VERSION ""

NS_ :

BS_:

BU_: TCM_Diesel ECM_Diesel BECMB_EPM TCM ECM Generic_BCM GWM _delete APIM BCM DCDC_VQM PAM TSTR PCM

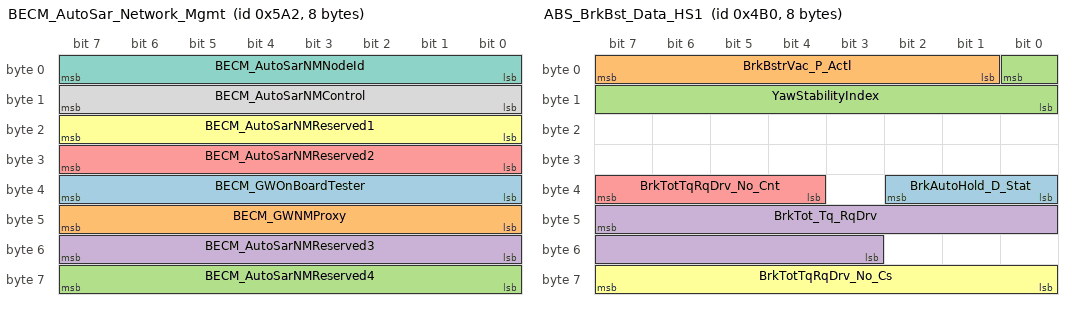
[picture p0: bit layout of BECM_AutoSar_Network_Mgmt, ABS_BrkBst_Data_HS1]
BO_ 1442 BECM_AutoSar_Network_Mgmt: 8 Generic_BCM
 SG_ BECM_GWOnBoardTester : 39|8@0+ (1,0) [0|255] "unitless"  GWM
 SG_ BECM_GWNMProxy : 47|8@0+ (1,0) [0|255] "unitless"  GWM
 SG_ BECM_AutoSarNMReserved4 : 63|8@0+ (1,0) [0|255] "unitless"  GWM
 SG_ BECM_AutoSarNMReserved3 : 55|8@0+ (1,0) [0|255] "unitless"  GWM
 SG_ BECM_AutoSarNMReserved2 : 31|8@0+ (1,0) [0|255] "unitless"  GWM
 SG_ BECM_AutoSarNMReserved1 : 23|8@0+ (1,0) [0|255] "unitless"  GWM
 SG_ BECM_AutoSarNMNodeId : 7|8@0+ (1,0) [0|255] "unitless"  GWM
 SG_ BECM_AutoSarNMControl : 15|8@0+ (1,0) [0|255] "unitless"  GWM

BO_ 1200 ABS_BrkBst_Data_HS1: 8 GWM
 SG_ BrkAutoHold_D_Stat : 34|3@0+ (1,0) [0|7] "SED"  ECM,PCM,ECM_Diesel
 SG_ BrkBstrVac_P_Actl : 7|7@0+ (8,0) [0|1008] "Millibar"  ECM_Diesel,ECM,PCM
 SG_ YawStabilityIndex : 0|9@0+ (1,-256) [-256|255] "%" Vector__XXX
 SG_ BrkTot_Tq_RqDrv : 47|13@0+ (4,0) [0|32760] "Nm"  ECM_Diesel,ECM,PCM
 SG_ BrkTotTqRqDrv_No_Cnt : 39|4@0+ (1,0) [0|15] "unitless"  ECM_Diesel,ECM,PCM
 SG_ BrkTotTqRqDrv_No_Cs : 63|8@0+ (1,0) [0|255] "unitless"  ECM_Diesel,ECM,PCM

BO_ 2015 TesterFunctionalReq_H1: 8 TSTR
 SG_ TesterFunctionalReq : 7|64@0+ (1,0) [0|1.84467E+019] ""  TCM_Diesel,APIM,ECM_Diesel,BECMB_EPM,TCM,ECM,DCDC_VQM,PAM,GWM,PCM,BCM

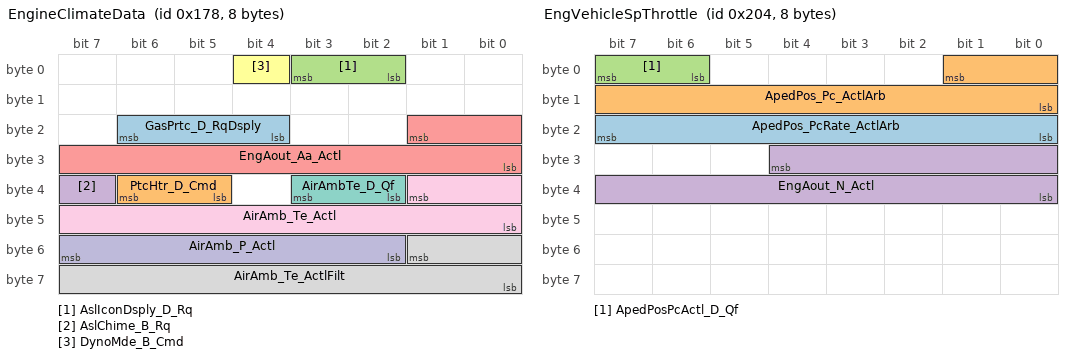
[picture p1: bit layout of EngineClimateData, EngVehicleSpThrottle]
BO_ 376 EngineClimateData: 8 PCM
 SG_ GasPrtc_D_RqDsply : 22|3@0+ (1,0) [0|7] "SED"  GWM
 SG_ PtcHtr_D_Cmd : 38|2@0+ (1,0) [0|3] "SED"  GWM
 SG_ AslIconDsply_D_Rq : 3|2@0+ (1,0) [0|3] "SED"  GWM
 SG_ AslChime_B_Rq : 39|1@0+ (1,0) [0|1] "SED"  GWM
 SG_ EngAout_Aa_Actl : 17|10@0+ (0.05,-25.6) [-25.6|25.55] "rpm/ms"  GWM
 SG_ DynoMde_B_Cmd : 4|1@0+ (1,0) [0|1] "SED"  GWM
 SG_ AirAmbTe_D_Qf : 35|2@0+ (1,0) [0|3] "SED"  GWM,PAM,BCM
 SG_ AirAmb_Te_ActlFilt : 49|10@0+ (0.25,-128) [-128|127.75] "deg C"  PAM,BCM,GWM
 SG_ AirAmb_Te_Actl : 33|10@0+ (0.25,-128) [-128|127.75] "degC"  PAM,GWM,BCM
 SG_ AirAmb_P_Actl : 55|6@0+ (10,500) [500|1110] "mbar"  TCM_Diesel,TCM,GWM,BCM

BO_ 516 EngVehicleSpThrottle: 8 PCM
 SG_ ApedPos_PcRate_ActlArb : 23|8@0+ (0.04,-5) [-5|5.12] "%/ms"  TCM_Diesel,TCM,GWM
 SG_ ApedPos_Pc_ActlArb : 1|10@0+ (0.1,0) [0|102.3] "%"  TCM_Diesel,TCM,BCM,GWM
 SG_ ApedPosPcActl_D_Qf : 7|2@0+ (1,0) [0|3] "SED"  TCM_Diesel,TCM,GWM
 SG_ EngAout_N_Actl : 28|13@0+ (2,0) [0|16382] "rpm"  TCM_Diesel,TCM,BCM,GWM

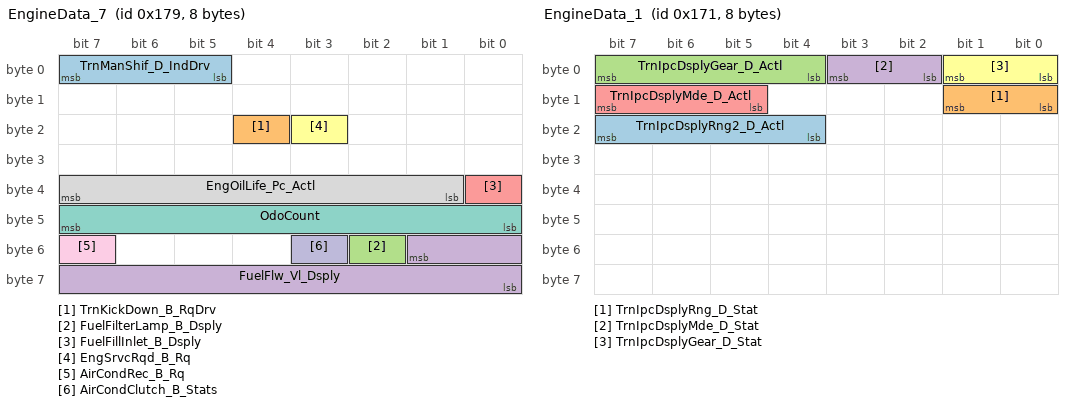
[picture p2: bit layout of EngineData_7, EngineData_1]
BO_ 377 EngineData_7: 8 PCM
 SG_ TrnManShif_D_IndDrv : 7|3@0+ (1,0) [0|7] "Unitless"  GWM
 SG_ TrnKickDown_B_RqDrv : 20|1@0+ (1,0) [0|1] "SED"  GWM
 SG_ FuelFilterLamp_B_Dsply : 50|1@0+ (1,0) [0|1] "SED"  GWM
 SG_ FuelFlw_Vl_Dsply : 49|10@0+ (25,0) [0|25575] "Micro_Liter"  GWM
 SG_ FuelFillInlet_B_Dsply : 32|1@0+ (1,0) [0|1] "SED"  GWM
 SG_ EngSrvcRqd_B_Rq : 19|1@0+ (1,0) [0|1] "SED"  GWM
 SG_ OdoCount : 47|8@0+ (0.2,0) [0|50.8] "Meters"  GWM
 SG_ EngOilLife_Pc_Actl : 39|7@0+ (1,0) [0|100] "Percent"  GWM
 SG_ AirCondRec_B_Rq : 55|1@0+ (1,0) [0|1] "SED"  GWM
 SG_ AirCondClutch_B_Stats : 51|1@0+ (1,0) [0|1] "SED"  GWM

BO_ 369 EngineData_1: 8 PCM
 SG_ TrnIpcDsplyRng2_D_Actl : 23|4@0+ (1,0) [0|15] "SED"  GWM
 SG_ TrnIpcDsplyRng_D_Stat : 9|2@0+ (1,0) [0|3] "SED"  GWM
 SG_ TrnIpcDsplyGear_D_Actl : 7|4@0+ (1,0) [0|15] "SED"  GWM
 SG_ TrnIpcDsplyMde_D_Stat : 3|2@0+ (1,0) [0|3] "SED"  GWM
 SG_ TrnIpcDsplyMde_D_Actl : 15|3@0+ (1,0) [0|7] "SED"  GWM
 SG_ TrnIpcDsplyGear_D_Stat : 1|2@0+ (1,0) [0|3] "SED"  GWM

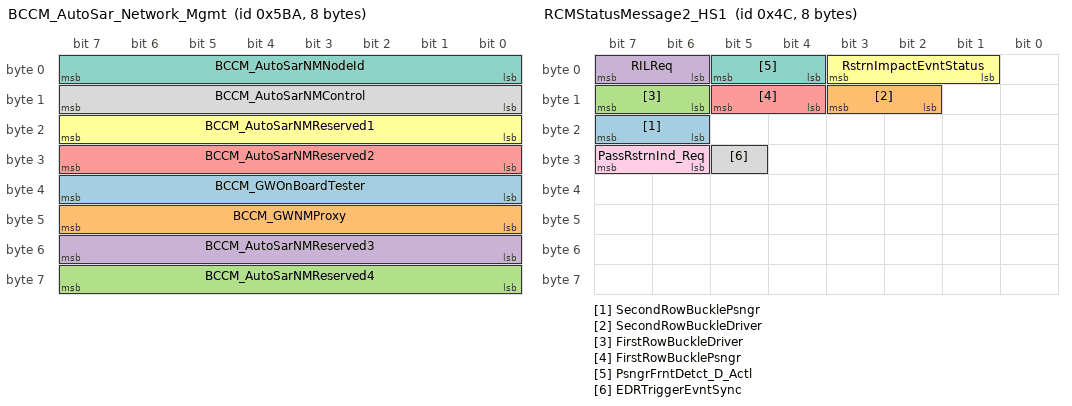
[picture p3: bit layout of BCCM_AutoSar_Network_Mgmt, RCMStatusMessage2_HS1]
BO_ 1466 BCCM_AutoSar_Network_Mgmt: 8 Generic_BCM
 SG_ BCCM_GWOnBoardTester : 39|8@0+ (1,0) [0|255] "unitless" Vector__XXX
 SG_ BCCM_GWNMProxy : 47|8@0+ (1,0) [0|255] "unitless" Vector__XXX
 SG_ BCCM_AutoSarNMReserved4 : 63|8@0+ (1,0) [0|255] "unitless" Vector__XXX
 SG_ BCCM_AutoSarNMReserved3 : 55|8@0+ (1,0) [0|255] "unitless" Vector__XXX
 SG_ BCCM_AutoSarNMReserved2 : 31|8@0+ (1,0) [0|255] "unitless" Vector__XXX
 SG_ BCCM_AutoSarNMReserved1 : 23|8@0+ (1,0) [0|255] "unitless" Vector__XXX
 SG_ BCCM_AutoSarNMNodeId : 7|8@0+ (1,0) [0|255] "unitless" Vector__XXX
 SG_ BCCM_AutoSarNMControl : 15|8@0+ (1,0) [0|255] "unitless" Vector__XXX

BO_ 76 RCMStatusMessage2_HS1: 8 GWM
 SG_ SecondRowBucklePsngr : 23|2@0+ (1,0) [0|3] "SED" Vector__XXX
 SG_ SecondRowBuckleDriver : 11|2@0+ (1,0) [0|3] "SED" Vector__XXX
 SG_ FirstRowBuckleDriver : 15|2@0+ (1,0) [0|3] "SED"  ECM_Diesel,ECM,BCM,PCM
 SG_ RILReq : 7|2@0+ (1,0) [0|3] "SED" Vector__XXX
 SG_ FirstRowBucklePsngr : 13|2@0+ (1,0) [0|3] "SED" Vector__XXX
 SG_ RstrnImpactEvntStatus : 3|3@0+ (1,0) [0|7] "SED"  ECM_Diesel,ECM,BCM,PCM
 SG_ PsngrFrntDetct_D_Actl : 5|2@0+ (1,0) [0|3] "SED" Vector__XXX
 SG_ EDRTriggerEvntSync : 29|1@0+ (1,0) [0|1] "SED" Vector__XXX
 SG_ PassRstrnInd_Req : 31|2@0+ (1,0) [0|3] "SED" Vector__XXX

BO_ 2008 TesterPhysicalResAPIM: 8 APIM
 SG_ TesterPhysicalResAPIM : 7|64@0+ (1,0) [0|1.84467E+019] "unitless"  TSTR

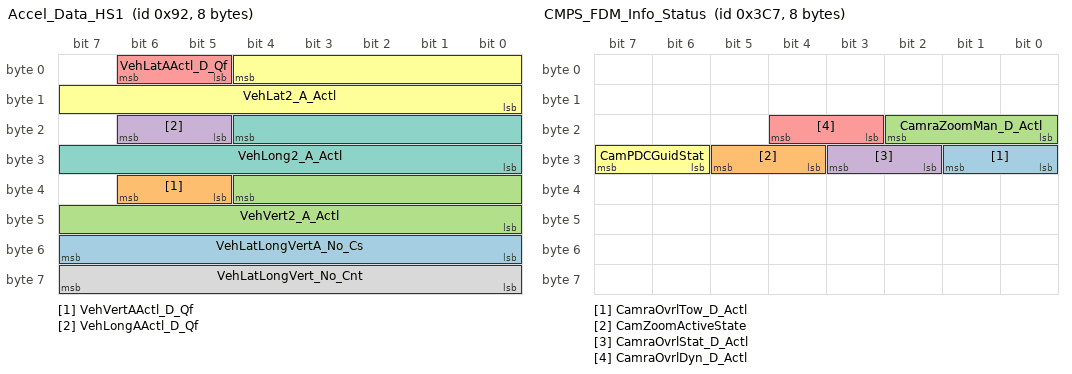
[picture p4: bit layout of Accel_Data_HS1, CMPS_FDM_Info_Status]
BO_ 146 Accel_Data_HS1: 8 GWM
 SG_ VehLatLongVertA_No_Cs : 55|8@0+ (1,0) [0|255] "Unitless" Vector__XXX
 SG_ VehVertAActl_D_Qf : 38|2@0+ (1,0) [0|3] "SED" Vector__XXX
 SG_ VehVert2_A_Actl : 36|13@0+ (0.01,-40) [-40|41.89] "m/s^2" Vector__XXX
 SG_ VehLongAActl_D_Qf : 22|2@0+ (1,0) [0|3] "SED"  ECM_Diesel,PAM
 SG_ VehLatAActl_D_Qf : 6|2@0+ (1,0) [0|3] "SED"  ECM_Diesel
 SG_ VehLat2_A_Actl : 4|13@0+ (0.01,-40) [-40|41.89] "m/s^2"  ECM_Diesel
 SG_ VehLong2_A_Actl : 20|13@0+ (0.01,-40) [-40|41.89] "m/s^2"  ECM_Diesel,PAM
 SG_ VehLatLongVert_No_Cnt : 63|8@0+ (1,0) [0|255] "Unitless" Vector__XXX

BO_ 1870 TesterPhysicalResDCDC: 8 DCDC_VQM
 SG_ TesterPhysicalResDCDC : 7|64@0+ (1,0) [0|1.84467E+019] "unitless"  TSTR

BO_ 1862 TesterPhysicalReqDCDC: 8 TSTR
 SG_ TesterPhysicalReqDCDC : 7|64@0+ (1,0) [0|1.84467E+019] "unitless"  DCDC_VQM

BO_ 1697 PCM_Rapid_Data_Response_2: 8 PCM
 SG_ UUDTPCMResponse2 : 7|64@0+ (1,0) [0|1.844674407371E+019] "unitless"  TSTR

BO_ 1696 PCM_Rapid_Data_Response_1: 8 PCM
 SG_ UUDTPCMResponse1 : 7|64@0+ (1,0) [0|1.844674407371E+019] "unitless"  TSTR

BO_ 967 CMPS_FDM_Info_Status: 8 BCM
 SG_ CamraOvrlTow_D_Actl : 25|2@0+ (1,0) [0|3] "SED"  GWM
 SG_ CamZoomActiveState : 29|2@0+ (1,0) [0|3] "SED"  GWM
 SG_ CamraZoomMan_D_Actl : 18|3@0+ (1,0) [0|7] "SED"  GWM
 SG_ CamraOvrlStat_D_Actl : 27|2@0+ (1,0) [0|3] "SED"  GWM
 SG_ CamraOvrlDyn_D_Actl : 20|2@0+ (1,0) [0|3] "SED"  GWM
 SG_ CamPDCGuidStat : 31|2@0+ (1,0) [0|3] "SED"  GWM

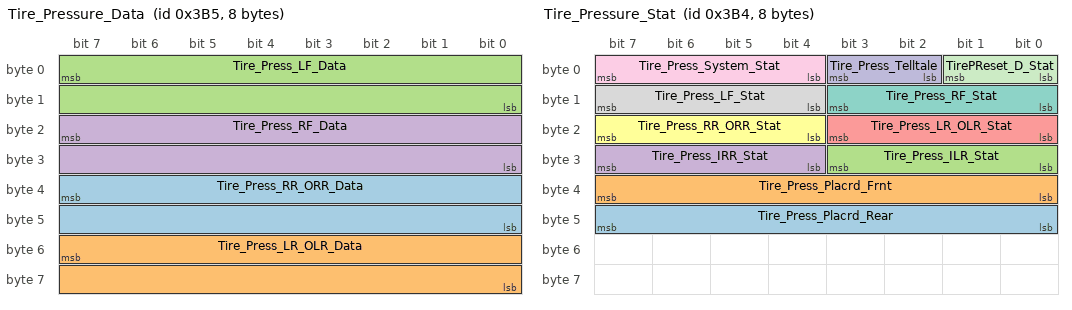
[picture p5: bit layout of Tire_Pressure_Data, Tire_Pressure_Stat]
BO_ 949 Tire_Pressure_Data: 8 BCM
 SG_ Tire_Press_RR_ORR_Data : 39|16@0+ (1,0) [0|65533] "kilopascal"  GWM
 SG_ Tire_Press_LR_OLR_Data : 55|16@0+ (1,0) [0|65533] "kilopascal"  GWM
 SG_ Tire_Press_LF_Data : 7|16@0+ (1,0) [0|65533] "kilopascal"  GWM
 SG_ Tire_Press_RF_Data : 23|16@0+ (1,0) [0|65533] "kilopascal"  GWM

BO_ 948 Tire_Pressure_Stat: 8 BCM
 SG_ Tire_Press_Placrd_Rear : 47|8@0+ (1,0) [0|255] "Unitless"  GWM
 SG_ Tire_Press_Placrd_Frnt : 39|8@0+ (1,0) [0|255] "Unitless"  GWM
 SG_ Tire_Press_ILR_Stat : 27|4@0+ (1,0) [0|15] "SED"  GWM
 SG_ Tire_Press_IRR_Stat : 31|4@0+ (1,0) [0|15] "SED"  GWM
 SG_ Tire_Press_LR_OLR_Stat : 19|4@0+ (1,0) [0|15] "SED"  GWM
 SG_ Tire_Press_RR_ORR_Stat : 23|4@0+ (1,0) [0|15] "SED"  GWM
 SG_ Tire_Press_RF_Stat : 11|4@0+ (1,0) [0|15] "SED"  GWM
 SG_ Tire_Press_LF_Stat : 15|4@0+ (1,0) [0|15] "SED"  GWM
 SG_ Tire_Press_System_Stat : 7|4@0+ (1,0) [0|15] "SED"  GWM
 SG_ Tire_Press_Telltale : 3|2@0+ (1,0) [0|3] "SED"  GWM
 SG_ TirePReset_D_Stat : 1|2@0+ (1,0) [0|3] "Discrete"  GWM

BO_ 1077 Cluster_Info4_HS1: 8 GWM
 SG_ PtDrvMde_D_Rq_UB : 57|1@0+ (1,0) [0|1] "SED" Vector__XXX
 SG_ PtDrvMde_D_Rq : 61|4@0+ (1,0) [0|15] "SED"  ECM,ECM_Diesel
 SG_ TrlrBrkActCnnct_B_Actl_UB : 62|1@0+ (1,0) [0|1] "SED"  ECM,PCM
 SG_ TrlrBrkActCnnct_B_Actl : 63|1@0+ (1,0) [0|1] "SED"  ECM,PCM
 SG_ PrkLckCtlEnbl_D_RqIpc_UB : 48|1@0+ (1,0) [0|1] "SED"  BCM
 SG_ PrkLckCtlEnbl_D_RqIpc : 50|2@0+ (1,0) [0|3] "SED"  BCM
 SG_ AutoRgen_D_Rq_UB : 51|1@0+ (1,0) [0|1] "SED" Vector__XXX
 SG_ AutoRgen_D_Rq : 41|2@0+ (1,0) [0|3] "SED"  ECM_Diesel
 SG_ FuelLvl_Pc_Dsply_UB : 45|1@0+ (1,0) [0|1] "SED" Vector__XXX
 SG_ StopStrtDrvMde_D_RqMnu_UB : 26|1@0+ (1,0) [0|1] "SED" Vector__XXX
 SG_ StopStrtDrvMde_D_RqMnu : 47|2@0+ (1,0) [0|3] "SED"  ECM_Diesel,ECM,PCM
 SG_ PtWakeupActv1_B_Rq : 44|1@0+ (1,0) [0|1] "SED"  BCM
 SG_ PtWakeupActv1_B_Rq_UB : 43|1@0+ (1,0) [0|1] "SED"  BCM
 SG_ PrkAidRear_D_RqDrv : 29|2@0+ (1,0) [0|3] "SED"  PAM
 SG_ PrkAidFront_D_RqDrv : 21|2@0+ (1,0) [0|3] "SED"  PAM
 SG_ PrkAidRear_D_RqDrv_UB : 27|1@0+ (1,0) [0|1] "SED"  PAM
 SG_ PrkAidFront_D_RqDrv_UB : 19|1@0+ (1,0) [0|1] "SED"  PAM
 SG_ Multimedia_System_UB : 30|1@0+ (1,0) [0|1] "SED"  BCM
 SG_ Multimedia_System : 31|1@0+ (1,0) [0|1] "SED"  BCM
 SG_ Remote_Start_Req_UB : 23|1@0+ (1,0) [0|1] "SED"  BCM
 SG_ Remote_Start_Req : 9|2@0+ (1,0) [0|3] "SED"  BCM
 SG_ TurnLampTrlrRr_B_Stat_UB : 16|1@0+ (1,0) [0|1] "SED"  BCM
 SG_ DistanceBarSetting_UB : 12|1@0+ (1,0) [0|1] "SED"  BCM
 SG_ CamraZoomMan_D_Rq_UB : 14|1@0+ (1,0) [0|1] "SED"  BCM
 SG_ CamraOvrlStat_D_Rq_UB : 2|1@0+ (1,0) [0|1] "SED"  BCM
 SG_ CamraOvrlDyn_D_Rq_UB : 4|1@0+ (1,0) [0|1] "SED"  BCM
 SG_ CamAutoTowbarZoom_UB : 6|1@0+ (1,0) [0|1] "SED"  BCM
 SG_ DistanceBarSetting : 13|1@0+ (1,0) [0|1] "SED"  BCM
 SG_ CamraZoomMan_D_Rq : 1|3@0+ (1,0) [0|7] "SED"  BCM
 SG_ CamraOvrlStat_D_Rq : 3|1@0+ (1,0) [0|1] "SED"  BCM
 SG_ CamraOvrlDyn_D_Rq : 5|1@0+ (1,0) [0|1] "SED"  BCM
 SG_ CamAutoTowbarZoom : 7|1@0+ (1,0) [0|1] "SED"  BCM
 SG_ CcdMsgTxt_D_RqDsply : 55|4@0+ (1,0) [0|15] "SED" Vector__XXX
 SG_ PwLftgtIntSw_B_Stat_UB : 10|1@0+ (1,0) [0|1] "SED"  BCM
 SG_ PwLftgtIntSw_B_Stat : 11|1@0+ (1,0) [0|1] "SED"  BCM
 SG_ TurnLampTrlrRl_B_Stat_UB : 18|1@0+ (1,0) [0|1] "SED"  BCM
 SG_ TurnLampTrlrRr_B_Stat : 17|1@0+ (1,0) [0|1] "SED"  BCM
 SG_ TurnLampTrlrRl_B_Stat : 22|1@0+ (1,0) [0|1] "SED"  BCM
 SG_ FuelLvl_Pc_Dsply : 25|10@0+ (0.108696,-5.217408) [-5.217408|105.9786] "Percent"  ECM_Diesel

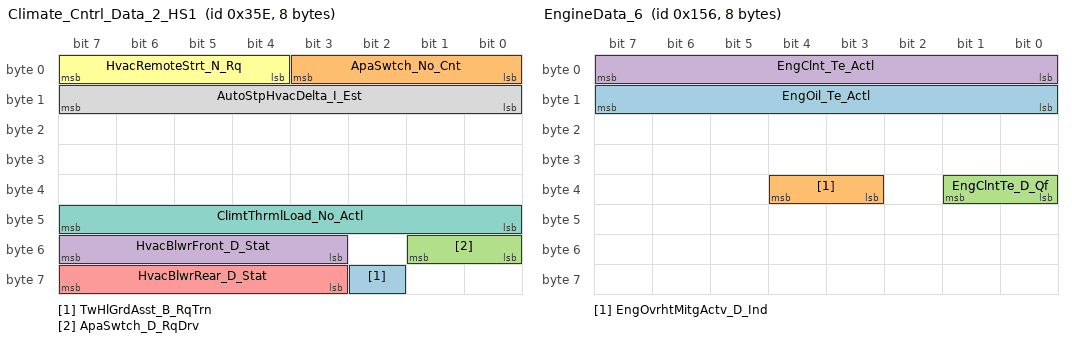
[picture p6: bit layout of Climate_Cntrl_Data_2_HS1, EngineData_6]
BO_ 862 Climate_Cntrl_Data_2_HS1: 8 GWM
 SG_ TwHlGrdAsst_B_RqTrn : 58|1@0+ (1,0) [0|1] "SED" Vector__XXX
 SG_ ApaSwtch_No_Cnt : 3|4@0+ (1,0) [0|15] "Unitless"  PAM
 SG_ ApaSwtch_D_RqDrv : 49|2@0+ (1,0) [0|3] "SED"  PAM
 SG_ HvacBlwrFront_D_Stat : 55|5@0+ (1,0) [0|31] "SED"  ECM_Diesel,PCM,BCM
 SG_ HvacBlwrRear_D_Stat : 63|5@0+ (1,0) [0|31] "SED"  ECM_Diesel,PCM,BCM
 SG_ HvacRemoteStrt_N_Rq : 7|4@0+ (100,450) [450|1950] "RPM"  ECM_Diesel,ECM,PCM
 SG_ ClimtThrmlLoad_No_Actl : 47|8@0+ (1,0) [0|254] "unitless"  ECM_Diesel
 SG_ AutoStpHvacDelta_I_Est : 15|8@0+ (1,-192) [-192|62] "ampere"  BCM

BO_ 342 EngineData_6: 8 PCM
 SG_ EngOil_Te_Actl : 15|8@0+ (1,-60) [-60|193] "degC"  GWM
 SG_ EngOvrhtMitgActv_D_Ind : 36|2@0+ (1,0) [0|3] "SED"  GWM
 SG_ EngClntTe_D_Qf : 33|2@0+ (1,0) [0|3] "SED"  TCM_Diesel,TCM,GWM,BCM
 SG_ EngClnt_Te_Actl : 7|8@0+ (1,-60) [-60|195] "degC"  TCM_Diesel,TCM,GWM,BCM

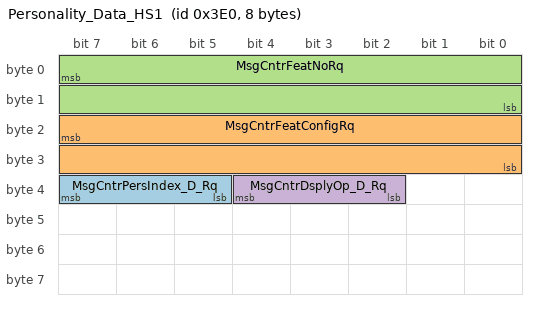
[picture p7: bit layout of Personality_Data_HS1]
BO_ 992 Personality_Data_HS1: 8 GWM
 SG_ MsgCntrPersIndex_D_Rq : 39|3@0+ (1,0) [0|7] "SED"  BCM
 SG_ MsgCntrFeatConfigRq : 23|16@0+ (1,0) [0|65535] "Undefined"  BCM
 SG_ MsgCntrFeatNoRq : 7|16@0+ (1,0) [0|65535] "Number"  BCM
 SG_ MsgCntrDsplyOp_D_Rq : 36|3@0+ (1,0) [0|7] "SED"  BCM

BO_TX_BU_ 376 : ECM_Diesel,ECM,PCM;
BO_TX_BU_ 516 : ECM_Diesel,ECM,PCM;
BO_TX_BU_ 377 : ECM_Diesel,ECM,PCM;
BO_TX_BU_ 369 : TCM_Diesel,TCM,PCM;
BO_TX_BU_ 1697 : ECM_Diesel,ECM,PCM;
BO_TX_BU_ 1696 : ECM_Diesel,ECM,PCM;
BO_TX_BU_ 342 : ECM_Diesel,ECM,PCM;
CM_ SG_ 1442 BECM_GWOnBoardTester "Signal not transmitted on gas, diesel and HEV.  Only supported on PHEV.";
CM_ SG_ 1442 BECM_GWNMProxy "Signal not transmitted on gas, diesel and HEV.  Only supported on PHEV.";
CM_ SG_ 1442 BECM_AutoSarNMReserved4 "Signal not transmitted on gas, diesel and HEV.  Only supported on PHEV.";
CM_ SG_ 1442 BECM_AutoSarNMReserved3 "Signal not transmitted on gas, diesel and HEV.  Only supported on PHEV.";
CM_ SG_ 1442 BECM_AutoSarNMReserved2 "Signal not transmitted on gas, diesel and HEV.  Only supported on PHEV.";
CM_ SG_ 1442 BECM_AutoSarNMReserved1 "Signal not transmitted on gas, diesel and HEV.  Only supported on PHEV.";
CM_ SG_ 1442 BECM_AutoSarNMNodeId "Signal not transmitted on gas, diesel and HEV.  Only supported on PHEV.";
CM_ SG_ 1442 BECM_AutoSarNMControl "Signal not transmitted on gas, diesel and HEV.  Only supported on PHEV.";
CM_ BO_ 2015 "OBDII Request ($7DF) messages are for FNOS 1.0.1 only.
Diagnostic Functional Addressing ($7DF) and Dual Rate Periodic messages are for FNOS I3 only.";
CM_ SG_ 376 GasPrtc_D_RqDsply "ECM_Gas Tx Only, PCM and ECM_Diesel do not support";
CM_ SG_ 376 PtcHtr_D_Cmd "ECM_D Tx on P552";
CM_ SG_ 376 AslIconDsply_D_Rq "Signal not transmitted by gas variants
";
CM_ SG_ 376 AslChime_B_Rq "Signal not transmitted by gas variants";
CM_ SG_ 376 EngAout_Aa_Actl "Signal not transmitted on HEV variants.";
CM_ SG_ 516 ApedPos_Pc_ActlArb "ABSGenSigTimeoutTime=1000";
CM_ SG_ 377 TrnManShif_D_IndDrv "ECM_D Tx only on P552";
CM_ SG_ 377 TrnKickDown_B_RqDrv "ECM_D Tx only on P552
";
CM_ SG_ 377 FuelFilterLamp_B_Dsply "ECM_D Tx only on P552";
CM_ SG_ 377 FuelFlw_Vl_Dsply "Signal not transmitted on diesel variants.";
CM_ SG_ 377 FuelFillInlet_B_Dsply "Signal not transmitted on diesel variants.";
CM_ SG_ 377 OdoCount "Signal not transmitted on diesel variants.";
CM_ SG_ 377 EngOilLife_Pc_Actl "Signal not transmitted on diesel variants.";
CM_ SG_ 377 AirCondRec_B_Rq "Signal not transmitted on diesel variants.";
CM_ SG_ 377 AirCondClutch_B_Stats "Signal not transmitted on diesel variants.";
CM_ SG_ 1466 BCCM_GWOnBoardTester "Signal not transmitted on gas, diesel and HEV.  Only supported on PHEV.";
CM_ SG_ 1466 BCCM_GWNMProxy "Signal not transmitted on gas, diesel and HEV.  Only supported on PHEV.";
CM_ SG_ 1466 BCCM_AutoSarNMReserved4 "Signal not transmitted on gas, diesel and HEV.  Only supported on PHEV.";
CM_ SG_ 1466 BCCM_AutoSarNMReserved3 "Signal not transmitted on gas, diesel and HEV.  Only supported on PHEV.";
CM_ SG_ 1466 BCCM_AutoSarNMReserved2 "Signal not transmitted on gas, diesel and HEV.  Only supported on PHEV.";
CM_ SG_ 1466 BCCM_AutoSarNMReserved1 "Signal not transmitted on gas, diesel and HEV.  Only supported on PHEV.";
CM_ SG_ 1466 BCCM_AutoSarNMNodeId "Signal not transmitted on gas, diesel and HEV.  Only supported on PHEV.";
CM_ SG_ 1466 BCCM_AutoSarNMControl "Signal not transmitted on gas, diesel and HEV.  Only supported on PHEV.";
CM_ BO_ 967 "2008' programs, Tx by IC;  updated on 5/6/05";
CM_ BO_ 949 "For 2010MY and beyond, use for SCT (non-CGEA) and CGEA modules";
CM_ BO_ 948 "$3B4 used by CGEA SPDJB";
CM_ SG_ 342 EngOil_Te_Actl "Tx by ECM_G and ECM_D only";
CM_ SG_ 342 EngOvrhtMitgActv_D_Ind "Signal not transmitted on diesel.";
BA_DEF_ SG_  "U_V408_MY18_Gas_Rx" ENUM  "No","Yes";
BA_DEF_ SG_  "U_V408_MY18_Diesel_Rx" ENUM  "No","Yes";
BA_DEF_ SG_  "U_CD4_MY18_Gas_Tx" ENUM  "No","Yes";
BA_DEF_ SG_  "U_S550_MY18_Gas_Tx" ENUM  "No","Yes";
BA_DEF_ SG_  "U_V408_MY18_Gas_Tx" ENUM  "No","Yes";
BA_DEF_ SG_  "U_V408_MY18_Diesel_Tx" ENUM  "No","Yes";
BA_DEF_ SG_  "U_P552_MY18_5_Diesel_Tx" ENUM  "No","Yes";
BA_DEF_ SG_  "U_U55x_MY18_Gas_Rx" ENUM  "No","Yes";
BA_DEF_ SG_  "U_U55x_MY18_Gas_Tx" ENUM  "No","Yes";
BA_DEF_ BO_  "FrameGatewayNetwork" STRING ;
BA_DEF_ SG_  "U_C489_MY17_Gas_Rx" ENUM  "No","Yes";
BA_DEF_ SG_  "U_CD43_MY17_Gas_Rx" ENUM  "No","Yes";
BA_DEF_ SG_  "U_P552_MY17_Gas_Rx" ENUM  "No","Yes";
BA_DEF_ SG_  "U_B515_MCA_MY17_Diesel_Rx" ENUM  "No","Yes";
BA_DEF_ SG_  "U_B515_MCA_MY17_Gas_Rx" ENUM  "No","Yes";
BA_DEF_ SG_  "U_C489_MY17_Gas_Tx" ENUM  "No","Yes";
BA_DEF_ SG_  "U_CD43_MY17_Gas_Tx" ENUM  "No","Yes";
BA_DEF_ SG_  "U_B515_MCA_MY17_Diesel_Tx" ENUM  "No","Yes";
BA_DEF_ SG_  "U_B515_MCA_MY17_Gas_Tx" ENUM  "No","Yes";
BA_DEF_ SG_  "U_CD4_MY17_Diesel_Rx" ENUM  "No","Yes";
BA_DEF_ SG_  "U_CD4_MY17_Gas_Rx" ENUM  "No","Yes";
BA_DEF_ SG_  "U_CD4_MY17_Hev_Rx" ENUM  "No","Yes";
BA_DEF_ SG_  "U_CD4_MY17_Phev_Rx" ENUM  "No","Yes";
BA_DEF_ SG_  "U_CD42_MY16_Diesel_Rx" ENUM  "No","Yes";
BA_DEF_ SG_  "U_CD42_MY16_Gas_Rx" ENUM  "No","Yes";
BA_DEF_ SG_  "U_CD4_MY17_Gas_Tx" ENUM  "No","Yes";
BA_DEF_ SG_  "U_CD4_MY17_Hev_Tx" ENUM  "No","Yes";
BA_DEF_ SG_  "U_CD4_MY17_Phev_Tx" ENUM  "No","Yes";
BA_DEF_ SG_  "U_CD42_MY16_Diesel_Tx" ENUM  "No","Yes";
BA_DEF_ SG_  "U_CD42_MY16_Gas_Tx" ENUM  "No","Yes";
BA_DEF_ SG_  "U_CD42_MY15_Diesel_Rx" ENUM  "No","Yes";
BA_DEF_ SG_  "U_CD42_MY15_Gas_Rx" ENUM  "No","Yes";
BA_DEF_ SG_  "U_U502_MY16_Gas_Rx" ENUM  "No","Yes";
BA_DEF_ SG_  "U_P558_MY17_Gas_Rx" ENUM  "No","Yes";
BA_DEF_ SG_  "U_P558_MY17_Diesel_Rx" ENUM  "No","Yes";
BA_DEF_ SG_  "U_V36X_MY16_5_Diesel_Rx" ENUM  "No","Yes";
BA_DEF_ SG_  "U_CD42_MY15_Diesel_Tx" ENUM  "No","Yes";
BA_DEF_ SG_  "U_CD42_MY15_Gas_Tx" ENUM  "No","Yes";
BA_DEF_ SG_  "U_P558_MY17_Gas_Tx" ENUM  "No","Yes";
BA_DEF_ SG_  "U_P558_MY17_Diesel_Tx" ENUM  "No","Yes";
BA_DEF_ SG_  "U_V36X_MY16_5_Diesel_Tx" ENUM  "No","Yes";
BA_DEF_ SG_  "GenSigTimeoutTime_TCM" INT 0 100000;
BA_DEF_ SG_  "Gateway_ID" INT 0 0;
BA_DEF_ BO_  "FrameGatewayMS1" HEX 0 1407;
BA_DEF_ BO_  "FrameGatewayHS3" HEX 0 1407;
BA_DEF_ BO_  "FrameGatewayHS2" HEX 0 1407;
BA_DEF_ BO_  "NetworkInitialization" ENUM  "No","Yes";
BA_DEF_ BO_  "FrameGatewayId" HEX 0 1407;
BA_DEF_ BO_  "GenMsgStartDelayTime" INT 0 10000;
BA_DEF_ BO_  "GenMsgDelayTime" INT 0 1000;
BA_DEF_ BO_  "GenMsgCycleTime" INT 0 100000;
BA_DEF_ BO_  "GenMsgSendType" ENUM  "FixedPeriodic","Event","EnabledPeriodic","NotUsed","NotUsed","EventPeriodic","NotUsed","NotUsed","NoMsgSendType";
BA_DEF_ SG_  "U_CD4_MY14_Phev_Tx" ENUM  "No","Yes";
BA_DEF_ SG_  "U_CD4_MY14_Hev_Tx" ENUM  "No","Yes";
BA_DEF_ SG_  "U_CD4_MY14_Gas_Tx" ENUM  "No","Yes";
BA_DEF_ SG_  "U_CD4_MY14_Diesel_Tx" ENUM  "No","Yes";
BA_DEF_ SG_  "U_CD43_MY16_Gas_Tx" ENUM  "No","Yes";
BA_DEF_ SG_  "U_UP375_MY15_Diesel_Tx" ENUM  "No","Yes";
BA_DEF_ SG_  "U_UP375_MY15_Gas_Tx" ENUM  "No","Yes";
BA_DEF_ SG_  "U_U502_MY15_Gas_Tx" ENUM  "No","Yes";
BA_DEF_ SG_  "U_C489_MY14_Gas_Tx" ENUM  "No","Yes";
BA_DEF_ SG_  "U_S550_MY15_Gas_Tx" ENUM  "No","Yes";
BA_DEF_ SG_  "U_P552_MY15_Gas_Tx" ENUM  "No","Yes";
BA_DEF_ SG_  "U_CD42_MY14_Gas_Tx" ENUM  "No","Yes";
BA_DEF_ SG_  "U_CD42_MY14_Diesel_Tx" ENUM  "No","Yes";
BA_DEF_ SG_  "U_CD4_MY13_Phev_Tx" ENUM  "No","Yes";
BA_DEF_ SG_  "U_CD4_MY13_Hev_Tx" ENUM  "No","Yes";
BA_DEF_ SG_  "U_CD4_MY13_Gas_Tx" ENUM  "No","Yes";
BA_DEF_ SG_  "U_CD4_MY13_Diesel_Tx" ENUM  "No","Yes";
BA_DEF_ SG_  "U_CD4_MY14_Phev_Rx" ENUM  "No","Yes";
BA_DEF_ SG_  "U_CD4_MY14_Hev_Rx" ENUM  "No","Yes";
BA_DEF_ SG_  "U_CD4_MY14_Gas_Rx" ENUM  "No","Yes";
BA_DEF_ SG_  "U_CD4_MY14_Diesel_Rx" ENUM  "No","Yes";
BA_DEF_ SG_  "U_CD43_MY16_Gas_Rx" ENUM  "No","Yes";
BA_DEF_ SG_  "U_UP375_MY15_Diesel_Rx" ENUM  "No","Yes";
BA_DEF_ SG_  "U_UP375_MY15_Gas_Rx" ENUM  "No","Yes";
BA_DEF_ SG_  "U_B479_MY15_Gas_Rx" ENUM  "No","Yes";
BA_DEF_ SG_  "U_U502_MY15_Gas_Rx" ENUM  "No","Yes";
BA_DEF_ SG_  "U_C489_MY14_Gas_Rx" ENUM  "No","Yes";
BA_DEF_ SG_  "U_S550_MY15_Gas_Rx" ENUM  "No","Yes";
BA_DEF_ SG_  "U_P552_MY15_Gas_Rx" ENUM  "No","Yes";
BA_DEF_ SG_  "U_CD42_MY14_Gas_Rx" ENUM  "No","Yes";
BA_DEF_ SG_  "U_CD42_MY14_Diesel_Rx" ENUM  "No","Yes";
BA_DEF_ SG_  "U_CD4_MY13_Phev_Rx" ENUM  "No","Yes";
BA_DEF_ SG_  "U_CD4_MY13_Hev_Rx" ENUM  "No","Yes";
BA_DEF_ SG_  "U_CD4_MY13_Gas_Rx" ENUM  "No","Yes";
BA_DEF_ SG_  "U_CD4_MY13_Diesel_Rx" ENUM  "No","Yes";
BA_DEF_ SG_  "ContentDependant" ENUM  "No","Yes";
BA_DEF_ SG_  "GenSigStartValue" INT 0 1000000000;
BA_DEF_ SG_  "CrossOver_LIN" ENUM  "No","Yes";
BA_DEF_ SG_  "CrossOver_InfoCAN" ENUM  "No","Yes";
BA_DEF_ SG_  "WakeupSignal" ENUM  "No","Yes";
BA_DEF_ SG_  "GenSigSendType" ENUM  "Cyclic","OnWrite","vector_leerstring","OnChange","vector_leerstring","IfActive","vector_leerstring","NoSigSendType";
BA_DEF_ BO_  "TpApplType" STRING ;
BA_DEF_ BO_  "DiagState" ENUM  "No","Yes";
BA_DEF_ BO_  "DiagRequest" ENUM  "No","Yes";
BA_DEF_ BO_  "DiagResponse" ENUM  "No","Yes";
BA_DEF_ BO_  "GenMsgILSupport" ENUM  "No","Yes";
BA_DEF_DEF_  "U_V408_MY18_Gas_Rx" "No";
BA_DEF_DEF_  "U_V408_MY18_Diesel_Rx" "No";
BA_DEF_DEF_  "U_CD4_MY18_Gas_Tx" "No";
BA_DEF_DEF_  "U_S550_MY18_Gas_Tx" "No";
BA_DEF_DEF_  "U_V408_MY18_Gas_Tx" "No";
BA_DEF_DEF_  "U_V408_MY18_Diesel_Tx" "No";
BA_DEF_DEF_  "U_P552_MY18_5_Diesel_Tx" "No";
BA_DEF_DEF_  "U_U55x_MY18_Gas_Rx" "No";
BA_DEF_DEF_  "U_U55x_MY18_Gas_Tx" "No";
BA_DEF_DEF_  "FrameGatewayNetwork" "NONE";
BA_DEF_DEF_  "U_C489_MY17_Gas_Rx" "No";
BA_DEF_DEF_  "U_CD43_MY17_Gas_Rx" "No";
BA_DEF_DEF_  "U_P552_MY17_Gas_Rx" "No";
BA_DEF_DEF_  "U_B515_MCA_MY17_Diesel_Rx" "No";
BA_DEF_DEF_  "U_B515_MCA_MY17_Gas_Rx" "No";
BA_DEF_DEF_  "U_C489_MY17_Gas_Tx" "No";
BA_DEF_DEF_  "U_CD43_MY17_Gas_Tx" "No";
BA_DEF_DEF_  "U_B515_MCA_MY17_Diesel_Tx" "No";
BA_DEF_DEF_  "U_B515_MCA_MY17_Gas_Tx" "No";
BA_DEF_DEF_  "U_CD4_MY17_Diesel_Rx" "No";
BA_DEF_DEF_  "U_CD4_MY17_Gas_Rx" "No";
BA_DEF_DEF_  "U_CD4_MY17_Hev_Rx" "No";
BA_DEF_DEF_  "U_CD4_MY17_Phev_Rx" "No";
BA_DEF_DEF_  "U_CD42_MY16_Diesel_Rx" "No";
BA_DEF_DEF_  "U_CD42_MY16_Gas_Rx" "No";
BA_DEF_DEF_  "U_CD4_MY17_Gas_Tx" "No";
BA_DEF_DEF_  "U_CD4_MY17_Hev_Tx" "No";
BA_DEF_DEF_  "U_CD4_MY17_Phev_Tx" "No";
BA_DEF_DEF_  "U_CD42_MY16_Diesel_Tx" "No";
BA_DEF_DEF_  "U_CD42_MY16_Gas_Tx" "No";
BA_DEF_DEF_  "U_CD42_MY15_Diesel_Rx" "No";
BA_DEF_DEF_  "U_CD42_MY15_Gas_Rx" "No";
BA_DEF_DEF_  "U_U502_MY16_Gas_Rx" "No";
BA_DEF_DEF_  "U_P558_MY17_Gas_Rx" "No";
BA_DEF_DEF_  "U_P558_MY17_Diesel_Rx" "No";
BA_DEF_DEF_  "U_V36X_MY16_5_Diesel_Rx" "No";
BA_DEF_DEF_  "U_CD42_MY15_Diesel_Tx" "No";
BA_DEF_DEF_  "U_CD42_MY15_Gas_Tx" "No";
BA_DEF_DEF_  "U_P558_MY17_Gas_Tx" "No";
BA_DEF_DEF_  "U_P558_MY17_Diesel_Tx" "No";
BA_DEF_DEF_  "U_V36X_MY16_5_Diesel_Tx" "No";
BA_DEF_DEF_  "GenSigTimeoutTime_TCM" 5000;
BA_DEF_DEF_  "Gateway_ID" 0;
BA_DEF_DEF_  "FrameGatewayMS1" 0;
BA_DEF_DEF_  "FrameGatewayHS3" 0;
BA_DEF_DEF_  "FrameGatewayHS2" 0;
BA_DEF_DEF_  "NetworkInitialization" "No";
BA_DEF_DEF_  "FrameGatewayId" 0;
BA_DEF_DEF_  "GenMsgStartDelayTime" 0;
BA_DEF_DEF_  "GenMsgDelayTime" 20;
BA_DEF_DEF_  "GenMsgCycleTime" 0;
BA_DEF_DEF_  "GenMsgSendType" "NoMsgSendType";
BA_DEF_DEF_  "U_CD4_MY14_Phev_Tx" "No";
BA_DEF_DEF_  "U_CD4_MY14_Hev_Tx" "No";
BA_DEF_DEF_  "U_CD4_MY14_Gas_Tx" "No";
BA_DEF_DEF_  "U_CD4_MY14_Diesel_Tx" "No";
BA_DEF_DEF_  "U_CD43_MY16_Gas_Tx" "No";
BA_DEF_DEF_  "U_UP375_MY15_Diesel_Tx" "No";
BA_DEF_DEF_  "U_UP375_MY15_Gas_Tx" "No";
BA_DEF_DEF_  "U_U502_MY15_Gas_Tx" "No";
BA_DEF_DEF_  "U_C489_MY14_Gas_Tx" "No";
BA_DEF_DEF_  "U_S550_MY15_Gas_Tx" "No";
BA_DEF_DEF_  "U_P552_MY15_Gas_Tx" "No";
BA_DEF_DEF_  "U_CD42_MY14_Gas_Tx" "No";
BA_DEF_DEF_  "U_CD42_MY14_Diesel_Tx" "No";
BA_DEF_DEF_  "U_CD4_MY13_Phev_Tx" "No";
BA_DEF_DEF_  "U_CD4_MY13_Hev_Tx" "No";
BA_DEF_DEF_  "U_CD4_MY13_Gas_Tx" "No";
BA_DEF_DEF_  "U_CD4_MY13_Diesel_Tx" "No";
BA_DEF_DEF_  "U_CD4_MY14_Phev_Rx" "No";
BA_DEF_DEF_  "U_CD4_MY14_Hev_Rx" "No";
BA_DEF_DEF_  "U_CD4_MY14_Gas_Rx" "No";
BA_DEF_DEF_  "U_CD4_MY14_Diesel_Rx" "No";
BA_DEF_DEF_  "U_CD43_MY16_Gas_Rx" "No";
BA_DEF_DEF_  "U_UP375_MY15_Diesel_Rx" "No";
BA_DEF_DEF_  "U_UP375_MY15_Gas_Rx" "No";
BA_DEF_DEF_  "U_B479_MY15_Gas_Rx" "No";
BA_DEF_DEF_  "U_U502_MY15_Gas_Rx" "No";
BA_DEF_DEF_  "U_C489_MY14_Gas_Rx" "No";
BA_DEF_DEF_  "U_S550_MY15_Gas_Rx" "No";
BA_DEF_DEF_  "U_P552_MY15_Gas_Rx" "No";
BA_DEF_DEF_  "U_CD42_MY14_Gas_Rx" "No";
BA_DEF_DEF_  "U_CD42_MY14_Diesel_Rx" "No";
BA_DEF_DEF_  "U_CD4_MY13_Phev_Rx" "No";
BA_DEF_DEF_  "U_CD4_MY13_Hev_Rx" "No";
BA_DEF_DEF_  "U_CD4_MY13_Gas_Rx" "No";
BA_DEF_DEF_  "U_CD4_MY13_Diesel_Rx" "No";
BA_DEF_DEF_  "ContentDependant" "No";
BA_DEF_DEF_  "GenSigStartValue" 0;
BA_DEF_DEF_  "CrossOver_LIN" "No";
BA_DEF_DEF_  "CrossOver_InfoCAN" "No";
BA_DEF_DEF_  "WakeupSignal" "No";
BA_DEF_DEF_  "GenSigSendType" "NoSigSendType";
BA_DEF_DEF_  "TpApplType" "";
BA_DEF_DEF_  "DiagState" "No";
BA_DEF_DEF_  "DiagRequest" "No";
BA_DEF_DEF_  "DiagResponse" "No";
BA_DEF_DEF_  "GenMsgILSupport" "Yes";
BA_ "GenMsgSendType" BO_ 1442 0;
BA_ "GenMsgCycleTime" BO_ 1442 1000;
BA_ "NetworkInitialization" BO_ 1200 1;
BA_ "FrameGatewayNetwork" BO_ 1200 "HS2_CAN";
BA_ "GenMsgDelayTime" BO_ 1200 10;
BA_ "FrameGatewayId" BO_ 1200 1200;
BA_ "FrameGatewayHS2" BO_ 1200 1200;
BA_ "GenMsgILSupport" BO_ 2015 0;
BA_ "DiagState" BO_ 2015 1;
BA_ "GenMsgSendType" BO_ 2015 1;
BA_ "GenMsgDelayTime" BO_ 2015 0;
BA_ "GenMsgSendType" BO_ 376 0;
BA_ "GenMsgCycleTime" BO_ 376 100;
BA_ "NetworkInitialization" BO_ 376 1;
BA_ "GenMsgSendType" BO_ 516 0;
BA_ "GenMsgCycleTime" BO_ 516 10;
BA_ "GenMsgDelayTime" BO_ 516 0;
BA_ "GenMsgSendType" BO_ 377 0;
BA_ "GenMsgCycleTime" BO_ 377 100;
BA_ "NetworkInitialization" BO_ 377 1;
BA_ "GenMsgSendType" BO_ 369 0;
BA_ "GenMsgCycleTime" BO_ 369 30;
BA_ "GenMsgDelayTime" BO_ 369 10;
BA_ "NetworkInitialization" BO_ 369 1;
BA_ "GenMsgSendType" BO_ 1466 0;
BA_ "GenMsgCycleTime" BO_ 1466 1000;
BA_ "FrameGatewayNetwork" BO_ 76 "HS2_CAN";
BA_ "GenMsgDelayTime" BO_ 76 10;
BA_ "FrameGatewayId" BO_ 76 76;
BA_ "FrameGatewayHS2" BO_ 76 76;
BA_ "GenMsgILSupport" BO_ 2008 0;
BA_ "DiagResponse" BO_ 2008 1;
BA_ "GenMsgSendType" BO_ 2008 1;
BA_ "GenMsgDelayTime" BO_ 2008 0;
BA_ "GenMsgSendType" BO_ 146 1;
BA_ "GenMsgDelayTime" BO_ 146 100;
BA_ "GenMsgILSupport" BO_ 1870 0;
BA_ "DiagResponse" BO_ 1870 1;
BA_ "GenMsgSendType" BO_ 1870 1;
BA_ "GenMsgDelayTime" BO_ 1870 0;
BA_ "GenMsgILSupport" BO_ 1862 0;
BA_ "DiagRequest" BO_ 1862 1;
BA_ "GenMsgSendType" BO_ 1862 1;
BA_ "GenMsgDelayTime" BO_ 1862 0;
BA_ "GenMsgILSupport" BO_ 1697 0;
BA_ "TpApplType" BO_ 1697 "DiagUUDTResponse";
BA_ "GenMsgSendType" BO_ 1697 1;
BA_ "GenMsgILSupport" BO_ 1696 0;
BA_ "TpApplType" BO_ 1696 "DiagUUDTResponse";
BA_ "GenMsgSendType" BO_ 1696 1;
BA_ "GenMsgSendType" BO_ 967 5;
BA_ "GenMsgCycleTime" BO_ 967 1000;
BA_ "GenMsgStartDelayTime" BO_ 967 80;
BA_ "GenMsgSendType" BO_ 949 0;
BA_ "GenMsgCycleTime" BO_ 949 500;
BA_ "GenMsgStartDelayTime" BO_ 949 60;
BA_ "GenMsgSendType" BO_ 948 5;
BA_ "GenMsgCycleTime" BO_ 948 1000;
BA_ "GenMsgStartDelayTime" BO_ 948 50;
BA_ "NetworkInitialization" BO_ 1077 1;
BA_ "GenMsgSendType" BO_ 1077 5;
BA_ "GenMsgCycleTime" BO_ 1077 100;
BA_ "GenMsgStartDelayTime" BO_ 1077 100;
BA_ "FrameGatewayNetwork" BO_ 862 "MS1_CAN";
BA_ "FrameGatewayId" BO_ 862 862;
BA_ "FrameGatewayMS1" BO_ 862 862;
BA_ "GenMsgSendType" BO_ 342 0;
BA_ "GenMsgCycleTime" BO_ 342 100;
BA_ "NetworkInitialization" BO_ 342 1;
BA_ "FrameGatewayNetwork" BO_ 992 "HS3_CAN";
BA_ "FrameGatewayId" BO_ 992 992;
BA_ "FrameGatewayHS3" BO_ 992 992;
BA_ "U_CD42_MY15_Diesel_Rx" SG_ 1442 BECM_GWOnBoardTester 1;
BA_ "U_CD42_MY15_Gas_Rx" SG_ 1442 BECM_GWOnBoardTester 1;
BA_ "U_U502_MY16_Gas_Rx" SG_ 1442 BECM_GWOnBoardTester 1;
BA_ "U_CD4_MY17_Diesel_Rx" SG_ 1442 BECM_GWOnBoardTester 1;
BA_ "U_CD4_MY17_Gas_Rx" SG_ 1442 BECM_GWOnBoardTester 1;
BA_ "U_CD4_MY17_Hev_Rx" SG_ 1442 BECM_GWOnBoardTester 1;
BA_ "U_CD4_MY17_Phev_Rx" SG_ 1442 BECM_GWOnBoardTester 1;
BA_ "U_V36X_MY16_5_Diesel_Rx" SG_ 1442 BECM_GWOnBoardTester 1;
BA_ "U_C489_MY17_Gas_Rx" SG_ 1442 BECM_GWOnBoardTester 1;
BA_ "U_CD42_MY16_Diesel_Rx" SG_ 1442 BECM_GWOnBoardTester 1;
BA_ "U_CD42_MY16_Gas_Rx" SG_ 1442 BECM_GWOnBoardTester 1;
BA_ "U_CD43_MY17_Gas_Rx" SG_ 1442 BECM_GWOnBoardTester 1;
BA_ "U_P552_MY17_Gas_Rx" SG_ 1442 BECM_GWOnBoardTester 1;
BA_ "U_B515_MCA_MY17_Diesel_Rx" SG_ 1442 BECM_GWOnBoardTester 1;
BA_ "U_B515_MCA_MY17_Gas_Rx" SG_ 1442 BECM_GWOnBoardTester 1;
BA_ "U_U55x_MY18_Gas_Rx" SG_ 1442 BECM_GWOnBoardTester 1;
BA_ "U_CD4_MY13_Phev_Tx" SG_ 1442 BECM_GWOnBoardTester 1;
BA_ "U_CD4_MY14_Phev_Tx" SG_ 1442 BECM_GWOnBoardTester 1;
BA_ "U_CD4_MY17_Phev_Tx" SG_ 1442 BECM_GWOnBoardTester 1;
BA_ "GenSigStartValue" SG_ 1442 BECM_GWOnBoardTester 255;
BA_ "ContentDependant" SG_ 1442 BECM_GWOnBoardTester 1;
BA_ "U_CD4_MY13_Diesel_Rx" SG_ 1442 BECM_GWOnBoardTester 1;
BA_ "U_CD4_MY13_Gas_Rx" SG_ 1442 BECM_GWOnBoardTester 1;
BA_ "U_CD4_MY13_Hev_Rx" SG_ 1442 BECM_GWOnBoardTester 1;
BA_ "U_CD4_MY13_Phev_Rx" SG_ 1442 BECM_GWOnBoardTester 1;
BA_ "U_CD42_MY14_Diesel_Rx" SG_ 1442 BECM_GWOnBoardTester 1;
BA_ "U_CD42_MY14_Gas_Rx" SG_ 1442 BECM_GWOnBoardTester 1;
BA_ "U_P552_MY15_Gas_Rx" SG_ 1442 BECM_GWOnBoardTester 1;
BA_ "U_S550_MY15_Gas_Rx" SG_ 1442 BECM_GWOnBoardTester 1;
BA_ "U_C489_MY14_Gas_Rx" SG_ 1442 BECM_GWOnBoardTester 1;
BA_ "U_U502_MY15_Gas_Rx" SG_ 1442 BECM_GWOnBoardTester 1;
BA_ "U_UP375_MY15_Gas_Rx" SG_ 1442 BECM_GWOnBoardTester 1;
BA_ "U_UP375_MY15_Diesel_Rx" SG_ 1442 BECM_GWOnBoardTester 1;
BA_ "U_CD43_MY16_Gas_Rx" SG_ 1442 BECM_GWOnBoardTester 1;
BA_ "U_CD4_MY14_Diesel_Rx" SG_ 1442 BECM_GWOnBoardTester 1;
BA_ "U_CD4_MY14_Gas_Rx" SG_ 1442 BECM_GWOnBoardTester 1;
BA_ "U_CD4_MY14_Hev_Rx" SG_ 1442 BECM_GWOnBoardTester 1;
BA_ "U_CD4_MY14_Phev_Rx" SG_ 1442 BECM_GWOnBoardTester 1;
BA_ "U_CD42_MY15_Diesel_Rx" SG_ 1442 BECM_GWNMProxy 1;
BA_ "U_CD42_MY15_Gas_Rx" SG_ 1442 BECM_GWNMProxy 1;
BA_ "U_U502_MY16_Gas_Rx" SG_ 1442 BECM_GWNMProxy 1;
BA_ "U_CD4_MY17_Diesel_Rx" SG_ 1442 BECM_GWNMProxy 1;
BA_ "U_CD4_MY17_Gas_Rx" SG_ 1442 BECM_GWNMProxy 1;
BA_ "U_CD4_MY17_Hev_Rx" SG_ 1442 BECM_GWNMProxy 1;
BA_ "U_CD4_MY17_Phev_Rx" SG_ 1442 BECM_GWNMProxy 1;
BA_ "U_V36X_MY16_5_Diesel_Rx" SG_ 1442 BECM_GWNMProxy 1;
BA_ "U_C489_MY17_Gas_Rx" SG_ 1442 BECM_GWNMProxy 1;
BA_ "U_CD42_MY16_Diesel_Rx" SG_ 1442 BECM_GWNMProxy 1;
BA_ "U_CD42_MY16_Gas_Rx" SG_ 1442 BECM_GWNMProxy 1;
BA_ "U_CD43_MY17_Gas_Rx" SG_ 1442 BECM_GWNMProxy 1;
BA_ "U_P552_MY17_Gas_Rx" SG_ 1442 BECM_GWNMProxy 1;
BA_ "U_B515_MCA_MY17_Diesel_Rx" SG_ 1442 BECM_GWNMProxy 1;
BA_ "U_B515_MCA_MY17_Gas_Rx" SG_ 1442 BECM_GWNMProxy 1;
BA_ "U_U55x_MY18_Gas_Rx" SG_ 1442 BECM_GWNMProxy 1;
BA_ "U_CD4_MY13_Phev_Tx" SG_ 1442 BECM_GWNMProxy 1;
BA_ "U_CD4_MY14_Phev_Tx" SG_ 1442 BECM_GWNMProxy 1;
BA_ "U_CD4_MY17_Phev_Tx" SG_ 1442 BECM_GWNMProxy 1;
BA_ "GenSigStartValue" SG_ 1442 BECM_GWNMProxy 255;
BA_ "ContentDependant" SG_ 1442 BECM_GWNMProxy 1;
BA_ "U_CD4_MY13_Diesel_Rx" SG_ 1442 BECM_GWNMProxy 1;
BA_ "U_CD4_MY13_Gas_Rx" SG_ 1442 BECM_GWNMProxy 1;
BA_ "U_CD4_MY13_Hev_Rx" SG_ 1442 BECM_GWNMProxy 1;
BA_ "U_CD4_MY13_Phev_Rx" SG_ 1442 BECM_GWNMProxy 1;
BA_ "U_CD42_MY14_Diesel_Rx" SG_ 1442 BECM_GWNMProxy 1;
BA_ "U_CD42_MY14_Gas_Rx" SG_ 1442 BECM_GWNMProxy 1;
BA_ "U_P552_MY15_Gas_Rx" SG_ 1442 BECM_GWNMProxy 1;
BA_ "U_S550_MY15_Gas_Rx" SG_ 1442 BECM_GWNMProxy 1;
BA_ "U_C489_MY14_Gas_Rx" SG_ 1442 BECM_GWNMProxy 1;
BA_ "U_U502_MY15_Gas_Rx" SG_ 1442 BECM_GWNMProxy 1;
BA_ "U_UP375_MY15_Gas_Rx" SG_ 1442 BECM_GWNMProxy 1;
BA_ "U_UP375_MY15_Diesel_Rx" SG_ 1442 BECM_GWNMProxy 1;
BA_ "U_CD43_MY16_Gas_Rx" SG_ 1442 BECM_GWNMProxy 1;
BA_ "U_CD4_MY14_Diesel_Rx" SG_ 1442 BECM_GWNMProxy 1;
BA_ "U_CD4_MY14_Gas_Rx" SG_ 1442 BECM_GWNMProxy 1;
BA_ "U_CD4_MY14_Hev_Rx" SG_ 1442 BECM_GWNMProxy 1;
BA_ "U_CD4_MY14_Phev_Rx" SG_ 1442 BECM_GWNMProxy 1;
BA_ "U_CD42_MY15_Diesel_Rx" SG_ 1442 BECM_AutoSarNMReserved4 1;
BA_ "U_CD42_MY15_Gas_Rx" SG_ 1442 BECM_AutoSarNMReserved4 1;
BA_ "U_U502_MY16_Gas_Rx" SG_ 1442 BECM_AutoSarNMReserved4 1;
BA_ "U_CD4_MY17_Diesel_Rx" SG_ 1442 BECM_AutoSarNMReserved4 1;
BA_ "U_CD4_MY17_Gas_Rx" SG_ 1442 BECM_AutoSarNMReserved4 1;
BA_ "U_CD4_MY17_Hev_Rx" SG_ 1442 BECM_AutoSarNMReserved4 1;
BA_ "U_CD4_MY17_Phev_Rx" SG_ 1442 BECM_AutoSarNMReserved4 1;
BA_ "U_V36X_MY16_5_Diesel_Rx" SG_ 1442 BECM_AutoSarNMReserved4 1;
BA_ "U_C489_MY17_Gas_Rx" SG_ 1442 BECM_AutoSarNMReserved4 1;
BA_ "U_CD42_MY16_Diesel_Rx" SG_ 1442 BECM_AutoSarNMReserved4 1;
BA_ "U_CD42_MY16_Gas_Rx" SG_ 1442 BECM_AutoSarNMReserved4 1;
BA_ "U_CD43_MY17_Gas_Rx" SG_ 1442 BECM_AutoSarNMReserved4 1;
BA_ "U_P552_MY17_Gas_Rx" SG_ 1442 BECM_AutoSarNMReserved4 1;
BA_ "U_B515_MCA_MY17_Diesel_Rx" SG_ 1442 BECM_AutoSarNMReserved4 1;
BA_ "U_B515_MCA_MY17_Gas_Rx" SG_ 1442 BECM_AutoSarNMReserved4 1;
BA_ "U_U55x_MY18_Gas_Rx" SG_ 1442 BECM_AutoSarNMReserved4 1;
BA_ "U_CD4_MY13_Phev_Tx" SG_ 1442 BECM_AutoSarNMReserved4 1;
BA_ "U_CD4_MY14_Phev_Tx" SG_ 1442 BECM_AutoSarNMReserved4 1;
BA_ "U_CD4_MY17_Phev_Tx" SG_ 1442 BECM_AutoSarNMReserved4 1;
BA_ "GenSigStartValue" SG_ 1442 BECM_AutoSarNMReserved4 255;
BA_ "ContentDependant" SG_ 1442 BECM_AutoSarNMReserved4 1;
BA_ "U_CD4_MY13_Diesel_Rx" SG_ 1442 BECM_AutoSarNMReserved4 1;
BA_ "U_CD4_MY13_Gas_Rx" SG_ 1442 BECM_AutoSarNMReserved4 1;
BA_ "U_CD4_MY13_Hev_Rx" SG_ 1442 BECM_AutoSarNMReserved4 1;
BA_ "U_CD4_MY13_Phev_Rx" SG_ 1442 BECM_AutoSarNMReserved4 1;
BA_ "U_CD42_MY14_Diesel_Rx" SG_ 1442 BECM_AutoSarNMReserved4 1;
BA_ "U_CD42_MY14_Gas_Rx" SG_ 1442 BECM_AutoSarNMReserved4 1;
BA_ "U_P552_MY15_Gas_Rx" SG_ 1442 BECM_AutoSarNMReserved4 1;
BA_ "U_S550_MY15_Gas_Rx" SG_ 1442 BECM_AutoSarNMReserved4 1;
BA_ "U_C489_MY14_Gas_Rx" SG_ 1442 BECM_AutoSarNMReserved4 1;
BA_ "U_U502_MY15_Gas_Rx" SG_ 1442 BECM_AutoSarNMReserved4 1;
BA_ "U_UP375_MY15_Gas_Rx" SG_ 1442 BECM_AutoSarNMReserved4 1;
BA_ "U_UP375_MY15_Diesel_Rx" SG_ 1442 BECM_AutoSarNMReserved4 1;
BA_ "U_CD43_MY16_Gas_Rx" SG_ 1442 BECM_AutoSarNMReserved4 1;
BA_ "U_CD4_MY14_Diesel_Rx" SG_ 1442 BECM_AutoSarNMReserved4 1;
BA_ "U_CD4_MY14_Gas_Rx" SG_ 1442 BECM_AutoSarNMReserved4 1;
BA_ "U_CD4_MY14_Hev_Rx" SG_ 1442 BECM_AutoSarNMReserved4 1;
BA_ "U_CD4_MY14_Phev_Rx" SG_ 1442 BECM_AutoSarNMReserved4 1;
BA_ "U_CD42_MY15_Diesel_Rx" SG_ 1442 BECM_AutoSarNMReserved3 1;
BA_ "U_CD42_MY15_Gas_Rx" SG_ 1442 BECM_AutoSarNMReserved3 1;
BA_ "U_U502_MY16_Gas_Rx" SG_ 1442 BECM_AutoSarNMReserved3 1;
BA_ "U_CD4_MY17_Diesel_Rx" SG_ 1442 BECM_AutoSarNMReserved3 1;
BA_ "U_CD4_MY17_Gas_Rx" SG_ 1442 BECM_AutoSarNMReserved3 1;
BA_ "U_CD4_MY17_Hev_Rx" SG_ 1442 BECM_AutoSarNMReserved3 1;
BA_ "U_CD4_MY17_Phev_Rx" SG_ 1442 BECM_AutoSarNMReserved3 1;
BA_ "U_V36X_MY16_5_Diesel_Rx" SG_ 1442 BECM_AutoSarNMReserved3 1;
BA_ "U_C489_MY17_Gas_Rx" SG_ 1442 BECM_AutoSarNMReserved3 1;
BA_ "U_CD42_MY16_Diesel_Rx" SG_ 1442 BECM_AutoSarNMReserved3 1;
BA_ "U_CD42_MY16_Gas_Rx" SG_ 1442 BECM_AutoSarNMReserved3 1;
BA_ "U_CD43_MY17_Gas_Rx" SG_ 1442 BECM_AutoSarNMReserved3 1;
BA_ "U_P552_MY17_Gas_Rx" SG_ 1442 BECM_AutoSarNMReserved3 1;
BA_ "U_B515_MCA_MY17_Diesel_Rx" SG_ 1442 BECM_AutoSarNMReserved3 1;
BA_ "U_B515_MCA_MY17_Gas_Rx" SG_ 1442 BECM_AutoSarNMReserved3 1;
BA_ "U_U55x_MY18_Gas_Rx" SG_ 1442 BECM_AutoSarNMReserved3 1;
BA_ "U_CD4_MY13_Phev_Tx" SG_ 1442 BECM_AutoSarNMReserved3 1;
BA_ "U_CD4_MY14_Phev_Tx" SG_ 1442 BECM_AutoSarNMReserved3 1;
BA_ "U_CD4_MY17_Phev_Tx" SG_ 1442 BECM_AutoSarNMReserved3 1;
BA_ "GenSigStartValue" SG_ 1442 BECM_AutoSarNMReserved3 255;
BA_ "ContentDependant" SG_ 1442 BECM_AutoSarNMReserved3 1;
BA_ "U_CD4_MY13_Diesel_Rx" SG_ 1442 BECM_AutoSarNMReserved3 1;
BA_ "U_CD4_MY13_Gas_Rx" SG_ 1442 BECM_AutoSarNMReserved3 1;
BA_ "U_CD4_MY13_Hev_Rx" SG_ 1442 BECM_AutoSarNMReserved3 1;
BA_ "U_CD4_MY13_Phev_Rx" SG_ 1442 BECM_AutoSarNMReserved3 1;
BA_ "U_CD42_MY14_Diesel_Rx" SG_ 1442 BECM_AutoSarNMReserved3 1;
BA_ "U_CD42_MY14_Gas_Rx" SG_ 1442 BECM_AutoSarNMReserved3 1;
BA_ "U_P552_MY15_Gas_Rx" SG_ 1442 BECM_AutoSarNMReserved3 1;
BA_ "U_S550_MY15_Gas_Rx" SG_ 1442 BECM_AutoSarNMReserved3 1;
BA_ "U_C489_MY14_Gas_Rx" SG_ 1442 BECM_AutoSarNMReserved3 1;
BA_ "U_U502_MY15_Gas_Rx" SG_ 1442 BECM_AutoSarNMReserved3 1;
BA_ "U_UP375_MY15_Gas_Rx" SG_ 1442 BECM_AutoSarNMReserved3 1;
BA_ "U_UP375_MY15_Diesel_Rx" SG_ 1442 BECM_AutoSarNMReserved3 1;
BA_ "U_CD43_MY16_Gas_Rx" SG_ 1442 BECM_AutoSarNMReserved3 1;
BA_ "U_CD4_MY14_Diesel_Rx" SG_ 1442 BECM_AutoSarNMReserved3 1;
BA_ "U_CD4_MY14_Gas_Rx" SG_ 1442 BECM_AutoSarNMReserved3 1;
BA_ "U_CD4_MY14_Hev_Rx" SG_ 1442 BECM_AutoSarNMReserved3 1;
BA_ "U_CD4_MY14_Phev_Rx" SG_ 1442 BECM_AutoSarNMReserved3 1;
BA_ "U_CD42_MY15_Diesel_Rx" SG_ 1442 BECM_AutoSarNMReserved2 1;
BA_ "U_CD42_MY15_Gas_Rx" SG_ 1442 BECM_AutoSarNMReserved2 1;
BA_ "U_U502_MY16_Gas_Rx" SG_ 1442 BECM_AutoSarNMReserved2 1;
BA_ "U_CD4_MY17_Diesel_Rx" SG_ 1442 BECM_AutoSarNMReserved2 1;
BA_ "U_CD4_MY17_Gas_Rx" SG_ 1442 BECM_AutoSarNMReserved2 1;
BA_ "U_CD4_MY17_Hev_Rx" SG_ 1442 BECM_AutoSarNMReserved2 1;
BA_ "U_CD4_MY17_Phev_Rx" SG_ 1442 BECM_AutoSarNMReserved2 1;
BA_ "U_V36X_MY16_5_Diesel_Rx" SG_ 1442 BECM_AutoSarNMReserved2 1;
BA_ "U_C489_MY17_Gas_Rx" SG_ 1442 BECM_AutoSarNMReserved2 1;
BA_ "U_CD42_MY16_Diesel_Rx" SG_ 1442 BECM_AutoSarNMReserved2 1;
BA_ "U_CD42_MY16_Gas_Rx" SG_ 1442 BECM_AutoSarNMReserved2 1;
BA_ "U_CD43_MY17_Gas_Rx" SG_ 1442 BECM_AutoSarNMReserved2 1;
BA_ "U_P552_MY17_Gas_Rx" SG_ 1442 BECM_AutoSarNMReserved2 1;
BA_ "U_B515_MCA_MY17_Diesel_Rx" SG_ 1442 BECM_AutoSarNMReserved2 1;
BA_ "U_B515_MCA_MY17_Gas_Rx" SG_ 1442 BECM_AutoSarNMReserved2 1;
BA_ "U_U55x_MY18_Gas_Rx" SG_ 1442 BECM_AutoSarNMReserved2 1;
BA_ "U_CD4_MY13_Phev_Tx" SG_ 1442 BECM_AutoSarNMReserved2 1;
BA_ "U_CD4_MY14_Phev_Tx" SG_ 1442 BECM_AutoSarNMReserved2 1;
BA_ "U_CD4_MY17_Phev_Tx" SG_ 1442 BECM_AutoSarNMReserved2 1;
BA_ "GenSigStartValue" SG_ 1442 BECM_AutoSarNMReserved2 255;
BA_ "ContentDependant" SG_ 1442 BECM_AutoSarNMReserved2 1;
BA_ "U_CD4_MY13_Diesel_Rx" SG_ 1442 BECM_AutoSarNMReserved2 1;
BA_ "U_CD4_MY13_Gas_Rx" SG_ 1442 BECM_AutoSarNMReserved2 1;
BA_ "U_CD4_MY13_Hev_Rx" SG_ 1442 BECM_AutoSarNMReserved2 1;
BA_ "U_CD4_MY13_Phev_Rx" SG_ 1442 BECM_AutoSarNMReserved2 1;
BA_ "U_CD42_MY14_Diesel_Rx" SG_ 1442 BECM_AutoSarNMReserved2 1;
BA_ "U_CD42_MY14_Gas_Rx" SG_ 1442 BECM_AutoSarNMReserved2 1;
BA_ "U_P552_MY15_Gas_Rx" SG_ 1442 BECM_AutoSarNMReserved2 1;
BA_ "U_S550_MY15_Gas_Rx" SG_ 1442 BECM_AutoSarNMReserved2 1;
BA_ "U_C489_MY14_Gas_Rx" SG_ 1442 BECM_AutoSarNMReserved2 1;
BA_ "U_U502_MY15_Gas_Rx" SG_ 1442 BECM_AutoSarNMReserved2 1;
BA_ "U_UP375_MY15_Gas_Rx" SG_ 1442 BECM_AutoSarNMReserved2 1;
BA_ "U_UP375_MY15_Diesel_Rx" SG_ 1442 BECM_AutoSarNMReserved2 1;
BA_ "U_CD43_MY16_Gas_Rx" SG_ 1442 BECM_AutoSarNMReserved2 1;
BA_ "U_CD4_MY14_Diesel_Rx" SG_ 1442 BECM_AutoSarNMReserved2 1;
BA_ "U_CD4_MY14_Gas_Rx" SG_ 1442 BECM_AutoSarNMReserved2 1;
BA_ "U_CD4_MY14_Hev_Rx" SG_ 1442 BECM_AutoSarNMReserved2 1;
BA_ "U_CD4_MY14_Phev_Rx" SG_ 1442 BECM_AutoSarNMReserved2 1;
BA_ "U_CD42_MY15_Diesel_Rx" SG_ 1442 BECM_AutoSarNMReserved1 1;
BA_ "U_CD42_MY15_Gas_Rx" SG_ 1442 BECM_AutoSarNMReserved1 1;
BA_ "U_U502_MY16_Gas_Rx" SG_ 1442 BECM_AutoSarNMReserved1 1;
BA_ "U_CD4_MY17_Diesel_Rx" SG_ 1442 BECM_AutoSarNMReserved1 1;
BA_ "U_CD4_MY17_Gas_Rx" SG_ 1442 BECM_AutoSarNMReserved1 1;
BA_ "U_CD4_MY17_Hev_Rx" SG_ 1442 BECM_AutoSarNMReserved1 1;
BA_ "U_CD4_MY17_Phev_Rx" SG_ 1442 BECM_AutoSarNMReserved1 1;
BA_ "U_V36X_MY16_5_Diesel_Rx" SG_ 1442 BECM_AutoSarNMReserved1 1;
BA_ "U_C489_MY17_Gas_Rx" SG_ 1442 BECM_AutoSarNMReserved1 1;
BA_ "U_CD42_MY16_Diesel_Rx" SG_ 1442 BECM_AutoSarNMReserved1 1;
BA_ "U_CD42_MY16_Gas_Rx" SG_ 1442 BECM_AutoSarNMReserved1 1;
BA_ "U_CD43_MY17_Gas_Rx" SG_ 1442 BECM_AutoSarNMReserved1 1;
BA_ "U_P552_MY17_Gas_Rx" SG_ 1442 BECM_AutoSarNMReserved1 1;
BA_ "U_B515_MCA_MY17_Diesel_Rx" SG_ 1442 BECM_AutoSarNMReserved1 1;
BA_ "U_B515_MCA_MY17_Gas_Rx" SG_ 1442 BECM_AutoSarNMReserved1 1;
BA_ "U_U55x_MY18_Gas_Rx" SG_ 1442 BECM_AutoSarNMReserved1 1;
BA_ "U_CD4_MY13_Phev_Tx" SG_ 1442 BECM_AutoSarNMReserved1 1;
BA_ "U_CD4_MY14_Phev_Tx" SG_ 1442 BECM_AutoSarNMReserved1 1;
BA_ "U_CD4_MY17_Phev_Tx" SG_ 1442 BECM_AutoSarNMReserved1 1;
BA_ "GenSigStartValue" SG_ 1442 BECM_AutoSarNMReserved1 255;
BA_ "ContentDependant" SG_ 1442 BECM_AutoSarNMReserved1 1;
BA_ "U_CD4_MY13_Diesel_Rx" SG_ 1442 BECM_AutoSarNMReserved1 1;
BA_ "U_CD4_MY13_Gas_Rx" SG_ 1442 BECM_AutoSarNMReserved1 1;
BA_ "U_CD4_MY13_Hev_Rx" SG_ 1442 BECM_AutoSarNMReserved1 1;
BA_ "U_CD4_MY13_Phev_Rx" SG_ 1442 BECM_AutoSarNMReserved1 1;
BA_ "U_CD42_MY14_Diesel_Rx" SG_ 1442 BECM_AutoSarNMReserved1 1;
BA_ "U_CD42_MY14_Gas_Rx" SG_ 1442 BECM_AutoSarNMReserved1 1;
BA_ "U_P552_MY15_Gas_Rx" SG_ 1442 BECM_AutoSarNMReserved1 1;
BA_ "U_S550_MY15_Gas_Rx" SG_ 1442 BECM_AutoSarNMReserved1 1;
BA_ "U_C489_MY14_Gas_Rx" SG_ 1442 BECM_AutoSarNMReserved1 1;
BA_ "U_U502_MY15_Gas_Rx" SG_ 1442 BECM_AutoSarNMReserved1 1;
BA_ "U_UP375_MY15_Gas_Rx" SG_ 1442 BECM_AutoSarNMReserved1 1;
BA_ "U_UP375_MY15_Diesel_Rx" SG_ 1442 BECM_AutoSarNMReserved1 1;
BA_ "U_CD43_MY16_Gas_Rx" SG_ 1442 BECM_AutoSarNMReserved1 1;
BA_ "U_CD4_MY14_Diesel_Rx" SG_ 1442 BECM_AutoSarNMReserved1 1;
BA_ "U_CD4_MY14_Gas_Rx" SG_ 1442 BECM_AutoSarNMReserved1 1;
BA_ "U_CD4_MY14_Hev_Rx" SG_ 1442 BECM_AutoSarNMReserved1 1;
BA_ "U_CD4_MY14_Phev_Rx" SG_ 1442 BECM_AutoSarNMReserved1 1;
BA_ "GenSigStartValue" SG_ 1442 BECM_AutoSarNMNodeId 162;
BA_ "U_CD42_MY15_Diesel_Rx" SG_ 1442 BECM_AutoSarNMNodeId 1;
BA_ "U_CD42_MY15_Gas_Rx" SG_ 1442 BECM_AutoSarNMNodeId 1;
BA_ "U_U502_MY16_Gas_Rx" SG_ 1442 BECM_AutoSarNMNodeId 1;
BA_ "U_CD4_MY17_Diesel_Rx" SG_ 1442 BECM_AutoSarNMNodeId 1;
BA_ "U_CD4_MY17_Gas_Rx" SG_ 1442 BECM_AutoSarNMNodeId 1;
BA_ "U_CD4_MY17_Hev_Rx" SG_ 1442 BECM_AutoSarNMNodeId 1;
BA_ "U_CD4_MY17_Phev_Rx" SG_ 1442 BECM_AutoSarNMNodeId 1;
BA_ "U_V36X_MY16_5_Diesel_Rx" SG_ 1442 BECM_AutoSarNMNodeId 1;
BA_ "U_C489_MY17_Gas_Rx" SG_ 1442 BECM_AutoSarNMNodeId 1;
BA_ "U_CD42_MY16_Diesel_Rx" SG_ 1442 BECM_AutoSarNMNodeId 1;
BA_ "U_CD42_MY16_Gas_Rx" SG_ 1442 BECM_AutoSarNMNodeId 1;
BA_ "U_CD43_MY17_Gas_Rx" SG_ 1442 BECM_AutoSarNMNodeId 1;
BA_ "U_P552_MY17_Gas_Rx" SG_ 1442 BECM_AutoSarNMNodeId 1;
BA_ "U_B515_MCA_MY17_Diesel_Rx" SG_ 1442 BECM_AutoSarNMNodeId 1;
BA_ "U_B515_MCA_MY17_Gas_Rx" SG_ 1442 BECM_AutoSarNMNodeId 1;
BA_ "U_U55x_MY18_Gas_Rx" SG_ 1442 BECM_AutoSarNMNodeId 1;
BA_ "U_CD4_MY13_Phev_Tx" SG_ 1442 BECM_AutoSarNMNodeId 1;
BA_ "U_CD4_MY14_Phev_Tx" SG_ 1442 BECM_AutoSarNMNodeId 1;
BA_ "U_CD4_MY17_Phev_Tx" SG_ 1442 BECM_AutoSarNMNodeId 1;
BA_ "ContentDependant" SG_ 1442 BECM_AutoSarNMNodeId 1;
BA_ "U_CD4_MY13_Diesel_Rx" SG_ 1442 BECM_AutoSarNMNodeId 1;
BA_ "U_CD4_MY13_Gas_Rx" SG_ 1442 BECM_AutoSarNMNodeId 1;
BA_ "U_CD4_MY13_Hev_Rx" SG_ 1442 BECM_AutoSarNMNodeId 1;
BA_ "U_CD4_MY13_Phev_Rx" SG_ 1442 BECM_AutoSarNMNodeId 1;
BA_ "U_CD42_MY14_Diesel_Rx" SG_ 1442 BECM_AutoSarNMNodeId 1;
BA_ "U_CD42_MY14_Gas_Rx" SG_ 1442 BECM_AutoSarNMNodeId 1;
BA_ "U_P552_MY15_Gas_Rx" SG_ 1442 BECM_AutoSarNMNodeId 1;
BA_ "U_S550_MY15_Gas_Rx" SG_ 1442 BECM_AutoSarNMNodeId 1;
BA_ "U_C489_MY14_Gas_Rx" SG_ 1442 BECM_AutoSarNMNodeId 1;
BA_ "U_U502_MY15_Gas_Rx" SG_ 1442 BECM_AutoSarNMNodeId 1;
BA_ "U_UP375_MY15_Gas_Rx" SG_ 1442 BECM_AutoSarNMNodeId 1;
BA_ "U_UP375_MY15_Diesel_Rx" SG_ 1442 BECM_AutoSarNMNodeId 1;
BA_ "U_CD43_MY16_Gas_Rx" SG_ 1442 BECM_AutoSarNMNodeId 1;
BA_ "U_CD4_MY14_Diesel_Rx" SG_ 1442 BECM_AutoSarNMNodeId 1;
BA_ "U_CD4_MY14_Gas_Rx" SG_ 1442 BECM_AutoSarNMNodeId 1;
BA_ "U_CD4_MY14_Hev_Rx" SG_ 1442 BECM_AutoSarNMNodeId 1;
BA_ "U_CD4_MY14_Phev_Rx" SG_ 1442 BECM_AutoSarNMNodeId 1;
BA_ "U_CD42_MY15_Diesel_Rx" SG_ 1442 BECM_AutoSarNMControl 1;
BA_ "U_CD42_MY15_Gas_Rx" SG_ 1442 BECM_AutoSarNMControl 1;
BA_ "U_U502_MY16_Gas_Rx" SG_ 1442 BECM_AutoSarNMControl 1;
BA_ "U_CD4_MY17_Diesel_Rx" SG_ 1442 BECM_AutoSarNMControl 1;
BA_ "U_CD4_MY17_Gas_Rx" SG_ 1442 BECM_AutoSarNMControl 1;
BA_ "U_CD4_MY17_Hev_Rx" SG_ 1442 BECM_AutoSarNMControl 1;
BA_ "U_CD4_MY17_Phev_Rx" SG_ 1442 BECM_AutoSarNMControl 1;
BA_ "U_V36X_MY16_5_Diesel_Rx" SG_ 1442 BECM_AutoSarNMControl 1;
BA_ "U_C489_MY17_Gas_Rx" SG_ 1442 BECM_AutoSarNMControl 1;
BA_ "U_CD42_MY16_Diesel_Rx" SG_ 1442 BECM_AutoSarNMControl 1;
BA_ "U_CD42_MY16_Gas_Rx" SG_ 1442 BECM_AutoSarNMControl 1;
BA_ "U_CD43_MY17_Gas_Rx" SG_ 1442 BECM_AutoSarNMControl 1;
BA_ "U_P552_MY17_Gas_Rx" SG_ 1442 BECM_AutoSarNMControl 1;
BA_ "U_B515_MCA_MY17_Diesel_Rx" SG_ 1442 BECM_AutoSarNMControl 1;
BA_ "U_B515_MCA_MY17_Gas_Rx" SG_ 1442 BECM_AutoSarNMControl 1;
BA_ "U_U55x_MY18_Gas_Rx" SG_ 1442 BECM_AutoSarNMControl 1;
BA_ "U_CD4_MY13_Phev_Tx" SG_ 1442 BECM_AutoSarNMControl 1;
BA_ "U_CD4_MY14_Phev_Tx" SG_ 1442 BECM_AutoSarNMControl 1;
BA_ "U_CD4_MY17_Phev_Tx" SG_ 1442 BECM_AutoSarNMControl 1;
BA_ "ContentDependant" SG_ 1442 BECM_AutoSarNMControl 1;
BA_ "U_CD4_MY13_Diesel_Rx" SG_ 1442 BECM_AutoSarNMControl 1;
BA_ "U_CD4_MY13_Gas_Rx" SG_ 1442 BECM_AutoSarNMControl 1;
BA_ "U_CD4_MY13_Hev_Rx" SG_ 1442 BECM_AutoSarNMControl 1;
BA_ "U_CD4_MY13_Phev_Rx" SG_ 1442 BECM_AutoSarNMControl 1;
BA_ "U_CD42_MY14_Diesel_Rx" SG_ 1442 BECM_AutoSarNMControl 1;
BA_ "U_CD42_MY14_Gas_Rx" SG_ 1442 BECM_AutoSarNMControl 1;
BA_ "U_P552_MY15_Gas_Rx" SG_ 1442 BECM_AutoSarNMControl 1;
BA_ "U_S550_MY15_Gas_Rx" SG_ 1442 BECM_AutoSarNMControl 1;
BA_ "U_C489_MY14_Gas_Rx" SG_ 1442 BECM_AutoSarNMControl 1;
BA_ "U_U502_MY15_Gas_Rx" SG_ 1442 BECM_AutoSarNMControl 1;
BA_ "U_UP375_MY15_Gas_Rx" SG_ 1442 BECM_AutoSarNMControl 1;
BA_ "U_UP375_MY15_Diesel_Rx" SG_ 1442 BECM_AutoSarNMControl 1;
BA_ "U_CD43_MY16_Gas_Rx" SG_ 1442 BECM_AutoSarNMControl 1;
BA_ "U_CD4_MY14_Diesel_Rx" SG_ 1442 BECM_AutoSarNMControl 1;
BA_ "U_CD4_MY14_Gas_Rx" SG_ 1442 BECM_AutoSarNMControl 1;
BA_ "U_CD4_MY14_Hev_Rx" SG_ 1442 BECM_AutoSarNMControl 1;
BA_ "U_CD4_MY14_Phev_Rx" SG_ 1442 BECM_AutoSarNMControl 1;
BA_ "U_CD43_MY16_Gas_Rx" SG_ 1200 BrkAutoHold_D_Stat 1;
BA_ "U_CD4_MY17_Gas_Rx" SG_ 1200 BrkAutoHold_D_Stat 1;
BA_ "U_CD4_MY17_Hev_Rx" SG_ 1200 BrkAutoHold_D_Stat 1;
BA_ "U_CD4_MY17_Phev_Rx" SG_ 1200 BrkAutoHold_D_Stat 1;
BA_ "U_C489_MY17_Gas_Rx" SG_ 1200 BrkAutoHold_D_Stat 1;
BA_ "U_CD42_MY16_Gas_Rx" SG_ 1200 BrkAutoHold_D_Stat 1;
BA_ "U_CD43_MY17_Gas_Rx" SG_ 1200 BrkAutoHold_D_Stat 1;
BA_ "U_B515_MCA_MY17_Gas_Rx" SG_ 1200 BrkAutoHold_D_Stat 1;
BA_ "U_U55x_MY18_Gas_Rx" SG_ 1200 BrkAutoHold_D_Stat 1;
BA_ "U_V408_MY18_Gas_Rx" SG_ 1200 BrkAutoHold_D_Stat 1;
BA_ "U_V408_MY18_Diesel_Rx" SG_ 1200 BrkAutoHold_D_Stat 1;
BA_ "GenSigStartValue" SG_ 1200 BrkBstrVac_P_Actl 127;
BA_ "U_P552_MY15_Gas_Rx" SG_ 1200 BrkBstrVac_P_Actl 1;
BA_ "U_S550_MY15_Gas_Rx" SG_ 1200 BrkBstrVac_P_Actl 1;
BA_ "U_CD43_MY16_Gas_Rx" SG_ 1200 BrkBstrVac_P_Actl 1;
BA_ "GenSigStartValue" SG_ 1200 YawStabilityIndex 256;
BA_ "U_CD4_MY13_Gas_Rx" SG_ 1200 BrkTot_Tq_RqDrv 1;
BA_ "U_CD42_MY14_Gas_Rx" SG_ 1200 BrkTot_Tq_RqDrv 1;
BA_ "U_P552_MY15_Gas_Rx" SG_ 1200 BrkTot_Tq_RqDrv 1;
BA_ "U_U502_MY15_Gas_Rx" SG_ 1200 BrkTot_Tq_RqDrv 1;
BA_ "U_CD43_MY16_Gas_Rx" SG_ 1200 BrkTot_Tq_RqDrv 1;
BA_ "U_CD4_MY14_Gas_Rx" SG_ 1200 BrkTot_Tq_RqDrv 1;
BA_ "U_CD4_MY13_Gas_Rx" SG_ 1200 BrkTotTqRqDrv_No_Cnt 1;
BA_ "U_CD42_MY14_Gas_Rx" SG_ 1200 BrkTotTqRqDrv_No_Cnt 1;
BA_ "U_P552_MY15_Gas_Rx" SG_ 1200 BrkTotTqRqDrv_No_Cnt 1;
BA_ "U_U502_MY15_Gas_Rx" SG_ 1200 BrkTotTqRqDrv_No_Cnt 1;
BA_ "U_CD43_MY16_Gas_Rx" SG_ 1200 BrkTotTqRqDrv_No_Cnt 1;
BA_ "U_CD4_MY14_Gas_Rx" SG_ 1200 BrkTotTqRqDrv_No_Cnt 1;
BA_ "U_CD4_MY13_Gas_Rx" SG_ 1200 BrkTotTqRqDrv_No_Cs 1;
BA_ "U_CD42_MY14_Gas_Rx" SG_ 1200 BrkTotTqRqDrv_No_Cs 1;
BA_ "U_P552_MY15_Gas_Rx" SG_ 1200 BrkTotTqRqDrv_No_Cs 1;
BA_ "U_U502_MY15_Gas_Rx" SG_ 1200 BrkTotTqRqDrv_No_Cs 1;
BA_ "U_CD43_MY16_Gas_Rx" SG_ 1200 BrkTotTqRqDrv_No_Cs 1;
BA_ "U_CD4_MY14_Gas_Rx" SG_ 1200 BrkTotTqRqDrv_No_Cs 1;
BA_ "U_U502_MY16_Gas_Rx" SG_ 2015 TesterFunctionalReq 1;
BA_ "U_CD4_MY17_Diesel_Rx" SG_ 2015 TesterFunctionalReq 1;
BA_ "U_CD4_MY17_Gas_Rx" SG_ 2015 TesterFunctionalReq 1;
BA_ "U_CD4_MY17_Hev_Rx" SG_ 2015 TesterFunctionalReq 1;
BA_ "U_CD4_MY17_Phev_Rx" SG_ 2015 TesterFunctionalReq 1;
BA_ "U_P558_MY17_Gas_Rx" SG_ 2015 TesterFunctionalReq 1;
BA_ "U_P558_MY17_Diesel_Rx" SG_ 2015 TesterFunctionalReq 1;
BA_ "U_V36X_MY16_5_Diesel_Rx" SG_ 2015 TesterFunctionalReq 1;
BA_ "U_C489_MY17_Gas_Rx" SG_ 2015 TesterFunctionalReq 1;
BA_ "U_CD42_MY16_Diesel_Rx" SG_ 2015 TesterFunctionalReq 1;
BA_ "U_CD42_MY16_Gas_Rx" SG_ 2015 TesterFunctionalReq 1;
BA_ "U_CD43_MY17_Gas_Rx" SG_ 2015 TesterFunctionalReq 1;
BA_ "U_P552_MY17_Gas_Rx" SG_ 2015 TesterFunctionalReq 1;
BA_ "U_B515_MCA_MY17_Diesel_Rx" SG_ 2015 TesterFunctionalReq 1;
BA_ "U_B515_MCA_MY17_Gas_Rx" SG_ 2015 TesterFunctionalReq 1;
BA_ "U_U55x_MY18_Gas_Rx" SG_ 2015 TesterFunctionalReq 1;
BA_ "U_CD42_MY15_Diesel_Tx" SG_ 2015 TesterFunctionalReq 1;
BA_ "U_CD42_MY15_Gas_Tx" SG_ 2015 TesterFunctionalReq 1;
BA_ "CrossOver_InfoCAN" SG_ 2015 TesterFunctionalReq 1;
BA_ "GenSigSendType" SG_ 2015 TesterFunctionalReq 3;
BA_ "U_CD4_MY13_Phev_Rx" SG_ 2015 TesterFunctionalReq 1;
BA_ "U_CD42_MY14_Diesel_Rx" SG_ 2015 TesterFunctionalReq 1;
BA_ "U_CD42_MY14_Gas_Rx" SG_ 2015 TesterFunctionalReq 1;
BA_ "U_S550_MY15_Gas_Rx" SG_ 2015 TesterFunctionalReq 1;
BA_ "U_U502_MY15_Gas_Rx" SG_ 2015 TesterFunctionalReq 1;
BA_ "U_UP375_MY15_Gas_Rx" SG_ 2015 TesterFunctionalReq 1;
BA_ "U_UP375_MY15_Diesel_Rx" SG_ 2015 TesterFunctionalReq 1;
BA_ "U_CD43_MY16_Gas_Rx" SG_ 2015 TesterFunctionalReq 1;
BA_ "U_CD4_MY14_Diesel_Rx" SG_ 2015 TesterFunctionalReq 1;
BA_ "U_CD4_MY14_Gas_Rx" SG_ 2015 TesterFunctionalReq 1;
BA_ "U_CD4_MY14_Hev_Rx" SG_ 2015 TesterFunctionalReq 1;
BA_ "U_CD4_MY14_Phev_Rx" SG_ 2015 TesterFunctionalReq 1;
BA_ "U_CD4_MY13_Diesel_Tx" SG_ 2015 TesterFunctionalReq 1;
BA_ "U_CD4_MY13_Gas_Tx" SG_ 2015 TesterFunctionalReq 1;
BA_ "U_CD4_MY13_Hev_Tx" SG_ 2015 TesterFunctionalReq 1;
BA_ "U_CD4_MY13_Phev_Tx" SG_ 2015 TesterFunctionalReq 1;
BA_ "U_CD42_MY14_Diesel_Tx" SG_ 2015 TesterFunctionalReq 1;
BA_ "U_CD42_MY14_Gas_Tx" SG_ 2015 TesterFunctionalReq 1;
BA_ "U_P552_MY15_Gas_Tx" SG_ 2015 TesterFunctionalReq 1;
BA_ "U_S550_MY15_Gas_Tx" SG_ 2015 TesterFunctionalReq 1;
BA_ "U_C489_MY14_Gas_Tx" SG_ 2015 TesterFunctionalReq 1;
BA_ "ContentDependant" SG_ 376 GasPrtc_D_RqDsply 1;
BA_ "U_C489_MY17_Gas_Tx" SG_ 376 GasPrtc_D_RqDsply 1;
BA_ "U_CD43_MY17_Gas_Tx" SG_ 376 GasPrtc_D_RqDsply 1;
BA_ "U_U55x_MY18_Gas_Tx" SG_ 376 GasPrtc_D_RqDsply 1;
BA_ "U_S550_MY18_Gas_Tx" SG_ 376 GasPrtc_D_RqDsply 1;
BA_ "U_V408_MY18_Gas_Tx" SG_ 376 GasPrtc_D_RqDsply 1;
BA_ "ContentDependant" SG_ 376 PtcHtr_D_Cmd 1;
BA_ "U_CD42_MY16_Diesel_Tx" SG_ 376 PtcHtr_D_Cmd 1;
BA_ "U_V36X_MY16_5_Diesel_Tx" SG_ 376 PtcHtr_D_Cmd 1;
BA_ "U_P558_MY17_Diesel_Tx" SG_ 376 PtcHtr_D_Cmd 1;
BA_ "U_CD4_MY17_Phev_Tx" SG_ 376 PtcHtr_D_Cmd 1;
BA_ "U_CD4_MY14_Phev_Tx" SG_ 376 PtcHtr_D_Cmd 1;
BA_ "U_UP375_MY15_Diesel_Tx" SG_ 376 PtcHtr_D_Cmd 1;
BA_ "U_CD4_MY13_Phev_Tx" SG_ 376 PtcHtr_D_Cmd 1;
BA_ "U_CD4_MY17_Phev_Rx" SG_ 376 PtcHtr_D_Cmd 1;
BA_ "U_CD4_MY14_Phev_Rx" SG_ 376 PtcHtr_D_Cmd 1;
BA_ "U_CD4_MY13_Phev_Rx" SG_ 376 PtcHtr_D_Cmd 1;
BA_ "ContentDependant" SG_ 376 AslIconDsply_D_Rq 1;
BA_ "U_B515_MCA_MY17_Gas_Tx" SG_ 376 AslIconDsply_D_Rq 1;
BA_ "U_B515_MCA_MY17_Diesel_Tx" SG_ 376 AslIconDsply_D_Rq 1;
BA_ "U_CD43_MY17_Gas_Tx" SG_ 376 AslIconDsply_D_Rq 1;
BA_ "U_CD42_MY16_Diesel_Tx" SG_ 376 AslIconDsply_D_Rq 1;
BA_ "U_V36X_MY16_5_Diesel_Tx" SG_ 376 AslIconDsply_D_Rq 1;
BA_ "U_P558_MY17_Diesel_Tx" SG_ 376 AslIconDsply_D_Rq 1;
BA_ "U_CD4_MY17_Phev_Tx" SG_ 376 AslIconDsply_D_Rq 1;
BA_ "U_CD4_MY17_Hev_Tx" SG_ 376 AslIconDsply_D_Rq 1;
BA_ "U_CD4_MY17_Gas_Tx" SG_ 376 AslIconDsply_D_Rq 1;
BA_ "U_CD4_MY14_Phev_Tx" SG_ 376 AslIconDsply_D_Rq 1;
BA_ "U_CD4_MY14_Hev_Tx" SG_ 376 AslIconDsply_D_Rq 1;
BA_ "U_CD4_MY14_Gas_Tx" SG_ 376 AslIconDsply_D_Rq 1;
BA_ "U_CD43_MY16_Gas_Tx" SG_ 376 AslIconDsply_D_Rq 1;
BA_ "U_UP375_MY15_Diesel_Tx" SG_ 376 AslIconDsply_D_Rq 1;
BA_ "U_UP375_MY15_Gas_Tx" SG_ 376 AslIconDsply_D_Rq 1;
BA_ "U_CD4_MY13_Phev_Tx" SG_ 376 AslIconDsply_D_Rq 1;
BA_ "U_CD4_MY13_Hev_Tx" SG_ 376 AslIconDsply_D_Rq 1;
BA_ "ContentDependant" SG_ 376 AslChime_B_Rq 1;
BA_ "U_B515_MCA_MY17_Gas_Tx" SG_ 376 AslChime_B_Rq 1;
BA_ "U_B515_MCA_MY17_Diesel_Tx" SG_ 376 AslChime_B_Rq 1;
BA_ "U_CD43_MY17_Gas_Tx" SG_ 376 AslChime_B_Rq 1;
BA_ "U_CD42_MY16_Diesel_Tx" SG_ 376 AslChime_B_Rq 1;
BA_ "U_V36X_MY16_5_Diesel_Tx" SG_ 376 AslChime_B_Rq 1;
BA_ "U_P558_MY17_Diesel_Tx" SG_ 376 AslChime_B_Rq 1;
BA_ "U_CD4_MY17_Phev_Tx" SG_ 376 AslChime_B_Rq 1;
BA_ "U_CD4_MY17_Hev_Tx" SG_ 376 AslChime_B_Rq 1;
BA_ "U_CD4_MY17_Gas_Tx" SG_ 376 AslChime_B_Rq 1;
BA_ "U_CD4_MY14_Phev_Tx" SG_ 376 AslChime_B_Rq 1;
BA_ "U_CD4_MY14_Hev_Tx" SG_ 376 AslChime_B_Rq 1;
BA_ "U_CD4_MY14_Gas_Tx" SG_ 376 AslChime_B_Rq 1;
BA_ "U_CD43_MY16_Gas_Tx" SG_ 376 AslChime_B_Rq 1;
BA_ "U_UP375_MY15_Diesel_Tx" SG_ 376 AslChime_B_Rq 1;
BA_ "U_UP375_MY15_Gas_Tx" SG_ 376 AslChime_B_Rq 1;
BA_ "U_CD4_MY13_Phev_Tx" SG_ 376 AslChime_B_Rq 1;
BA_ "U_CD4_MY13_Hev_Tx" SG_ 376 AslChime_B_Rq 1;
BA_ "CrossOver_InfoCAN" SG_ 376 EngAout_Aa_Actl 1;
BA_ "ContentDependant" SG_ 376 EngAout_Aa_Actl 1;
BA_ "U_CD4_MY13_Gas_Tx" SG_ 376 EngAout_Aa_Actl 1;
BA_ "U_CD42_MY14_Gas_Tx" SG_ 376 EngAout_Aa_Actl 1;
BA_ "U_P552_MY15_Gas_Tx" SG_ 376 EngAout_Aa_Actl 1;
BA_ "U_S550_MY15_Gas_Tx" SG_ 376 EngAout_Aa_Actl 1;
BA_ "U_C489_MY14_Gas_Tx" SG_ 376 EngAout_Aa_Actl 1;
BA_ "U_U502_MY15_Gas_Tx" SG_ 376 EngAout_Aa_Actl 1;
BA_ "U_UP375_MY15_Gas_Tx" SG_ 376 EngAout_Aa_Actl 1;
BA_ "U_CD43_MY16_Gas_Tx" SG_ 376 EngAout_Aa_Actl 1;
BA_ "U_CD4_MY14_Gas_Tx" SG_ 376 EngAout_Aa_Actl 1;
BA_ "U_CD4_MY13_Gas_Tx" SG_ 376 DynoMde_B_Cmd 1;
BA_ "U_CD42_MY14_Gas_Tx" SG_ 376 DynoMde_B_Cmd 1;
BA_ "U_P552_MY15_Gas_Tx" SG_ 376 DynoMde_B_Cmd 1;
BA_ "U_S550_MY15_Gas_Tx" SG_ 376 DynoMde_B_Cmd 1;
BA_ "U_C489_MY14_Gas_Tx" SG_ 376 DynoMde_B_Cmd 1;
BA_ "U_U502_MY15_Gas_Tx" SG_ 376 DynoMde_B_Cmd 1;
BA_ "U_UP375_MY15_Gas_Tx" SG_ 376 DynoMde_B_Cmd 1;
BA_ "U_CD43_MY16_Gas_Tx" SG_ 376 DynoMde_B_Cmd 1;
BA_ "U_CD4_MY14_Gas_Tx" SG_ 376 DynoMde_B_Cmd 1;
BA_ "CrossOver_InfoCAN" SG_ 376 AirAmbTe_D_Qf 1;
BA_ "U_CD4_MY13_Diesel_Rx" SG_ 376 AirAmbTe_D_Qf 1;
BA_ "U_CD4_MY13_Gas_Rx" SG_ 376 AirAmbTe_D_Qf 1;
BA_ "U_CD4_MY13_Hev_Rx" SG_ 376 AirAmbTe_D_Qf 1;
BA_ "U_CD4_MY13_Phev_Rx" SG_ 376 AirAmbTe_D_Qf 1;
BA_ "U_CD42_MY14_Diesel_Rx" SG_ 376 AirAmbTe_D_Qf 1;
BA_ "U_CD42_MY14_Gas_Rx" SG_ 376 AirAmbTe_D_Qf 1;
BA_ "U_P552_MY15_Gas_Rx" SG_ 376 AirAmbTe_D_Qf 1;
BA_ "U_S550_MY15_Gas_Rx" SG_ 376 AirAmbTe_D_Qf 1;
BA_ "U_C489_MY14_Gas_Rx" SG_ 376 AirAmbTe_D_Qf 1;
BA_ "U_U502_MY15_Gas_Rx" SG_ 376 AirAmbTe_D_Qf 1;
BA_ "U_UP375_MY15_Gas_Rx" SG_ 376 AirAmbTe_D_Qf 1;
BA_ "U_UP375_MY15_Diesel_Rx" SG_ 376 AirAmbTe_D_Qf 1;
BA_ "U_CD43_MY16_Gas_Rx" SG_ 376 AirAmbTe_D_Qf 1;
BA_ "U_CD4_MY14_Diesel_Rx" SG_ 376 AirAmbTe_D_Qf 1;
BA_ "U_CD4_MY14_Gas_Rx" SG_ 376 AirAmbTe_D_Qf 1;
BA_ "U_CD4_MY14_Hev_Rx" SG_ 376 AirAmbTe_D_Qf 1;
BA_ "U_CD4_MY14_Phev_Rx" SG_ 376 AirAmbTe_D_Qf 1;
BA_ "U_CD4_MY13_Gas_Tx" SG_ 376 AirAmbTe_D_Qf 1;
BA_ "U_CD42_MY14_Gas_Tx" SG_ 376 AirAmbTe_D_Qf 1;
BA_ "U_P552_MY15_Gas_Tx" SG_ 376 AirAmbTe_D_Qf 1;
BA_ "U_S550_MY15_Gas_Tx" SG_ 376 AirAmbTe_D_Qf 1;
BA_ "U_C489_MY14_Gas_Tx" SG_ 376 AirAmbTe_D_Qf 1;
BA_ "U_U502_MY15_Gas_Tx" SG_ 376 AirAmbTe_D_Qf 1;
BA_ "U_UP375_MY15_Gas_Tx" SG_ 376 AirAmbTe_D_Qf 1;
BA_ "U_CD43_MY16_Gas_Tx" SG_ 376 AirAmbTe_D_Qf 1;
BA_ "U_CD4_MY14_Gas_Tx" SG_ 376 AirAmbTe_D_Qf 1;
BA_ "CrossOver_InfoCAN" SG_ 376 AirAmb_Te_ActlFilt 1;
BA_ "GenSigStartValue" SG_ 376 AirAmb_Te_ActlFilt 512;
BA_ "U_CD4_MY13_Diesel_Rx" SG_ 376 AirAmb_Te_ActlFilt 1;
BA_ "U_CD4_MY13_Gas_Rx" SG_ 376 AirAmb_Te_ActlFilt 1;
BA_ "U_CD4_MY13_Hev_Rx" SG_ 376 AirAmb_Te_ActlFilt 1;
BA_ "U_CD4_MY13_Phev_Rx" SG_ 376 AirAmb_Te_ActlFilt 1;
BA_ "U_CD42_MY14_Diesel_Rx" SG_ 376 AirAmb_Te_ActlFilt 1;
BA_ "U_CD42_MY14_Gas_Rx" SG_ 376 AirAmb_Te_ActlFilt 1;
BA_ "U_P552_MY15_Gas_Rx" SG_ 376 AirAmb_Te_ActlFilt 1;
BA_ "U_S550_MY15_Gas_Rx" SG_ 376 AirAmb_Te_ActlFilt 1;
BA_ "U_C489_MY14_Gas_Rx" SG_ 376 AirAmb_Te_ActlFilt 1;
BA_ "U_U502_MY15_Gas_Rx" SG_ 376 AirAmb_Te_ActlFilt 1;
BA_ "U_UP375_MY15_Gas_Rx" SG_ 376 AirAmb_Te_ActlFilt 1;
BA_ "U_UP375_MY15_Diesel_Rx" SG_ 376 AirAmb_Te_ActlFilt 1;
BA_ "U_CD43_MY16_Gas_Rx" SG_ 376 AirAmb_Te_ActlFilt 1;
BA_ "U_CD4_MY14_Diesel_Rx" SG_ 376 AirAmb_Te_ActlFilt 1;
BA_ "U_CD4_MY14_Gas_Rx" SG_ 376 AirAmb_Te_ActlFilt 1;
BA_ "U_CD4_MY14_Hev_Rx" SG_ 376 AirAmb_Te_ActlFilt 1;
BA_ "U_CD4_MY14_Phev_Rx" SG_ 376 AirAmb_Te_ActlFilt 1;
BA_ "U_CD4_MY13_Gas_Tx" SG_ 376 AirAmb_Te_ActlFilt 1;
BA_ "U_CD42_MY14_Gas_Tx" SG_ 376 AirAmb_Te_ActlFilt 1;
BA_ "U_P552_MY15_Gas_Tx" SG_ 376 AirAmb_Te_ActlFilt 1;
BA_ "U_S550_MY15_Gas_Tx" SG_ 376 AirAmb_Te_ActlFilt 1;
BA_ "U_C489_MY14_Gas_Tx" SG_ 376 AirAmb_Te_ActlFilt 1;
BA_ "U_U502_MY15_Gas_Tx" SG_ 376 AirAmb_Te_ActlFilt 1;
BA_ "U_UP375_MY15_Gas_Tx" SG_ 376 AirAmb_Te_ActlFilt 1;
BA_ "U_CD43_MY16_Gas_Tx" SG_ 376 AirAmb_Te_ActlFilt 1;
BA_ "U_CD4_MY14_Gas_Tx" SG_ 376 AirAmb_Te_ActlFilt 1;
BA_ "CrossOver_InfoCAN" SG_ 376 AirAmb_Te_Actl 1;
BA_ "GenSigStartValue" SG_ 376 AirAmb_Te_Actl 512;
BA_ "U_CD4_MY13_Diesel_Rx" SG_ 376 AirAmb_Te_Actl 1;
BA_ "U_CD4_MY13_Gas_Rx" SG_ 376 AirAmb_Te_Actl 1;
BA_ "U_CD4_MY13_Hev_Rx" SG_ 376 AirAmb_Te_Actl 1;
BA_ "U_CD4_MY13_Phev_Rx" SG_ 376 AirAmb_Te_Actl 1;
BA_ "U_CD42_MY14_Diesel_Rx" SG_ 376 AirAmb_Te_Actl 1;
BA_ "U_CD42_MY14_Gas_Rx" SG_ 376 AirAmb_Te_Actl 1;
BA_ "U_P552_MY15_Gas_Rx" SG_ 376 AirAmb_Te_Actl 1;
BA_ "U_S550_MY15_Gas_Rx" SG_ 376 AirAmb_Te_Actl 1;
BA_ "U_C489_MY14_Gas_Rx" SG_ 376 AirAmb_Te_Actl 1;
BA_ "U_U502_MY15_Gas_Rx" SG_ 376 AirAmb_Te_Actl 1;
BA_ "U_UP375_MY15_Gas_Rx" SG_ 376 AirAmb_Te_Actl 1;
BA_ "U_UP375_MY15_Diesel_Rx" SG_ 376 AirAmb_Te_Actl 1;
BA_ "U_CD43_MY16_Gas_Rx" SG_ 376 AirAmb_Te_Actl 1;
BA_ "U_CD4_MY14_Diesel_Rx" SG_ 376 AirAmb_Te_Actl 1;
BA_ "U_CD4_MY14_Gas_Rx" SG_ 376 AirAmb_Te_Actl 1;
BA_ "U_CD4_MY14_Hev_Rx" SG_ 376 AirAmb_Te_Actl 1;
BA_ "U_CD4_MY14_Phev_Rx" SG_ 376 AirAmb_Te_Actl 1;
BA_ "U_CD4_MY13_Gas_Tx" SG_ 376 AirAmb_Te_Actl 1;
BA_ "U_CD42_MY14_Gas_Tx" SG_ 376 AirAmb_Te_Actl 1;
BA_ "U_P552_MY15_Gas_Tx" SG_ 376 AirAmb_Te_Actl 1;
BA_ "U_S550_MY15_Gas_Tx" SG_ 376 AirAmb_Te_Actl 1;
BA_ "U_C489_MY14_Gas_Tx" SG_ 376 AirAmb_Te_Actl 1;
BA_ "U_U502_MY15_Gas_Tx" SG_ 376 AirAmb_Te_Actl 1;
BA_ "U_UP375_MY15_Gas_Tx" SG_ 376 AirAmb_Te_Actl 1;
BA_ "U_CD43_MY16_Gas_Tx" SG_ 376 AirAmb_Te_Actl 1;
BA_ "U_CD4_MY14_Gas_Tx" SG_ 376 AirAmb_Te_Actl 1;
BA_ "CrossOver_InfoCAN" SG_ 376 AirAmb_P_Actl 1;
BA_ "U_CD4_MY13_Phev_Rx" SG_ 376 AirAmb_P_Actl 1;
BA_ "U_CD42_MY14_Diesel_Rx" SG_ 376 AirAmb_P_Actl 1;
BA_ "U_CD42_MY14_Gas_Rx" SG_ 376 AirAmb_P_Actl 1;
BA_ "U_P552_MY15_Gas_Rx" SG_ 376 AirAmb_P_Actl 1;
BA_ "U_S550_MY15_Gas_Rx" SG_ 376 AirAmb_P_Actl 1;
BA_ "U_C489_MY14_Gas_Rx" SG_ 376 AirAmb_P_Actl 1;
BA_ "U_U502_MY15_Gas_Rx" SG_ 376 AirAmb_P_Actl 1;
BA_ "U_UP375_MY15_Gas_Rx" SG_ 376 AirAmb_P_Actl 1;
BA_ "U_UP375_MY15_Diesel_Rx" SG_ 376 AirAmb_P_Actl 1;
BA_ "U_CD43_MY16_Gas_Rx" SG_ 376 AirAmb_P_Actl 1;
BA_ "U_CD4_MY14_Diesel_Rx" SG_ 376 AirAmb_P_Actl 1;
BA_ "U_CD4_MY14_Gas_Rx" SG_ 376 AirAmb_P_Actl 1;
BA_ "U_CD4_MY14_Hev_Rx" SG_ 376 AirAmb_P_Actl 1;
BA_ "U_CD4_MY14_Phev_Rx" SG_ 376 AirAmb_P_Actl 1;
BA_ "U_CD4_MY13_Gas_Tx" SG_ 376 AirAmb_P_Actl 1;
BA_ "U_CD42_MY14_Gas_Tx" SG_ 376 AirAmb_P_Actl 1;
BA_ "U_P552_MY15_Gas_Tx" SG_ 376 AirAmb_P_Actl 1;
BA_ "U_S550_MY15_Gas_Tx" SG_ 376 AirAmb_P_Actl 1;
BA_ "U_C489_MY14_Gas_Tx" SG_ 376 AirAmb_P_Actl 1;
BA_ "U_U502_MY15_Gas_Tx" SG_ 376 AirAmb_P_Actl 1;
BA_ "U_UP375_MY15_Gas_Tx" SG_ 376 AirAmb_P_Actl 1;
BA_ "U_CD43_MY16_Gas_Tx" SG_ 376 AirAmb_P_Actl 1;
BA_ "U_CD4_MY14_Gas_Tx" SG_ 376 AirAmb_P_Actl 1;
BA_ "GenSigTimeoutTime_TCM" SG_ 376 AirAmb_P_Actl 300;
BA_ "CrossOver_InfoCAN" SG_ 516 ApedPos_PcRate_ActlArb 1;
BA_ "U_CD4_MY13_Gas_Tx" SG_ 516 ApedPos_PcRate_ActlArb 1;
BA_ "U_CD42_MY14_Gas_Tx" SG_ 516 ApedPos_PcRate_ActlArb 1;
BA_ "U_P552_MY15_Gas_Tx" SG_ 516 ApedPos_PcRate_ActlArb 1;
BA_ "U_S550_MY15_Gas_Tx" SG_ 516 ApedPos_PcRate_ActlArb 1;
BA_ "U_C489_MY14_Gas_Tx" SG_ 516 ApedPos_PcRate_ActlArb 1;
BA_ "U_U502_MY15_Gas_Tx" SG_ 516 ApedPos_PcRate_ActlArb 1;
BA_ "U_CD43_MY16_Gas_Tx" SG_ 516 ApedPos_PcRate_ActlArb 1;
BA_ "U_CD4_MY14_Gas_Tx" SG_ 516 ApedPos_PcRate_ActlArb 1;
BA_ "GenSigTimeoutTime_TCM" SG_ 516 ApedPos_PcRate_ActlArb 30;
BA_ "CrossOver_InfoCAN" SG_ 516 ApedPos_Pc_ActlArb 1;
BA_ "U_CD4_MY13_Diesel_Rx" SG_ 516 ApedPos_Pc_ActlArb 1;
BA_ "U_CD4_MY13_Gas_Rx" SG_ 516 ApedPos_Pc_ActlArb 1;
BA_ "U_CD4_MY13_Hev_Rx" SG_ 516 ApedPos_Pc_ActlArb 1;
BA_ "U_CD4_MY13_Phev_Rx" SG_ 516 ApedPos_Pc_ActlArb 1;
BA_ "U_CD42_MY14_Diesel_Rx" SG_ 516 ApedPos_Pc_ActlArb 1;
BA_ "U_CD42_MY14_Gas_Rx" SG_ 516 ApedPos_Pc_ActlArb 1;
BA_ "U_P552_MY15_Gas_Rx" SG_ 516 ApedPos_Pc_ActlArb 1;
BA_ "U_S550_MY15_Gas_Rx" SG_ 516 ApedPos_Pc_ActlArb 1;
BA_ "U_C489_MY14_Gas_Rx" SG_ 516 ApedPos_Pc_ActlArb 1;
BA_ "U_U502_MY15_Gas_Rx" SG_ 516 ApedPos_Pc_ActlArb 1;
BA_ "U_UP375_MY15_Gas_Rx" SG_ 516 ApedPos_Pc_ActlArb 1;
BA_ "U_UP375_MY15_Diesel_Rx" SG_ 516 ApedPos_Pc_ActlArb 1;
BA_ "U_CD43_MY16_Gas_Rx" SG_ 516 ApedPos_Pc_ActlArb 1;
BA_ "U_CD4_MY14_Diesel_Rx" SG_ 516 ApedPos_Pc_ActlArb 1;
BA_ "U_CD4_MY14_Gas_Rx" SG_ 516 ApedPos_Pc_ActlArb 1;
BA_ "U_CD4_MY14_Hev_Rx" SG_ 516 ApedPos_Pc_ActlArb 1;
BA_ "U_CD4_MY14_Phev_Rx" SG_ 516 ApedPos_Pc_ActlArb 1;
BA_ "U_CD4_MY13_Gas_Tx" SG_ 516 ApedPos_Pc_ActlArb 1;
BA_ "U_CD42_MY14_Gas_Tx" SG_ 516 ApedPos_Pc_ActlArb 1;
BA_ "U_P552_MY15_Gas_Tx" SG_ 516 ApedPos_Pc_ActlArb 1;
BA_ "U_S550_MY15_Gas_Tx" SG_ 516 ApedPos_Pc_ActlArb 1;
BA_ "U_C489_MY14_Gas_Tx" SG_ 516 ApedPos_Pc_ActlArb 1;
BA_ "U_U502_MY15_Gas_Tx" SG_ 516 ApedPos_Pc_ActlArb 1;
BA_ "U_CD43_MY16_Gas_Tx" SG_ 516 ApedPos_Pc_ActlArb 1;
BA_ "U_CD4_MY14_Gas_Tx" SG_ 516 ApedPos_Pc_ActlArb 1;
BA_ "GenSigTimeoutTime_TCM" SG_ 516 ApedPos_Pc_ActlArb 30;
BA_ "CrossOver_InfoCAN" SG_ 516 ApedPosPcActl_D_Qf 1;
BA_ "U_CD4_MY13_Gas_Tx" SG_ 516 ApedPosPcActl_D_Qf 1;
BA_ "U_CD42_MY14_Gas_Tx" SG_ 516 ApedPosPcActl_D_Qf 1;
BA_ "U_P552_MY15_Gas_Tx" SG_ 516 ApedPosPcActl_D_Qf 1;
BA_ "U_S550_MY15_Gas_Tx" SG_ 516 ApedPosPcActl_D_Qf 1;
BA_ "U_C489_MY14_Gas_Tx" SG_ 516 ApedPosPcActl_D_Qf 1;
BA_ "U_U502_MY15_Gas_Tx" SG_ 516 ApedPosPcActl_D_Qf 1;
BA_ "U_CD43_MY16_Gas_Tx" SG_ 516 ApedPosPcActl_D_Qf 1;
BA_ "U_CD4_MY14_Gas_Tx" SG_ 516 ApedPosPcActl_D_Qf 1;
BA_ "GenSigTimeoutTime_TCM" SG_ 516 ApedPosPcActl_D_Qf 30;
BA_ "CrossOver_InfoCAN" SG_ 516 EngAout_N_Actl 1;
BA_ "U_CD4_MY13_Phev_Rx" SG_ 516 EngAout_N_Actl 1;
BA_ "U_CD42_MY14_Diesel_Rx" SG_ 516 EngAout_N_Actl 1;
BA_ "U_CD42_MY14_Gas_Rx" SG_ 516 EngAout_N_Actl 1;
BA_ "U_P552_MY15_Gas_Rx" SG_ 516 EngAout_N_Actl 1;
BA_ "U_S550_MY15_Gas_Rx" SG_ 516 EngAout_N_Actl 1;
BA_ "U_C489_MY14_Gas_Rx" SG_ 516 EngAout_N_Actl 1;
BA_ "U_U502_MY15_Gas_Rx" SG_ 516 EngAout_N_Actl 1;
BA_ "U_UP375_MY15_Gas_Rx" SG_ 516 EngAout_N_Actl 1;
BA_ "U_UP375_MY15_Diesel_Rx" SG_ 516 EngAout_N_Actl 1;
BA_ "U_CD43_MY16_Gas_Rx" SG_ 516 EngAout_N_Actl 1;
BA_ "U_CD4_MY14_Diesel_Rx" SG_ 516 EngAout_N_Actl 1;
BA_ "U_CD4_MY14_Gas_Rx" SG_ 516 EngAout_N_Actl 1;
BA_ "U_CD4_MY14_Hev_Rx" SG_ 516 EngAout_N_Actl 1;
BA_ "U_CD4_MY14_Phev_Rx" SG_ 516 EngAout_N_Actl 1;
BA_ "U_CD4_MY13_Gas_Tx" SG_ 516 EngAout_N_Actl 1;
BA_ "U_CD42_MY14_Gas_Tx" SG_ 516 EngAout_N_Actl 1;
BA_ "U_P552_MY15_Gas_Tx" SG_ 516 EngAout_N_Actl 1;
BA_ "U_S550_MY15_Gas_Tx" SG_ 516 EngAout_N_Actl 1;
BA_ "U_C489_MY14_Gas_Tx" SG_ 516 EngAout_N_Actl 1;
BA_ "U_U502_MY15_Gas_Tx" SG_ 516 EngAout_N_Actl 1;
BA_ "U_CD43_MY16_Gas_Tx" SG_ 516 EngAout_N_Actl 1;
BA_ "U_CD4_MY14_Gas_Tx" SG_ 516 EngAout_N_Actl 1;
BA_ "GenSigTimeoutTime_TCM" SG_ 516 EngAout_N_Actl 30;
BA_ "ContentDependant" SG_ 377 TrnManShif_D_IndDrv 1;
BA_ "CrossOver_InfoCAN" SG_ 377 TrnManShif_D_IndDrv 1;
BA_ "U_CD4_MY13_Gas_Tx" SG_ 377 TrnManShif_D_IndDrv 1;
BA_ "U_S550_MY15_Gas_Tx" SG_ 377 TrnManShif_D_IndDrv 1;
BA_ "U_C489_MY14_Gas_Tx" SG_ 377 TrnManShif_D_IndDrv 1;
BA_ "U_UP375_MY15_Diesel_Tx" SG_ 377 TrnManShif_D_IndDrv 1;
BA_ "U_CD4_MY14_Gas_Tx" SG_ 377 TrnManShif_D_IndDrv 1;
BA_ "U_CD4_MY17_Gas_Tx" SG_ 377 TrnManShif_D_IndDrv 1;
BA_ "U_P558_MY17_Gas_Tx" SG_ 377 TrnManShif_D_IndDrv 1;
BA_ "U_P558_MY17_Diesel_Tx" SG_ 377 TrnManShif_D_IndDrv 1;
BA_ "U_V36X_MY16_5_Diesel_Tx" SG_ 377 TrnManShif_D_IndDrv 1;
BA_ "U_CD42_MY16_Diesel_Tx" SG_ 377 TrnManShif_D_IndDrv 1;
BA_ "U_CD42_MY16_Gas_Tx" SG_ 377 TrnManShif_D_IndDrv 1;
BA_ "U_B515_MCA_MY17_Diesel_Tx" SG_ 377 TrnManShif_D_IndDrv 1;
BA_ "U_B515_MCA_MY17_Gas_Tx" SG_ 377 TrnManShif_D_IndDrv 1;
BA_ "U_CD4_MY18_Gas_Tx" SG_ 377 TrnManShif_D_IndDrv 1;
BA_ "U_S550_MY18_Gas_Tx" SG_ 377 TrnManShif_D_IndDrv 1;
BA_ "U_V408_MY18_Gas_Tx" SG_ 377 TrnManShif_D_IndDrv 1;
BA_ "U_V408_MY18_Diesel_Tx" SG_ 377 TrnManShif_D_IndDrv 1;
BA_ "U_P552_MY18_5_Diesel_Tx" SG_ 377 TrnManShif_D_IndDrv 1;
BA_ "U_CD42_MY16_Diesel_Tx" SG_ 377 TrnKickDown_B_RqDrv 1;
BA_ "U_V36X_MY16_5_Diesel_Tx" SG_ 377 TrnKickDown_B_RqDrv 1;
BA_ "U_P558_MY17_Diesel_Tx" SG_ 377 TrnKickDown_B_RqDrv 1;
BA_ "U_UP375_MY15_Diesel_Tx" SG_ 377 TrnKickDown_B_RqDrv 1;
BA_ "U_CD42_MY16_Gas_Rx" SG_ 377 TrnKickDown_B_RqDrv 1;
BA_ "ContentDependant" SG_ 377 TrnKickDown_B_RqDrv 1;
BA_ "CrossOver_InfoCAN" SG_ 377 TrnKickDown_B_RqDrv 1;
BA_ "ContentDependant" SG_ 377 FuelFilterLamp_B_Dsply 1;
BA_ "U_B515_MCA_MY17_Diesel_Tx" SG_ 377 FuelFilterLamp_B_Dsply 1;
BA_ "U_V36X_MY16_5_Diesel_Tx" SG_ 377 FuelFilterLamp_B_Dsply 1;
BA_ "U_UP375_MY15_Diesel_Tx" SG_ 377 FuelFilterLamp_B_Dsply 1;
BA_ "CrossOver_InfoCAN" SG_ 377 FuelFilterLamp_B_Dsply 1;
BA_ "CrossOver_InfoCAN" SG_ 377 FuelFlw_Vl_Dsply 1;
BA_ "U_CD4_MY13_Gas_Tx" SG_ 377 FuelFlw_Vl_Dsply 1;
BA_ "U_CD42_MY14_Gas_Tx" SG_ 377 FuelFlw_Vl_Dsply 1;
BA_ "U_P552_MY15_Gas_Tx" SG_ 377 FuelFlw_Vl_Dsply 1;
BA_ "U_S550_MY15_Gas_Tx" SG_ 377 FuelFlw_Vl_Dsply 1;
BA_ "U_C489_MY14_Gas_Tx" SG_ 377 FuelFlw_Vl_Dsply 1;
BA_ "U_U502_MY15_Gas_Tx" SG_ 377 FuelFlw_Vl_Dsply 1;
BA_ "U_UP375_MY15_Gas_Tx" SG_ 377 FuelFlw_Vl_Dsply 1;
BA_ "U_CD43_MY16_Gas_Tx" SG_ 377 FuelFlw_Vl_Dsply 1;
BA_ "U_CD4_MY14_Gas_Tx" SG_ 377 FuelFlw_Vl_Dsply 1;
BA_ "CrossOver_InfoCAN" SG_ 377 FuelFillInlet_B_Dsply 1;
BA_ "ContentDependant" SG_ 377 FuelFillInlet_B_Dsply 1;
BA_ "U_CD4_MY13_Gas_Tx" SG_ 377 FuelFillInlet_B_Dsply 1;
BA_ "U_CD42_MY14_Gas_Tx" SG_ 377 FuelFillInlet_B_Dsply 1;
BA_ "U_P552_MY15_Gas_Tx" SG_ 377 FuelFillInlet_B_Dsply 1;
BA_ "U_S550_MY15_Gas_Tx" SG_ 377 FuelFillInlet_B_Dsply 1;
BA_ "U_C489_MY14_Gas_Tx" SG_ 377 FuelFillInlet_B_Dsply 1;
BA_ "U_U502_MY15_Gas_Tx" SG_ 377 FuelFillInlet_B_Dsply 1;
BA_ "U_UP375_MY15_Gas_Tx" SG_ 377 FuelFillInlet_B_Dsply 1;
BA_ "U_CD43_MY16_Gas_Tx" SG_ 377 FuelFillInlet_B_Dsply 1;
BA_ "U_CD4_MY14_Gas_Tx" SG_ 377 FuelFillInlet_B_Dsply 1;
BA_ "CrossOver_InfoCAN" SG_ 377 EngSrvcRqd_B_Rq 1;
BA_ "U_CD4_MY13_Gas_Tx" SG_ 377 EngSrvcRqd_B_Rq 1;
BA_ "U_CD42_MY14_Gas_Tx" SG_ 377 EngSrvcRqd_B_Rq 1;
BA_ "U_P552_MY15_Gas_Tx" SG_ 377 EngSrvcRqd_B_Rq 1;
BA_ "U_S550_MY15_Gas_Tx" SG_ 377 EngSrvcRqd_B_Rq 1;
BA_ "U_C489_MY14_Gas_Tx" SG_ 377 EngSrvcRqd_B_Rq 1;
BA_ "U_U502_MY15_Gas_Tx" SG_ 377 EngSrvcRqd_B_Rq 1;
BA_ "U_UP375_MY15_Gas_Tx" SG_ 377 EngSrvcRqd_B_Rq 1;
BA_ "U_CD43_MY16_Gas_Tx" SG_ 377 EngSrvcRqd_B_Rq 1;
BA_ "U_CD4_MY14_Gas_Tx" SG_ 377 EngSrvcRqd_B_Rq 1;
BA_ "CrossOver_InfoCAN" SG_ 377 OdoCount 1;
BA_ "ContentDependant" SG_ 377 OdoCount 1;
BA_ "U_CD4_MY13_Gas_Tx" SG_ 377 OdoCount 1;
BA_ "U_CD42_MY14_Gas_Tx" SG_ 377 OdoCount 1;
BA_ "U_P552_MY15_Gas_Tx" SG_ 377 OdoCount 1;
BA_ "U_S550_MY15_Gas_Tx" SG_ 377 OdoCount 1;
BA_ "U_C489_MY14_Gas_Tx" SG_ 377 OdoCount 1;
BA_ "U_U502_MY15_Gas_Tx" SG_ 377 OdoCount 1;
BA_ "U_UP375_MY15_Gas_Tx" SG_ 377 OdoCount 1;
BA_ "U_CD43_MY16_Gas_Tx" SG_ 377 OdoCount 1;
BA_ "U_CD4_MY14_Gas_Tx" SG_ 377 OdoCount 1;
BA_ "CrossOver_InfoCAN" SG_ 377 EngOilLife_Pc_Actl 1;
BA_ "ContentDependant" SG_ 377 EngOilLife_Pc_Actl 1;
BA_ "U_CD4_MY13_Gas_Tx" SG_ 377 EngOilLife_Pc_Actl 1;
BA_ "U_CD42_MY14_Gas_Tx" SG_ 377 EngOilLife_Pc_Actl 1;
BA_ "U_P552_MY15_Gas_Tx" SG_ 377 EngOilLife_Pc_Actl 1;
BA_ "U_S550_MY15_Gas_Tx" SG_ 377 EngOilLife_Pc_Actl 1;
BA_ "U_C489_MY14_Gas_Tx" SG_ 377 EngOilLife_Pc_Actl 1;
BA_ "U_U502_MY15_Gas_Tx" SG_ 377 EngOilLife_Pc_Actl 1;
BA_ "U_UP375_MY15_Gas_Tx" SG_ 377 EngOilLife_Pc_Actl 1;
BA_ "U_CD43_MY16_Gas_Tx" SG_ 377 EngOilLife_Pc_Actl 1;
BA_ "U_CD4_MY14_Gas_Tx" SG_ 377 EngOilLife_Pc_Actl 1;
BA_ "CrossOver_InfoCAN" SG_ 377 AirCondRec_B_Rq 1;
BA_ "ContentDependant" SG_ 377 AirCondRec_B_Rq 1;
BA_ "U_CD4_MY13_Gas_Tx" SG_ 377 AirCondRec_B_Rq 1;
BA_ "U_CD42_MY14_Gas_Tx" SG_ 377 AirCondRec_B_Rq 1;
BA_ "U_P552_MY15_Gas_Tx" SG_ 377 AirCondRec_B_Rq 1;
BA_ "U_S550_MY15_Gas_Tx" SG_ 377 AirCondRec_B_Rq 1;
BA_ "U_C489_MY14_Gas_Tx" SG_ 377 AirCondRec_B_Rq 1;
BA_ "U_U502_MY15_Gas_Tx" SG_ 377 AirCondRec_B_Rq 1;
BA_ "U_UP375_MY15_Gas_Tx" SG_ 377 AirCondRec_B_Rq 1;
BA_ "U_CD43_MY16_Gas_Tx" SG_ 377 AirCondRec_B_Rq 1;
BA_ "U_CD4_MY14_Gas_Tx" SG_ 377 AirCondRec_B_Rq 1;
BA_ "CrossOver_InfoCAN" SG_ 377 AirCondClutch_B_Stats 1;
BA_ "ContentDependant" SG_ 377 AirCondClutch_B_Stats 1;
BA_ "U_CD4_MY13_Gas_Tx" SG_ 377 AirCondClutch_B_Stats 1;
BA_ "U_CD42_MY14_Gas_Tx" SG_ 377 AirCondClutch_B_Stats 1;
BA_ "U_P552_MY15_Gas_Tx" SG_ 377 AirCondClutch_B_Stats 1;
BA_ "U_S550_MY15_Gas_Tx" SG_ 377 AirCondClutch_B_Stats 1;
BA_ "U_C489_MY14_Gas_Tx" SG_ 377 AirCondClutch_B_Stats 1;
BA_ "U_U502_MY15_Gas_Tx" SG_ 377 AirCondClutch_B_Stats 1;
BA_ "U_UP375_MY15_Gas_Tx" SG_ 377 AirCondClutch_B_Stats 1;
BA_ "U_CD43_MY16_Gas_Tx" SG_ 377 AirCondClutch_B_Stats 1;
BA_ "U_CD4_MY14_Gas_Tx" SG_ 377 AirCondClutch_B_Stats 1;
BA_ "GenSigStartValue" SG_ 369 TrnIpcDsplyRng2_D_Actl 15;
BA_ "U_P558_MY17_Gas_Tx" SG_ 369 TrnIpcDsplyRng2_D_Actl 1;
BA_ "U_P558_MY17_Diesel_Tx" SG_ 369 TrnIpcDsplyRng2_D_Actl 1;
BA_ "U_V36X_MY16_5_Diesel_Tx" SG_ 369 TrnIpcDsplyRng2_D_Actl 1;
BA_ "U_P552_MY15_Gas_Tx" SG_ 369 TrnIpcDsplyRng_D_Stat 1;
BA_ "CrossOver_InfoCAN" SG_ 369 TrnIpcDsplyGear_D_Actl 1;
BA_ "U_CD4_MY13_Gas_Tx" SG_ 369 TrnIpcDsplyGear_D_Actl 1;
BA_ "U_CD42_MY14_Gas_Tx" SG_ 369 TrnIpcDsplyGear_D_Actl 1;
BA_ "U_P552_MY15_Gas_Tx" SG_ 369 TrnIpcDsplyGear_D_Actl 1;
BA_ "U_S550_MY15_Gas_Tx" SG_ 369 TrnIpcDsplyGear_D_Actl 1;
BA_ "U_C489_MY14_Gas_Tx" SG_ 369 TrnIpcDsplyGear_D_Actl 1;
BA_ "U_U502_MY15_Gas_Tx" SG_ 369 TrnIpcDsplyGear_D_Actl 1;
BA_ "U_UP375_MY15_Gas_Tx" SG_ 369 TrnIpcDsplyGear_D_Actl 1;
BA_ "U_CD43_MY16_Gas_Tx" SG_ 369 TrnIpcDsplyGear_D_Actl 1;
BA_ "U_CD4_MY14_Gas_Tx" SG_ 369 TrnIpcDsplyGear_D_Actl 1;
BA_ "WakeupSignal" SG_ 369 TrnIpcDsplyMde_D_Stat 1;
BA_ "CrossOver_InfoCAN" SG_ 369 TrnIpcDsplyMde_D_Stat 1;
BA_ "U_CD4_MY13_Diesel_Rx" SG_ 369 TrnIpcDsplyMde_D_Stat 1;
BA_ "U_CD4_MY13_Gas_Rx" SG_ 369 TrnIpcDsplyMde_D_Stat 1;
BA_ "U_CD4_MY13_Hev_Rx" SG_ 369 TrnIpcDsplyMde_D_Stat 1;
BA_ "U_CD4_MY13_Phev_Rx" SG_ 369 TrnIpcDsplyMde_D_Stat 1;
BA_ "U_CD42_MY14_Diesel_Rx" SG_ 369 TrnIpcDsplyMde_D_Stat 1;
BA_ "U_CD42_MY14_Gas_Rx" SG_ 369 TrnIpcDsplyMde_D_Stat 1;
BA_ "U_P552_MY15_Gas_Rx" SG_ 369 TrnIpcDsplyMde_D_Stat 1;
BA_ "U_S550_MY15_Gas_Rx" SG_ 369 TrnIpcDsplyMde_D_Stat 1;
BA_ "U_C489_MY14_Gas_Rx" SG_ 369 TrnIpcDsplyMde_D_Stat 1;
BA_ "U_U502_MY15_Gas_Rx" SG_ 369 TrnIpcDsplyMde_D_Stat 1;
BA_ "U_B479_MY15_Gas_Rx" SG_ 369 TrnIpcDsplyMde_D_Stat 1;
BA_ "U_UP375_MY15_Gas_Rx" SG_ 369 TrnIpcDsplyMde_D_Stat 1;
BA_ "U_UP375_MY15_Diesel_Rx" SG_ 369 TrnIpcDsplyMde_D_Stat 1;
BA_ "U_CD4_MY13_Gas_Tx" SG_ 369 TrnIpcDsplyMde_D_Stat 1;
BA_ "U_CD42_MY14_Gas_Tx" SG_ 369 TrnIpcDsplyMde_D_Stat 1;
BA_ "U_P552_MY15_Gas_Tx" SG_ 369 TrnIpcDsplyMde_D_Stat 1;
BA_ "U_S550_MY15_Gas_Tx" SG_ 369 TrnIpcDsplyMde_D_Stat 1;
BA_ "U_C489_MY14_Gas_Tx" SG_ 369 TrnIpcDsplyMde_D_Stat 1;
BA_ "U_U502_MY15_Gas_Tx" SG_ 369 TrnIpcDsplyMde_D_Stat 1;
BA_ "U_UP375_MY15_Gas_Tx" SG_ 369 TrnIpcDsplyMde_D_Stat 1;
BA_ "U_CD43_MY16_Gas_Tx" SG_ 369 TrnIpcDsplyMde_D_Stat 1;
BA_ "U_CD4_MY14_Gas_Tx" SG_ 369 TrnIpcDsplyMde_D_Stat 1;
BA_ "WakeupSignal" SG_ 369 TrnIpcDsplyMde_D_Actl 1;
BA_ "CrossOver_InfoCAN" SG_ 369 TrnIpcDsplyMde_D_Actl 1;
BA_ "U_CD4_MY13_Diesel_Rx" SG_ 369 TrnIpcDsplyMde_D_Actl 1;
BA_ "U_CD4_MY13_Gas_Rx" SG_ 369 TrnIpcDsplyMde_D_Actl 1;
BA_ "U_CD4_MY13_Hev_Rx" SG_ 369 TrnIpcDsplyMde_D_Actl 1;
BA_ "U_CD4_MY13_Phev_Rx" SG_ 369 TrnIpcDsplyMde_D_Actl 1;
BA_ "U_CD42_MY14_Diesel_Rx" SG_ 369 TrnIpcDsplyMde_D_Actl 1;
BA_ "U_CD42_MY14_Gas_Rx" SG_ 369 TrnIpcDsplyMde_D_Actl 1;
BA_ "U_P552_MY15_Gas_Rx" SG_ 369 TrnIpcDsplyMde_D_Actl 1;
BA_ "U_S550_MY15_Gas_Rx" SG_ 369 TrnIpcDsplyMde_D_Actl 1;
BA_ "U_C489_MY14_Gas_Rx" SG_ 369 TrnIpcDsplyMde_D_Actl 1;
BA_ "U_U502_MY15_Gas_Rx" SG_ 369 TrnIpcDsplyMde_D_Actl 1;
BA_ "U_B479_MY15_Gas_Rx" SG_ 369 TrnIpcDsplyMde_D_Actl 1;
BA_ "U_UP375_MY15_Gas_Rx" SG_ 369 TrnIpcDsplyMde_D_Actl 1;
BA_ "U_UP375_MY15_Diesel_Rx" SG_ 369 TrnIpcDsplyMde_D_Actl 1;
BA_ "U_CD4_MY13_Gas_Tx" SG_ 369 TrnIpcDsplyMde_D_Actl 1;
BA_ "U_CD42_MY14_Gas_Tx" SG_ 369 TrnIpcDsplyMde_D_Actl 1;
BA_ "U_P552_MY15_Gas_Tx" SG_ 369 TrnIpcDsplyMde_D_Actl 1;
BA_ "U_S550_MY15_Gas_Tx" SG_ 369 TrnIpcDsplyMde_D_Actl 1;
BA_ "U_C489_MY14_Gas_Tx" SG_ 369 TrnIpcDsplyMde_D_Actl 1;
BA_ "U_U502_MY15_Gas_Tx" SG_ 369 TrnIpcDsplyMde_D_Actl 1;
BA_ "U_UP375_MY15_Gas_Tx" SG_ 369 TrnIpcDsplyMde_D_Actl 1;
BA_ "U_CD43_MY16_Gas_Tx" SG_ 369 TrnIpcDsplyMde_D_Actl 1;
BA_ "U_CD4_MY14_Gas_Tx" SG_ 369 TrnIpcDsplyMde_D_Actl 1;
BA_ "CrossOver_InfoCAN" SG_ 369 TrnIpcDsplyGear_D_Stat 1;
BA_ "U_CD4_MY13_Gas_Tx" SG_ 369 TrnIpcDsplyGear_D_Stat 1;
BA_ "U_CD42_MY14_Gas_Tx" SG_ 369 TrnIpcDsplyGear_D_Stat 1;
BA_ "U_P552_MY15_Gas_Tx" SG_ 369 TrnIpcDsplyGear_D_Stat 1;
BA_ "U_S550_MY15_Gas_Tx" SG_ 369 TrnIpcDsplyGear_D_Stat 1;
BA_ "U_C489_MY14_Gas_Tx" SG_ 369 TrnIpcDsplyGear_D_Stat 1;
BA_ "U_U502_MY15_Gas_Tx" SG_ 369 TrnIpcDsplyGear_D_Stat 1;
BA_ "U_UP375_MY15_Gas_Tx" SG_ 369 TrnIpcDsplyGear_D_Stat 1;
BA_ "U_CD43_MY16_Gas_Tx" SG_ 369 TrnIpcDsplyGear_D_Stat 1;
BA_ "U_CD4_MY14_Gas_Tx" SG_ 369 TrnIpcDsplyGear_D_Stat 1;
BA_ "U_CD42_MY15_Diesel_Rx" SG_ 1466 BCCM_GWOnBoardTester 1;
BA_ "U_CD42_MY15_Gas_Rx" SG_ 1466 BCCM_GWOnBoardTester 1;
BA_ "U_U502_MY16_Gas_Rx" SG_ 1466 BCCM_GWOnBoardTester 1;
BA_ "U_CD4_MY17_Diesel_Rx" SG_ 1466 BCCM_GWOnBoardTester 1;
BA_ "U_CD4_MY17_Gas_Rx" SG_ 1466 BCCM_GWOnBoardTester 1;
BA_ "U_CD4_MY17_Hev_Rx" SG_ 1466 BCCM_GWOnBoardTester 1;
BA_ "U_CD4_MY17_Phev_Rx" SG_ 1466 BCCM_GWOnBoardTester 1;
BA_ "U_V36X_MY16_5_Diesel_Rx" SG_ 1466 BCCM_GWOnBoardTester 1;
BA_ "U_C489_MY17_Gas_Rx" SG_ 1466 BCCM_GWOnBoardTester 1;
BA_ "U_CD42_MY16_Diesel_Rx" SG_ 1466 BCCM_GWOnBoardTester 1;
BA_ "U_CD42_MY16_Gas_Rx" SG_ 1466 BCCM_GWOnBoardTester 1;
BA_ "U_CD43_MY17_Gas_Rx" SG_ 1466 BCCM_GWOnBoardTester 1;
BA_ "U_P552_MY17_Gas_Rx" SG_ 1466 BCCM_GWOnBoardTester 1;
BA_ "U_B515_MCA_MY17_Diesel_Rx" SG_ 1466 BCCM_GWOnBoardTester 1;
BA_ "U_B515_MCA_MY17_Gas_Rx" SG_ 1466 BCCM_GWOnBoardTester 1;
BA_ "U_U55x_MY18_Gas_Rx" SG_ 1466 BCCM_GWOnBoardTester 1;
BA_ "U_CD4_MY13_Phev_Tx" SG_ 1466 BCCM_GWOnBoardTester 1;
BA_ "U_CD4_MY14_Phev_Tx" SG_ 1466 BCCM_GWOnBoardTester 1;
BA_ "GenSigStartValue" SG_ 1466 BCCM_GWOnBoardTester 255;
BA_ "ContentDependant" SG_ 1466 BCCM_GWOnBoardTester 1;
BA_ "U_CD4_MY13_Diesel_Rx" SG_ 1466 BCCM_GWOnBoardTester 1;
BA_ "U_CD4_MY13_Gas_Rx" SG_ 1466 BCCM_GWOnBoardTester 1;
BA_ "U_CD4_MY13_Hev_Rx" SG_ 1466 BCCM_GWOnBoardTester 1;
BA_ "U_CD4_MY13_Phev_Rx" SG_ 1466 BCCM_GWOnBoardTester 1;
BA_ "U_CD42_MY14_Diesel_Rx" SG_ 1466 BCCM_GWOnBoardTester 1;
BA_ "U_CD42_MY14_Gas_Rx" SG_ 1466 BCCM_GWOnBoardTester 1;
BA_ "U_P552_MY15_Gas_Rx" SG_ 1466 BCCM_GWOnBoardTester 1;
BA_ "U_S550_MY15_Gas_Rx" SG_ 1466 BCCM_GWOnBoardTester 1;
BA_ "U_C489_MY14_Gas_Rx" SG_ 1466 BCCM_GWOnBoardTester 1;
BA_ "U_U502_MY15_Gas_Rx" SG_ 1466 BCCM_GWOnBoardTester 1;
BA_ "U_UP375_MY15_Gas_Rx" SG_ 1466 BCCM_GWOnBoardTester 1;
BA_ "U_UP375_MY15_Diesel_Rx" SG_ 1466 BCCM_GWOnBoardTester 1;
BA_ "U_CD43_MY16_Gas_Rx" SG_ 1466 BCCM_GWOnBoardTester 1;
BA_ "U_CD4_MY14_Diesel_Rx" SG_ 1466 BCCM_GWOnBoardTester 1;
BA_ "U_CD4_MY14_Gas_Rx" SG_ 1466 BCCM_GWOnBoardTester 1;
BA_ "U_CD4_MY14_Hev_Rx" SG_ 1466 BCCM_GWOnBoardTester 1;
BA_ "U_CD4_MY14_Phev_Rx" SG_ 1466 BCCM_GWOnBoardTester 1;
BA_ "U_CD42_MY15_Diesel_Rx" SG_ 1466 BCCM_GWNMProxy 1;
BA_ "U_CD42_MY15_Gas_Rx" SG_ 1466 BCCM_GWNMProxy 1;
BA_ "U_U502_MY16_Gas_Rx" SG_ 1466 BCCM_GWNMProxy 1;
BA_ "U_CD4_MY17_Diesel_Rx" SG_ 1466 BCCM_GWNMProxy 1;
BA_ "U_CD4_MY17_Gas_Rx" SG_ 1466 BCCM_GWNMProxy 1;
BA_ "U_CD4_MY17_Hev_Rx" SG_ 1466 BCCM_GWNMProxy 1;
BA_ "U_CD4_MY17_Phev_Rx" SG_ 1466 BCCM_GWNMProxy 1;
BA_ "U_V36X_MY16_5_Diesel_Rx" SG_ 1466 BCCM_GWNMProxy 1;
BA_ "U_C489_MY17_Gas_Rx" SG_ 1466 BCCM_GWNMProxy 1;
BA_ "U_CD42_MY16_Diesel_Rx" SG_ 1466 BCCM_GWNMProxy 1;
BA_ "U_CD42_MY16_Gas_Rx" SG_ 1466 BCCM_GWNMProxy 1;
BA_ "U_CD43_MY17_Gas_Rx" SG_ 1466 BCCM_GWNMProxy 1;
BA_ "U_P552_MY17_Gas_Rx" SG_ 1466 BCCM_GWNMProxy 1;
BA_ "U_B515_MCA_MY17_Diesel_Rx" SG_ 1466 BCCM_GWNMProxy 1;
BA_ "U_B515_MCA_MY17_Gas_Rx" SG_ 1466 BCCM_GWNMProxy 1;
BA_ "U_U55x_MY18_Gas_Rx" SG_ 1466 BCCM_GWNMProxy 1;
BA_ "U_CD4_MY13_Phev_Tx" SG_ 1466 BCCM_GWNMProxy 1;
BA_ "U_CD4_MY14_Phev_Tx" SG_ 1466 BCCM_GWNMProxy 1;
BA_ "GenSigStartValue" SG_ 1466 BCCM_GWNMProxy 255;
BA_ "ContentDependant" SG_ 1466 BCCM_GWNMProxy 1;
BA_ "U_CD4_MY13_Diesel_Rx" SG_ 1466 BCCM_GWNMProxy 1;
BA_ "U_CD4_MY13_Gas_Rx" SG_ 1466 BCCM_GWNMProxy 1;
BA_ "U_CD4_MY13_Hev_Rx" SG_ 1466 BCCM_GWNMProxy 1;
BA_ "U_CD4_MY13_Phev_Rx" SG_ 1466 BCCM_GWNMProxy 1;
BA_ "U_CD42_MY14_Diesel_Rx" SG_ 1466 BCCM_GWNMProxy 1;
BA_ "U_CD42_MY14_Gas_Rx" SG_ 1466 BCCM_GWNMProxy 1;
BA_ "U_P552_MY15_Gas_Rx" SG_ 1466 BCCM_GWNMProxy 1;
BA_ "U_S550_MY15_Gas_Rx" SG_ 1466 BCCM_GWNMProxy 1;
BA_ "U_C489_MY14_Gas_Rx" SG_ 1466 BCCM_GWNMProxy 1;
BA_ "U_U502_MY15_Gas_Rx" SG_ 1466 BCCM_GWNMProxy 1;
BA_ "U_UP375_MY15_Gas_Rx" SG_ 1466 BCCM_GWNMProxy 1;
BA_ "U_UP375_MY15_Diesel_Rx" SG_ 1466 BCCM_GWNMProxy 1;
BA_ "U_CD43_MY16_Gas_Rx" SG_ 1466 BCCM_GWNMProxy 1;
BA_ "U_CD4_MY14_Diesel_Rx" SG_ 1466 BCCM_GWNMProxy 1;
BA_ "U_CD4_MY14_Gas_Rx" SG_ 1466 BCCM_GWNMProxy 1;
BA_ "U_CD4_MY14_Hev_Rx" SG_ 1466 BCCM_GWNMProxy 1;
BA_ "U_CD4_MY14_Phev_Rx" SG_ 1466 BCCM_GWNMProxy 1;
BA_ "U_CD42_MY15_Diesel_Rx" SG_ 1466 BCCM_AutoSarNMReserved4 1;
BA_ "U_CD42_MY15_Gas_Rx" SG_ 1466 BCCM_AutoSarNMReserved4 1;
BA_ "U_U502_MY16_Gas_Rx" SG_ 1466 BCCM_AutoSarNMReserved4 1;
BA_ "U_CD4_MY17_Diesel_Rx" SG_ 1466 BCCM_AutoSarNMReserved4 1;
BA_ "U_CD4_MY17_Gas_Rx" SG_ 1466 BCCM_AutoSarNMReserved4 1;
BA_ "U_CD4_MY17_Hev_Rx" SG_ 1466 BCCM_AutoSarNMReserved4 1;
BA_ "U_CD4_MY17_Phev_Rx" SG_ 1466 BCCM_AutoSarNMReserved4 1;
BA_ "U_V36X_MY16_5_Diesel_Rx" SG_ 1466 BCCM_AutoSarNMReserved4 1;
BA_ "U_C489_MY17_Gas_Rx" SG_ 1466 BCCM_AutoSarNMReserved4 1;
BA_ "U_CD42_MY16_Diesel_Rx" SG_ 1466 BCCM_AutoSarNMReserved4 1;
BA_ "U_CD42_MY16_Gas_Rx" SG_ 1466 BCCM_AutoSarNMReserved4 1;
BA_ "U_CD43_MY17_Gas_Rx" SG_ 1466 BCCM_AutoSarNMReserved4 1;
BA_ "U_P552_MY17_Gas_Rx" SG_ 1466 BCCM_AutoSarNMReserved4 1;
BA_ "U_B515_MCA_MY17_Diesel_Rx" SG_ 1466 BCCM_AutoSarNMReserved4 1;
BA_ "U_B515_MCA_MY17_Gas_Rx" SG_ 1466 BCCM_AutoSarNMReserved4 1;
BA_ "U_U55x_MY18_Gas_Rx" SG_ 1466 BCCM_AutoSarNMReserved4 1;
BA_ "U_CD4_MY13_Phev_Tx" SG_ 1466 BCCM_AutoSarNMReserved4 1;
BA_ "U_CD4_MY14_Phev_Tx" SG_ 1466 BCCM_AutoSarNMReserved4 1;
BA_ "GenSigStartValue" SG_ 1466 BCCM_AutoSarNMReserved4 255;
BA_ "ContentDependant" SG_ 1466 BCCM_AutoSarNMReserved4 1;
BA_ "U_CD4_MY13_Diesel_Rx" SG_ 1466 BCCM_AutoSarNMReserved4 1;
BA_ "U_CD4_MY13_Gas_Rx" SG_ 1466 BCCM_AutoSarNMReserved4 1;
BA_ "U_CD4_MY13_Hev_Rx" SG_ 1466 BCCM_AutoSarNMReserved4 1;
BA_ "U_CD4_MY13_Phev_Rx" SG_ 1466 BCCM_AutoSarNMReserved4 1;
BA_ "U_CD42_MY14_Diesel_Rx" SG_ 1466 BCCM_AutoSarNMReserved4 1;
BA_ "U_CD42_MY14_Gas_Rx" SG_ 1466 BCCM_AutoSarNMReserved4 1;
BA_ "U_P552_MY15_Gas_Rx" SG_ 1466 BCCM_AutoSarNMReserved4 1;
BA_ "U_S550_MY15_Gas_Rx" SG_ 1466 BCCM_AutoSarNMReserved4 1;
BA_ "U_C489_MY14_Gas_Rx" SG_ 1466 BCCM_AutoSarNMReserved4 1;
BA_ "U_U502_MY15_Gas_Rx" SG_ 1466 BCCM_AutoSarNMReserved4 1;
BA_ "U_UP375_MY15_Gas_Rx" SG_ 1466 BCCM_AutoSarNMReserved4 1;
BA_ "U_UP375_MY15_Diesel_Rx" SG_ 1466 BCCM_AutoSarNMReserved4 1;
BA_ "U_CD43_MY16_Gas_Rx" SG_ 1466 BCCM_AutoSarNMReserved4 1;
BA_ "U_CD4_MY14_Diesel_Rx" SG_ 1466 BCCM_AutoSarNMReserved4 1;
BA_ "U_CD4_MY14_Gas_Rx" SG_ 1466 BCCM_AutoSarNMReserved4 1;
BA_ "U_CD4_MY14_Hev_Rx" SG_ 1466 BCCM_AutoSarNMReserved4 1;
BA_ "U_CD4_MY14_Phev_Rx" SG_ 1466 BCCM_AutoSarNMReserved4 1;
BA_ "U_CD42_MY15_Diesel_Rx" SG_ 1466 BCCM_AutoSarNMReserved3 1;
BA_ "U_CD42_MY15_Gas_Rx" SG_ 1466 BCCM_AutoSarNMReserved3 1;
BA_ "U_U502_MY16_Gas_Rx" SG_ 1466 BCCM_AutoSarNMReserved3 1;
BA_ "U_CD4_MY17_Diesel_Rx" SG_ 1466 BCCM_AutoSarNMReserved3 1;
BA_ "U_CD4_MY17_Gas_Rx" SG_ 1466 BCCM_AutoSarNMReserved3 1;
BA_ "U_CD4_MY17_Hev_Rx" SG_ 1466 BCCM_AutoSarNMReserved3 1;
BA_ "U_CD4_MY17_Phev_Rx" SG_ 1466 BCCM_AutoSarNMReserved3 1;
BA_ "U_V36X_MY16_5_Diesel_Rx" SG_ 1466 BCCM_AutoSarNMReserved3 1;
BA_ "U_C489_MY17_Gas_Rx" SG_ 1466 BCCM_AutoSarNMReserved3 1;
BA_ "U_CD42_MY16_Diesel_Rx" SG_ 1466 BCCM_AutoSarNMReserved3 1;
BA_ "U_CD42_MY16_Gas_Rx" SG_ 1466 BCCM_AutoSarNMReserved3 1;
BA_ "U_CD43_MY17_Gas_Rx" SG_ 1466 BCCM_AutoSarNMReserved3 1;
BA_ "U_P552_MY17_Gas_Rx" SG_ 1466 BCCM_AutoSarNMReserved3 1;
BA_ "U_B515_MCA_MY17_Diesel_Rx" SG_ 1466 BCCM_AutoSarNMReserved3 1;
BA_ "U_B515_MCA_MY17_Gas_Rx" SG_ 1466 BCCM_AutoSarNMReserved3 1;
BA_ "U_U55x_MY18_Gas_Rx" SG_ 1466 BCCM_AutoSarNMReserved3 1;
BA_ "U_CD4_MY13_Phev_Tx" SG_ 1466 BCCM_AutoSarNMReserved3 1;
BA_ "U_CD4_MY14_Phev_Tx" SG_ 1466 BCCM_AutoSarNMReserved3 1;
BA_ "GenSigStartValue" SG_ 1466 BCCM_AutoSarNMReserved3 255;
BA_ "ContentDependant" SG_ 1466 BCCM_AutoSarNMReserved3 1;
BA_ "U_CD4_MY13_Phev_Rx" SG_ 1466 BCCM_AutoSarNMReserved3 1;
BA_ "U_CD42_MY14_Diesel_Rx" SG_ 1466 BCCM_AutoSarNMReserved3 1;
BA_ "U_CD42_MY14_Gas_Rx" SG_ 1466 BCCM_AutoSarNMReserved3 1;
BA_ "U_P552_MY15_Gas_Rx" SG_ 1466 BCCM_AutoSarNMReserved3 1;
BA_ "U_S550_MY15_Gas_Rx" SG_ 1466 BCCM_AutoSarNMReserved3 1;
BA_ "U_C489_MY14_Gas_Rx" SG_ 1466 BCCM_AutoSarNMReserved3 1;
BA_ "U_U502_MY15_Gas_Rx" SG_ 1466 BCCM_AutoSarNMReserved3 1;
BA_ "U_UP375_MY15_Gas_Rx" SG_ 1466 BCCM_AutoSarNMReserved3 1;
BA_ "U_UP375_MY15_Diesel_Rx" SG_ 1466 BCCM_AutoSarNMReserved3 1;
BA_ "U_CD43_MY16_Gas_Rx" SG_ 1466 BCCM_AutoSarNMReserved3 1;
BA_ "U_CD4_MY14_Diesel_Rx" SG_ 1466 BCCM_AutoSarNMReserved3 1;
BA_ "U_CD4_MY14_Gas_Rx" SG_ 1466 BCCM_AutoSarNMReserved3 1;
BA_ "U_CD4_MY14_Hev_Rx" SG_ 1466 BCCM_AutoSarNMReserved3 1;
BA_ "U_CD4_MY14_Phev_Rx" SG_ 1466 BCCM_AutoSarNMReserved3 1;
BA_ "U_CD42_MY15_Diesel_Rx" SG_ 1466 BCCM_AutoSarNMReserved2 1;
BA_ "U_CD42_MY15_Gas_Rx" SG_ 1466 BCCM_AutoSarNMReserved2 1;
BA_ "U_U502_MY16_Gas_Rx" SG_ 1466 BCCM_AutoSarNMReserved2 1;
BA_ "U_CD4_MY17_Diesel_Rx" SG_ 1466 BCCM_AutoSarNMReserved2 1;
BA_ "U_CD4_MY17_Gas_Rx" SG_ 1466 BCCM_AutoSarNMReserved2 1;
BA_ "U_CD4_MY17_Hev_Rx" SG_ 1466 BCCM_AutoSarNMReserved2 1;
BA_ "U_CD4_MY17_Phev_Rx" SG_ 1466 BCCM_AutoSarNMReserved2 1;
BA_ "U_V36X_MY16_5_Diesel_Rx" SG_ 1466 BCCM_AutoSarNMReserved2 1;
BA_ "U_C489_MY17_Gas_Rx" SG_ 1466 BCCM_AutoSarNMReserved2 1;
BA_ "U_CD42_MY16_Diesel_Rx" SG_ 1466 BCCM_AutoSarNMReserved2 1;
BA_ "U_CD42_MY16_Gas_Rx" SG_ 1466 BCCM_AutoSarNMReserved2 1;
BA_ "U_CD43_MY17_Gas_Rx" SG_ 1466 BCCM_AutoSarNMReserved2 1;
BA_ "U_P552_MY17_Gas_Rx" SG_ 1466 BCCM_AutoSarNMReserved2 1;
BA_ "U_B515_MCA_MY17_Diesel_Rx" SG_ 1466 BCCM_AutoSarNMReserved2 1;
BA_ "U_B515_MCA_MY17_Gas_Rx" SG_ 1466 BCCM_AutoSarNMReserved2 1;
BA_ "U_U55x_MY18_Gas_Rx" SG_ 1466 BCCM_AutoSarNMReserved2 1;
BA_ "U_CD4_MY13_Phev_Tx" SG_ 1466 BCCM_AutoSarNMReserved2 1;
BA_ "U_CD4_MY14_Phev_Tx" SG_ 1466 BCCM_AutoSarNMReserved2 1;
BA_ "GenSigStartValue" SG_ 1466 BCCM_AutoSarNMReserved2 255;
BA_ "ContentDependant" SG_ 1466 BCCM_AutoSarNMReserved2 1;
BA_ "U_CD4_MY13_Diesel_Rx" SG_ 1466 BCCM_AutoSarNMReserved2 1;
BA_ "U_CD4_MY13_Gas_Rx" SG_ 1466 BCCM_AutoSarNMReserved2 1;
BA_ "U_CD4_MY13_Hev_Rx" SG_ 1466 BCCM_AutoSarNMReserved2 1;
BA_ "U_CD4_MY13_Phev_Rx" SG_ 1466 BCCM_AutoSarNMReserved2 1;
BA_ "U_CD42_MY14_Diesel_Rx" SG_ 1466 BCCM_AutoSarNMReserved2 1;
BA_ "U_CD42_MY14_Gas_Rx" SG_ 1466 BCCM_AutoSarNMReserved2 1;
BA_ "U_P552_MY15_Gas_Rx" SG_ 1466 BCCM_AutoSarNMReserved2 1;
BA_ "U_S550_MY15_Gas_Rx" SG_ 1466 BCCM_AutoSarNMReserved2 1;
BA_ "U_C489_MY14_Gas_Rx" SG_ 1466 BCCM_AutoSarNMReserved2 1;
BA_ "U_U502_MY15_Gas_Rx" SG_ 1466 BCCM_AutoSarNMReserved2 1;
BA_ "U_UP375_MY15_Gas_Rx" SG_ 1466 BCCM_AutoSarNMReserved2 1;
BA_ "U_UP375_MY15_Diesel_Rx" SG_ 1466 BCCM_AutoSarNMReserved2 1;
BA_ "U_CD43_MY16_Gas_Rx" SG_ 1466 BCCM_AutoSarNMReserved2 1;
BA_ "U_CD4_MY14_Diesel_Rx" SG_ 1466 BCCM_AutoSarNMReserved2 1;
BA_ "U_CD4_MY14_Gas_Rx" SG_ 1466 BCCM_AutoSarNMReserved2 1;
BA_ "U_CD4_MY14_Hev_Rx" SG_ 1466 BCCM_AutoSarNMReserved2 1;
BA_ "U_CD4_MY14_Phev_Rx" SG_ 1466 BCCM_AutoSarNMReserved2 1;
BA_ "U_CD42_MY15_Diesel_Rx" SG_ 1466 BCCM_AutoSarNMReserved1 1;
BA_ "U_CD42_MY15_Gas_Rx" SG_ 1466 BCCM_AutoSarNMReserved1 1;
BA_ "U_U502_MY16_Gas_Rx" SG_ 1466 BCCM_AutoSarNMReserved1 1;
BA_ "U_CD4_MY17_Diesel_Rx" SG_ 1466 BCCM_AutoSarNMReserved1 1;
BA_ "U_CD4_MY17_Gas_Rx" SG_ 1466 BCCM_AutoSarNMReserved1 1;
BA_ "U_CD4_MY17_Hev_Rx" SG_ 1466 BCCM_AutoSarNMReserved1 1;
BA_ "U_CD4_MY17_Phev_Rx" SG_ 1466 BCCM_AutoSarNMReserved1 1;
BA_ "U_V36X_MY16_5_Diesel_Rx" SG_ 1466 BCCM_AutoSarNMReserved1 1;
BA_ "U_C489_MY17_Gas_Rx" SG_ 1466 BCCM_AutoSarNMReserved1 1;
BA_ "U_CD42_MY16_Diesel_Rx" SG_ 1466 BCCM_AutoSarNMReserved1 1;
BA_ "U_CD42_MY16_Gas_Rx" SG_ 1466 BCCM_AutoSarNMReserved1 1;
BA_ "U_CD43_MY17_Gas_Rx" SG_ 1466 BCCM_AutoSarNMReserved1 1;
BA_ "U_P552_MY17_Gas_Rx" SG_ 1466 BCCM_AutoSarNMReserved1 1;
BA_ "U_B515_MCA_MY17_Diesel_Rx" SG_ 1466 BCCM_AutoSarNMReserved1 1;
BA_ "U_B515_MCA_MY17_Gas_Rx" SG_ 1466 BCCM_AutoSarNMReserved1 1;
BA_ "U_U55x_MY18_Gas_Rx" SG_ 1466 BCCM_AutoSarNMReserved1 1;
BA_ "U_CD4_MY13_Phev_Tx" SG_ 1466 BCCM_AutoSarNMReserved1 1;
BA_ "U_CD4_MY14_Phev_Tx" SG_ 1466 BCCM_AutoSarNMReserved1 1;
BA_ "GenSigStartValue" SG_ 1466 BCCM_AutoSarNMReserved1 255;
BA_ "ContentDependant" SG_ 1466 BCCM_AutoSarNMReserved1 1;
BA_ "U_CD4_MY13_Diesel_Rx" SG_ 1466 BCCM_AutoSarNMReserved1 1;
BA_ "U_CD4_MY13_Gas_Rx" SG_ 1466 BCCM_AutoSarNMReserved1 1;
BA_ "U_CD4_MY13_Hev_Rx" SG_ 1466 BCCM_AutoSarNMReserved1 1;
BA_ "U_CD4_MY13_Phev_Rx" SG_ 1466 BCCM_AutoSarNMReserved1 1;
BA_ "U_CD42_MY14_Diesel_Rx" SG_ 1466 BCCM_AutoSarNMReserved1 1;
BA_ "U_CD42_MY14_Gas_Rx" SG_ 1466 BCCM_AutoSarNMReserved1 1;
BA_ "U_P552_MY15_Gas_Rx" SG_ 1466 BCCM_AutoSarNMReserved1 1;
BA_ "U_S550_MY15_Gas_Rx" SG_ 1466 BCCM_AutoSarNMReserved1 1;
BA_ "U_C489_MY14_Gas_Rx" SG_ 1466 BCCM_AutoSarNMReserved1 1;
BA_ "U_U502_MY15_Gas_Rx" SG_ 1466 BCCM_AutoSarNMReserved1 1;
BA_ "U_UP375_MY15_Gas_Rx" SG_ 1466 BCCM_AutoSarNMReserved1 1;
BA_ "U_UP375_MY15_Diesel_Rx" SG_ 1466 BCCM_AutoSarNMReserved1 1;
BA_ "U_CD43_MY16_Gas_Rx" SG_ 1466 BCCM_AutoSarNMReserved1 1;
BA_ "U_CD4_MY14_Diesel_Rx" SG_ 1466 BCCM_AutoSarNMReserved1 1;
BA_ "U_CD4_MY14_Gas_Rx" SG_ 1466 BCCM_AutoSarNMReserved1 1;
BA_ "U_CD4_MY14_Hev_Rx" SG_ 1466 BCCM_AutoSarNMReserved1 1;
BA_ "U_CD4_MY14_Phev_Rx" SG_ 1466 BCCM_AutoSarNMReserved1 1;
BA_ "U_CD42_MY15_Diesel_Rx" SG_ 1466 BCCM_AutoSarNMNodeId 1;
BA_ "U_CD42_MY15_Gas_Rx" SG_ 1466 BCCM_AutoSarNMNodeId 1;
BA_ "U_U502_MY16_Gas_Rx" SG_ 1466 BCCM_AutoSarNMNodeId 1;
BA_ "U_CD4_MY17_Diesel_Rx" SG_ 1466 BCCM_AutoSarNMNodeId 1;
BA_ "U_CD4_MY17_Gas_Rx" SG_ 1466 BCCM_AutoSarNMNodeId 1;
BA_ "U_CD4_MY17_Hev_Rx" SG_ 1466 BCCM_AutoSarNMNodeId 1;
BA_ "U_CD4_MY17_Phev_Rx" SG_ 1466 BCCM_AutoSarNMNodeId 1;
BA_ "U_V36X_MY16_5_Diesel_Rx" SG_ 1466 BCCM_AutoSarNMNodeId 1;
BA_ "U_C489_MY17_Gas_Rx" SG_ 1466 BCCM_AutoSarNMNodeId 1;
BA_ "U_CD42_MY16_Diesel_Rx" SG_ 1466 BCCM_AutoSarNMNodeId 1;
BA_ "U_CD42_MY16_Gas_Rx" SG_ 1466 BCCM_AutoSarNMNodeId 1;
BA_ "U_CD43_MY17_Gas_Rx" SG_ 1466 BCCM_AutoSarNMNodeId 1;
BA_ "U_P552_MY17_Gas_Rx" SG_ 1466 BCCM_AutoSarNMNodeId 1;
BA_ "U_B515_MCA_MY17_Diesel_Rx" SG_ 1466 BCCM_AutoSarNMNodeId 1;
BA_ "U_B515_MCA_MY17_Gas_Rx" SG_ 1466 BCCM_AutoSarNMNodeId 1;
BA_ "U_U55x_MY18_Gas_Rx" SG_ 1466 BCCM_AutoSarNMNodeId 1;
BA_ "U_CD4_MY13_Phev_Tx" SG_ 1466 BCCM_AutoSarNMNodeId 1;
BA_ "U_CD4_MY14_Phev_Tx" SG_ 1466 BCCM_AutoSarNMNodeId 1;
BA_ "ContentDependant" SG_ 1466 BCCM_AutoSarNMNodeId 1;
BA_ "U_CD4_MY13_Diesel_Rx" SG_ 1466 BCCM_AutoSarNMNodeId 1;
BA_ "U_CD4_MY13_Gas_Rx" SG_ 1466 BCCM_AutoSarNMNodeId 1;
BA_ "U_CD4_MY13_Hev_Rx" SG_ 1466 BCCM_AutoSarNMNodeId 1;
BA_ "U_CD4_MY13_Phev_Rx" SG_ 1466 BCCM_AutoSarNMNodeId 1;
BA_ "U_CD42_MY14_Diesel_Rx" SG_ 1466 BCCM_AutoSarNMNodeId 1;
BA_ "U_CD42_MY14_Gas_Rx" SG_ 1466 BCCM_AutoSarNMNodeId 1;
BA_ "U_P552_MY15_Gas_Rx" SG_ 1466 BCCM_AutoSarNMNodeId 1;
BA_ "U_S550_MY15_Gas_Rx" SG_ 1466 BCCM_AutoSarNMNodeId 1;
BA_ "U_C489_MY14_Gas_Rx" SG_ 1466 BCCM_AutoSarNMNodeId 1;
BA_ "U_U502_MY15_Gas_Rx" SG_ 1466 BCCM_AutoSarNMNodeId 1;
BA_ "U_UP375_MY15_Gas_Rx" SG_ 1466 BCCM_AutoSarNMNodeId 1;
BA_ "U_UP375_MY15_Diesel_Rx" SG_ 1466 BCCM_AutoSarNMNodeId 1;
BA_ "U_CD43_MY16_Gas_Rx" SG_ 1466 BCCM_AutoSarNMNodeId 1;
BA_ "U_CD4_MY14_Diesel_Rx" SG_ 1466 BCCM_AutoSarNMNodeId 1;
BA_ "U_CD4_MY14_Gas_Rx" SG_ 1466 BCCM_AutoSarNMNodeId 1;
BA_ "U_CD4_MY14_Hev_Rx" SG_ 1466 BCCM_AutoSarNMNodeId 1;
BA_ "U_CD4_MY14_Phev_Rx" SG_ 1466 BCCM_AutoSarNMNodeId 1;
BA_ "U_CD42_MY15_Diesel_Rx" SG_ 1466 BCCM_AutoSarNMControl 1;
BA_ "U_CD42_MY15_Gas_Rx" SG_ 1466 BCCM_AutoSarNMControl 1;
BA_ "U_U502_MY16_Gas_Rx" SG_ 1466 BCCM_AutoSarNMControl 1;
BA_ "U_CD4_MY17_Diesel_Rx" SG_ 1466 BCCM_AutoSarNMControl 1;
BA_ "U_CD4_MY17_Gas_Rx" SG_ 1466 BCCM_AutoSarNMControl 1;
BA_ "U_CD4_MY17_Hev_Rx" SG_ 1466 BCCM_AutoSarNMControl 1;
BA_ "U_CD4_MY17_Phev_Rx" SG_ 1466 BCCM_AutoSarNMControl 1;
BA_ "U_V36X_MY16_5_Diesel_Rx" SG_ 1466 BCCM_AutoSarNMControl 1;
BA_ "U_C489_MY17_Gas_Rx" SG_ 1466 BCCM_AutoSarNMControl 1;
BA_ "U_CD42_MY16_Diesel_Rx" SG_ 1466 BCCM_AutoSarNMControl 1;
BA_ "U_CD42_MY16_Gas_Rx" SG_ 1466 BCCM_AutoSarNMControl 1;
BA_ "U_CD43_MY17_Gas_Rx" SG_ 1466 BCCM_AutoSarNMControl 1;
BA_ "U_P552_MY17_Gas_Rx" SG_ 1466 BCCM_AutoSarNMControl 1;
BA_ "U_B515_MCA_MY17_Diesel_Rx" SG_ 1466 BCCM_AutoSarNMControl 1;
BA_ "U_B515_MCA_MY17_Gas_Rx" SG_ 1466 BCCM_AutoSarNMControl 1;
BA_ "U_U55x_MY18_Gas_Rx" SG_ 1466 BCCM_AutoSarNMControl 1;
BA_ "U_CD4_MY13_Phev_Tx" SG_ 1466 BCCM_AutoSarNMControl 1;
BA_ "U_CD4_MY14_Phev_Tx" SG_ 1466 BCCM_AutoSarNMControl 1;
BA_ "ContentDependant" SG_ 1466 BCCM_AutoSarNMControl 1;
BA_ "U_CD4_MY13_Diesel_Rx" SG_ 1466 BCCM_AutoSarNMControl 1;
BA_ "U_CD4_MY13_Gas_Rx" SG_ 1466 BCCM_AutoSarNMControl 1;
BA_ "U_CD4_MY13_Hev_Rx" SG_ 1466 BCCM_AutoSarNMControl 1;
BA_ "U_CD4_MY13_Phev_Rx" SG_ 1466 BCCM_AutoSarNMControl 1;
BA_ "U_CD42_MY14_Diesel_Rx" SG_ 1466 BCCM_AutoSarNMControl 1;
BA_ "U_CD42_MY14_Gas_Rx" SG_ 1466 BCCM_AutoSarNMControl 1;
BA_ "U_P552_MY15_Gas_Rx" SG_ 1466 BCCM_AutoSarNMControl 1;
BA_ "U_S550_MY15_Gas_Rx" SG_ 1466 BCCM_AutoSarNMControl 1;
BA_ "U_C489_MY14_Gas_Rx" SG_ 1466 BCCM_AutoSarNMControl 1;
BA_ "U_U502_MY15_Gas_Rx" SG_ 1466 BCCM_AutoSarNMControl 1;
BA_ "U_UP375_MY15_Gas_Rx" SG_ 1466 BCCM_AutoSarNMControl 1;
BA_ "U_UP375_MY15_Diesel_Rx" SG_ 1466 BCCM_AutoSarNMControl 1;
BA_ "U_CD43_MY16_Gas_Rx" SG_ 1466 BCCM_AutoSarNMControl 1;
BA_ "U_CD4_MY14_Diesel_Rx" SG_ 1466 BCCM_AutoSarNMControl 1;
BA_ "U_CD4_MY14_Gas_Rx" SG_ 1466 BCCM_AutoSarNMControl 1;
BA_ "U_CD4_MY14_Hev_Rx" SG_ 1466 BCCM_AutoSarNMControl 1;
BA_ "U_CD4_MY14_Phev_Rx" SG_ 1466 BCCM_AutoSarNMControl 1;
BA_ "CrossOver_InfoCAN" SG_ 76 SecondRowBucklePsngr 1;
BA_ "GenSigStartValue" SG_ 76 SecondRowBucklePsngr 3;
BA_ "CrossOver_InfoCAN" SG_ 76 SecondRowBuckleDriver 1;
BA_ "GenSigStartValue" SG_ 76 SecondRowBuckleDriver 3;
BA_ "CrossOver_InfoCAN" SG_ 76 FirstRowBuckleDriver 1;
BA_ "GenSigStartValue" SG_ 76 FirstRowBuckleDriver 3;
BA_ "U_CD4_MY13_Diesel_Rx" SG_ 76 FirstRowBuckleDriver 1;
BA_ "U_CD4_MY13_Gas_Rx" SG_ 76 FirstRowBuckleDriver 1;
BA_ "U_CD4_MY13_Hev_Rx" SG_ 76 FirstRowBuckleDriver 1;
BA_ "U_CD4_MY13_Phev_Rx" SG_ 76 FirstRowBuckleDriver 1;
BA_ "U_CD42_MY14_Diesel_Rx" SG_ 76 FirstRowBuckleDriver 1;
BA_ "U_CD42_MY14_Gas_Rx" SG_ 76 FirstRowBuckleDriver 1;
BA_ "U_P552_MY15_Gas_Rx" SG_ 76 FirstRowBuckleDriver 1;
BA_ "U_S550_MY15_Gas_Rx" SG_ 76 FirstRowBuckleDriver 1;
BA_ "U_C489_MY14_Gas_Rx" SG_ 76 FirstRowBuckleDriver 1;
BA_ "U_U502_MY15_Gas_Rx" SG_ 76 FirstRowBuckleDriver 1;
BA_ "U_CD43_MY16_Gas_Rx" SG_ 76 FirstRowBuckleDriver 1;
BA_ "U_CD4_MY14_Gas_Rx" SG_ 76 FirstRowBuckleDriver 1;
BA_ "U_UP375_MY15_Gas_Rx" SG_ 76 FirstRowBuckleDriver 1;
BA_ "U_UP375_MY15_Diesel_Rx" SG_ 76 FirstRowBuckleDriver 1;
BA_ "U_CD4_MY14_Diesel_Rx" SG_ 76 FirstRowBuckleDriver 1;
BA_ "U_CD4_MY14_Hev_Rx" SG_ 76 FirstRowBuckleDriver 1;
BA_ "U_CD4_MY14_Phev_Rx" SG_ 76 FirstRowBuckleDriver 1;
BA_ "CrossOver_InfoCAN" SG_ 76 RILReq 1;
BA_ "CrossOver_InfoCAN" SG_ 76 FirstRowBucklePsngr 1;
BA_ "GenSigStartValue" SG_ 76 FirstRowBucklePsngr 3;
BA_ "WakeupSignal" SG_ 76 RstrnImpactEvntStatus 1;
BA_ "CrossOver_InfoCAN" SG_ 76 RstrnImpactEvntStatus 1;
BA_ "U_CD4_MY13_Diesel_Rx" SG_ 76 RstrnImpactEvntStatus 1;
BA_ "U_CD4_MY13_Gas_Rx" SG_ 76 RstrnImpactEvntStatus 1;
BA_ "U_CD4_MY13_Hev_Rx" SG_ 76 RstrnImpactEvntStatus 1;
BA_ "U_CD4_MY13_Phev_Rx" SG_ 76 RstrnImpactEvntStatus 1;
BA_ "U_CD42_MY14_Diesel_Rx" SG_ 76 RstrnImpactEvntStatus 1;
BA_ "U_CD42_MY14_Gas_Rx" SG_ 76 RstrnImpactEvntStatus 1;
BA_ "U_P552_MY15_Gas_Rx" SG_ 76 RstrnImpactEvntStatus 1;
BA_ "U_S550_MY15_Gas_Rx" SG_ 76 RstrnImpactEvntStatus 1;
BA_ "U_C489_MY14_Gas_Rx" SG_ 76 RstrnImpactEvntStatus 1;
BA_ "U_U502_MY15_Gas_Rx" SG_ 76 RstrnImpactEvntStatus 1;
BA_ "U_UP375_MY15_Gas_Rx" SG_ 76 RstrnImpactEvntStatus 1;
BA_ "U_CD43_MY16_Gas_Rx" SG_ 76 RstrnImpactEvntStatus 1;
BA_ "U_CD4_MY14_Gas_Rx" SG_ 76 RstrnImpactEvntStatus 1;
BA_ "U_UP375_MY15_Diesel_Rx" SG_ 76 RstrnImpactEvntStatus 1;
BA_ "U_CD4_MY14_Diesel_Rx" SG_ 76 RstrnImpactEvntStatus 1;
BA_ "U_CD4_MY14_Hev_Rx" SG_ 76 RstrnImpactEvntStatus 1;
BA_ "U_CD4_MY14_Phev_Rx" SG_ 76 RstrnImpactEvntStatus 1;
BA_ "CrossOver_InfoCAN" SG_ 76 PsngrFrntDetct_D_Actl 1;
BA_ "GenSigStartValue" SG_ 76 PsngrFrntDetct_D_Actl 3;
BA_ "CrossOver_InfoCAN" SG_ 76 EDRTriggerEvntSync 1;
BA_ "CrossOver_InfoCAN" SG_ 76 PassRstrnInd_Req 1;
BA_ "GenSigStartValue" SG_ 76 PassRstrnInd_Req 3;
BA_ "GenSigSendType" SG_ 2008 TesterPhysicalResAPIM 3;
BA_ "U_CD4_MY13_Diesel_Rx" SG_ 2008 TesterPhysicalResAPIM 1;
BA_ "U_CD4_MY13_Gas_Rx" SG_ 2008 TesterPhysicalResAPIM 1;
BA_ "U_CD4_MY13_Hev_Rx" SG_ 2008 TesterPhysicalResAPIM 1;
BA_ "U_CD4_MY13_Phev_Rx" SG_ 2008 TesterPhysicalResAPIM 1;
BA_ "U_CD42_MY14_Diesel_Rx" SG_ 2008 TesterPhysicalResAPIM 1;
BA_ "U_CD42_MY14_Gas_Rx" SG_ 2008 TesterPhysicalResAPIM 1;
BA_ "U_P552_MY15_Gas_Rx" SG_ 2008 TesterPhysicalResAPIM 1;
BA_ "U_S550_MY15_Gas_Rx" SG_ 2008 TesterPhysicalResAPIM 1;
BA_ "U_C489_MY14_Gas_Rx" SG_ 2008 TesterPhysicalResAPIM 1;
BA_ "U_CD4_MY13_Diesel_Tx" SG_ 2008 TesterPhysicalResAPIM 1;
BA_ "U_CD4_MY13_Gas_Tx" SG_ 2008 TesterPhysicalResAPIM 1;
BA_ "U_CD4_MY13_Hev_Tx" SG_ 2008 TesterPhysicalResAPIM 1;
BA_ "U_CD4_MY13_Phev_Tx" SG_ 2008 TesterPhysicalResAPIM 1;
BA_ "U_CD42_MY14_Diesel_Tx" SG_ 2008 TesterPhysicalResAPIM 1;
BA_ "U_CD42_MY14_Gas_Tx" SG_ 2008 TesterPhysicalResAPIM 1;
BA_ "U_P552_MY15_Gas_Tx" SG_ 2008 TesterPhysicalResAPIM 1;
BA_ "U_S550_MY15_Gas_Tx" SG_ 2008 TesterPhysicalResAPIM 1;
BA_ "U_C489_MY14_Gas_Tx" SG_ 2008 TesterPhysicalResAPIM 1;
BA_ "U_U502_MY15_Gas_Tx" SG_ 2008 TesterPhysicalResAPIM 1;
BA_ "U_CD43_MY16_Gas_Tx" SG_ 2008 TesterPhysicalResAPIM 1;
BA_ "U_CD4_MY14_Diesel_Tx" SG_ 2008 TesterPhysicalResAPIM 1;
BA_ "U_CD4_MY14_Gas_Tx" SG_ 2008 TesterPhysicalResAPIM 1;
BA_ "U_CD4_MY14_Hev_Tx" SG_ 2008 TesterPhysicalResAPIM 1;
BA_ "U_CD4_MY14_Phev_Tx" SG_ 2008 TesterPhysicalResAPIM 1;
BA_ "GenSigStartValue" SG_ 146 VehVertAActl_D_Qf 1;
BA_ "GenSigStartValue" SG_ 146 VehVert2_A_Actl 8190;
BA_ "GenSigStartValue" SG_ 146 VehLongAActl_D_Qf 1;
BA_ "U_CD4_MY13_Diesel_Rx" SG_ 146 VehLongAActl_D_Qf 1;
BA_ "U_CD4_MY13_Gas_Rx" SG_ 146 VehLongAActl_D_Qf 1;
BA_ "U_CD4_MY13_Hev_Rx" SG_ 146 VehLongAActl_D_Qf 1;
BA_ "U_CD4_MY13_Phev_Rx" SG_ 146 VehLongAActl_D_Qf 1;
BA_ "U_CD42_MY14_Diesel_Rx" SG_ 146 VehLongAActl_D_Qf 1;
BA_ "U_CD42_MY14_Gas_Rx" SG_ 146 VehLongAActl_D_Qf 1;
BA_ "U_P552_MY15_Gas_Rx" SG_ 146 VehLongAActl_D_Qf 1;
BA_ "U_C489_MY14_Gas_Rx" SG_ 146 VehLongAActl_D_Qf 1;
BA_ "U_U502_MY15_Gas_Rx" SG_ 146 VehLongAActl_D_Qf 1;
BA_ "U_UP375_MY15_Gas_Rx" SG_ 146 VehLongAActl_D_Qf 1;
BA_ "U_UP375_MY15_Diesel_Rx" SG_ 146 VehLongAActl_D_Qf 1;
BA_ "U_CD43_MY16_Gas_Rx" SG_ 146 VehLongAActl_D_Qf 1;
BA_ "U_CD4_MY14_Diesel_Rx" SG_ 146 VehLongAActl_D_Qf 1;
BA_ "U_CD4_MY14_Gas_Rx" SG_ 146 VehLongAActl_D_Qf 1;
BA_ "U_CD4_MY14_Hev_Rx" SG_ 146 VehLongAActl_D_Qf 1;
BA_ "U_CD4_MY14_Phev_Rx" SG_ 146 VehLongAActl_D_Qf 1;
BA_ "GenSigStartValue" SG_ 146 VehLatAActl_D_Qf 1;
BA_ "GenSigStartValue" SG_ 146 VehLat2_A_Actl 8190;
BA_ "GenSigSendType" SG_ 146 VehLat2_A_Actl 1;
BA_ "GenSigStartValue" SG_ 146 VehLong2_A_Actl 8190;
BA_ "U_CD42_MY14_Diesel_Rx" SG_ 146 VehLong2_A_Actl 1;
BA_ "U_CD42_MY14_Gas_Rx" SG_ 146 VehLong2_A_Actl 1;
BA_ "U_P552_MY15_Gas_Rx" SG_ 146 VehLong2_A_Actl 1;
BA_ "U_C489_MY14_Gas_Rx" SG_ 146 VehLong2_A_Actl 1;
BA_ "U_U502_MY15_Gas_Rx" SG_ 146 VehLong2_A_Actl 1;
BA_ "U_UP375_MY15_Gas_Rx" SG_ 146 VehLong2_A_Actl 1;
BA_ "U_UP375_MY15_Diesel_Rx" SG_ 146 VehLong2_A_Actl 1;
BA_ "U_CD43_MY16_Gas_Rx" SG_ 146 VehLong2_A_Actl 1;
BA_ "GenSigSendType" SG_ 1870 TesterPhysicalResDCDC 3;
BA_ "U_CD4_MY13_Diesel_Rx" SG_ 1870 TesterPhysicalResDCDC 1;
BA_ "U_CD4_MY13_Gas_Rx" SG_ 1870 TesterPhysicalResDCDC 1;
BA_ "U_CD4_MY13_Hev_Rx" SG_ 1870 TesterPhysicalResDCDC 1;
BA_ "U_CD4_MY13_Phev_Rx" SG_ 1870 TesterPhysicalResDCDC 1;
BA_ "U_CD42_MY14_Diesel_Rx" SG_ 1870 TesterPhysicalResDCDC 1;
BA_ "U_CD42_MY14_Gas_Rx" SG_ 1870 TesterPhysicalResDCDC 1;
BA_ "U_P552_MY15_Gas_Rx" SG_ 1870 TesterPhysicalResDCDC 1;
BA_ "U_S550_MY15_Gas_Rx" SG_ 1870 TesterPhysicalResDCDC 1;
BA_ "U_C489_MY14_Gas_Rx" SG_ 1870 TesterPhysicalResDCDC 1;
BA_ "U_CD4_MY13_Diesel_Tx" SG_ 1870 TesterPhysicalResDCDC 1;
BA_ "U_CD4_MY13_Gas_Tx" SG_ 1870 TesterPhysicalResDCDC 1;
BA_ "U_CD42_MY14_Diesel_Tx" SG_ 1870 TesterPhysicalResDCDC 1;
BA_ "U_CD42_MY14_Gas_Tx" SG_ 1870 TesterPhysicalResDCDC 1;
BA_ "U_P552_MY15_Gas_Tx" SG_ 1870 TesterPhysicalResDCDC 1;
BA_ "U_UP375_MY15_Diesel_Tx" SG_ 1870 TesterPhysicalResDCDC 1;
BA_ "U_CD43_MY16_Gas_Tx" SG_ 1870 TesterPhysicalResDCDC 1;
BA_ "U_CD4_MY14_Diesel_Tx" SG_ 1870 TesterPhysicalResDCDC 1;
BA_ "U_CD4_MY14_Gas_Tx" SG_ 1870 TesterPhysicalResDCDC 1;
BA_ "GenSigSendType" SG_ 1862 TesterPhysicalReqDCDC 3;
BA_ "U_CD4_MY13_Diesel_Rx" SG_ 1862 TesterPhysicalReqDCDC 1;
BA_ "U_CD4_MY13_Gas_Rx" SG_ 1862 TesterPhysicalReqDCDC 1;
BA_ "U_CD42_MY14_Diesel_Rx" SG_ 1862 TesterPhysicalReqDCDC 1;
BA_ "U_CD42_MY14_Gas_Rx" SG_ 1862 TesterPhysicalReqDCDC 1;
BA_ "U_P552_MY15_Gas_Rx" SG_ 1862 TesterPhysicalReqDCDC 1;
BA_ "U_UP375_MY15_Diesel_Rx" SG_ 1862 TesterPhysicalReqDCDC 1;
BA_ "U_CD43_MY16_Gas_Rx" SG_ 1862 TesterPhysicalReqDCDC 1;
BA_ "U_CD4_MY14_Diesel_Rx" SG_ 1862 TesterPhysicalReqDCDC 1;
BA_ "U_CD4_MY14_Gas_Rx" SG_ 1862 TesterPhysicalReqDCDC 1;
BA_ "U_CD4_MY13_Diesel_Tx" SG_ 1862 TesterPhysicalReqDCDC 1;
BA_ "U_CD4_MY13_Gas_Tx" SG_ 1862 TesterPhysicalReqDCDC 1;
BA_ "U_CD4_MY13_Hev_Tx" SG_ 1862 TesterPhysicalReqDCDC 1;
BA_ "U_CD4_MY13_Phev_Tx" SG_ 1862 TesterPhysicalReqDCDC 1;
BA_ "U_CD42_MY14_Diesel_Tx" SG_ 1862 TesterPhysicalReqDCDC 1;
BA_ "U_CD42_MY14_Gas_Tx" SG_ 1862 TesterPhysicalReqDCDC 1;
BA_ "U_P552_MY15_Gas_Tx" SG_ 1862 TesterPhysicalReqDCDC 1;
BA_ "U_S550_MY15_Gas_Tx" SG_ 1862 TesterPhysicalReqDCDC 1;
BA_ "U_C489_MY14_Gas_Tx" SG_ 1862 TesterPhysicalReqDCDC 1;
BA_ "GenSigSendType" SG_ 1697 UUDTPCMResponse2 3;
BA_ "U_CD4_MY13_Diesel_Rx" SG_ 1697 UUDTPCMResponse2 1;
BA_ "U_CD4_MY13_Gas_Rx" SG_ 1697 UUDTPCMResponse2 1;
BA_ "U_CD4_MY13_Hev_Rx" SG_ 1697 UUDTPCMResponse2 1;
BA_ "U_CD4_MY13_Phev_Rx" SG_ 1697 UUDTPCMResponse2 1;
BA_ "U_CD42_MY14_Diesel_Rx" SG_ 1697 UUDTPCMResponse2 1;
BA_ "U_CD42_MY14_Gas_Rx" SG_ 1697 UUDTPCMResponse2 1;
BA_ "U_P552_MY15_Gas_Rx" SG_ 1697 UUDTPCMResponse2 1;
BA_ "U_S550_MY15_Gas_Rx" SG_ 1697 UUDTPCMResponse2 1;
BA_ "U_C489_MY14_Gas_Rx" SG_ 1697 UUDTPCMResponse2 1;
BA_ "U_CD4_MY13_Gas_Tx" SG_ 1697 UUDTPCMResponse2 1;
BA_ "U_CD42_MY14_Gas_Tx" SG_ 1697 UUDTPCMResponse2 1;
BA_ "U_P552_MY15_Gas_Tx" SG_ 1697 UUDTPCMResponse2 1;
BA_ "U_S550_MY15_Gas_Tx" SG_ 1697 UUDTPCMResponse2 1;
BA_ "U_C489_MY14_Gas_Tx" SG_ 1697 UUDTPCMResponse2 1;
BA_ "U_U502_MY15_Gas_Tx" SG_ 1697 UUDTPCMResponse2 1;
BA_ "U_UP375_MY15_Gas_Tx" SG_ 1697 UUDTPCMResponse2 1;
BA_ "U_CD43_MY16_Gas_Tx" SG_ 1697 UUDTPCMResponse2 1;
BA_ "U_CD4_MY14_Gas_Tx" SG_ 1697 UUDTPCMResponse2 1;
BA_ "GenSigSendType" SG_ 1696 UUDTPCMResponse1 3;
BA_ "U_CD4_MY13_Diesel_Rx" SG_ 1696 UUDTPCMResponse1 1;
BA_ "U_CD4_MY13_Gas_Rx" SG_ 1696 UUDTPCMResponse1 1;
BA_ "U_CD4_MY13_Hev_Rx" SG_ 1696 UUDTPCMResponse1 1;
BA_ "U_CD4_MY13_Phev_Rx" SG_ 1696 UUDTPCMResponse1 1;
BA_ "U_CD42_MY14_Diesel_Rx" SG_ 1696 UUDTPCMResponse1 1;
BA_ "U_CD42_MY14_Gas_Rx" SG_ 1696 UUDTPCMResponse1 1;
BA_ "U_P552_MY15_Gas_Rx" SG_ 1696 UUDTPCMResponse1 1;
BA_ "U_S550_MY15_Gas_Rx" SG_ 1696 UUDTPCMResponse1 1;
BA_ "U_C489_MY14_Gas_Rx" SG_ 1696 UUDTPCMResponse1 1;
BA_ "U_CD4_MY13_Gas_Tx" SG_ 1696 UUDTPCMResponse1 1;
BA_ "U_CD42_MY14_Gas_Tx" SG_ 1696 UUDTPCMResponse1 1;
BA_ "U_P552_MY15_Gas_Tx" SG_ 1696 UUDTPCMResponse1 1;
BA_ "U_S550_MY15_Gas_Tx" SG_ 1696 UUDTPCMResponse1 1;
BA_ "U_C489_MY14_Gas_Tx" SG_ 1696 UUDTPCMResponse1 1;
BA_ "U_U502_MY15_Gas_Tx" SG_ 1696 UUDTPCMResponse1 1;
BA_ "U_UP375_MY15_Gas_Tx" SG_ 1696 UUDTPCMResponse1 1;
BA_ "U_CD43_MY16_Gas_Tx" SG_ 1696 UUDTPCMResponse1 1;
BA_ "U_CD4_MY14_Gas_Tx" SG_ 1696 UUDTPCMResponse1 1;
BA_ "CrossOver_InfoCAN" SG_ 967 CamraOvrlTow_D_Actl 1;
BA_ "GenSigSendType" SG_ 967 CamraOvrlTow_D_Actl 3;
BA_ "U_CD4_MY13_Diesel_Tx" SG_ 967 CamraOvrlTow_D_Actl 1;
BA_ "U_CD4_MY13_Gas_Tx" SG_ 967 CamraOvrlTow_D_Actl 1;
BA_ "U_CD4_MY13_Hev_Tx" SG_ 967 CamraOvrlTow_D_Actl 1;
BA_ "U_CD4_MY13_Phev_Tx" SG_ 967 CamraOvrlTow_D_Actl 1;
BA_ "U_CD42_MY14_Diesel_Tx" SG_ 967 CamraOvrlTow_D_Actl 1;
BA_ "U_CD42_MY14_Gas_Tx" SG_ 967 CamraOvrlTow_D_Actl 1;
BA_ "U_P552_MY15_Gas_Tx" SG_ 967 CamraOvrlTow_D_Actl 1;
BA_ "U_S550_MY15_Gas_Tx" SG_ 967 CamraOvrlTow_D_Actl 1;
BA_ "U_C489_MY14_Gas_Tx" SG_ 967 CamraOvrlTow_D_Actl 1;
BA_ "U_U502_MY15_Gas_Tx" SG_ 967 CamraOvrlTow_D_Actl 1;
BA_ "U_UP375_MY15_Gas_Tx" SG_ 967 CamraOvrlTow_D_Actl 1;
BA_ "U_UP375_MY15_Diesel_Tx" SG_ 967 CamraOvrlTow_D_Actl 1;
BA_ "U_CD43_MY16_Gas_Tx" SG_ 967 CamraOvrlTow_D_Actl 1;
BA_ "U_CD4_MY14_Diesel_Tx" SG_ 967 CamraOvrlTow_D_Actl 1;
BA_ "U_CD4_MY14_Gas_Tx" SG_ 967 CamraOvrlTow_D_Actl 1;
BA_ "U_CD4_MY14_Hev_Tx" SG_ 967 CamraOvrlTow_D_Actl 1;
BA_ "U_CD4_MY14_Phev_Tx" SG_ 967 CamraOvrlTow_D_Actl 1;
BA_ "CrossOver_InfoCAN" SG_ 967 CamZoomActiveState 1;
BA_ "CrossOver_LIN" SG_ 967 CamZoomActiveState 1;
BA_ "GenSigSendType" SG_ 967 CamZoomActiveState 3;
BA_ "U_CD4_MY13_Diesel_Tx" SG_ 967 CamZoomActiveState 1;
BA_ "U_CD4_MY13_Gas_Tx" SG_ 967 CamZoomActiveState 1;
BA_ "U_CD4_MY13_Hev_Tx" SG_ 967 CamZoomActiveState 1;
BA_ "U_CD4_MY13_Phev_Tx" SG_ 967 CamZoomActiveState 1;
BA_ "U_CD42_MY14_Diesel_Tx" SG_ 967 CamZoomActiveState 1;
BA_ "U_CD42_MY14_Gas_Tx" SG_ 967 CamZoomActiveState 1;
BA_ "U_P552_MY15_Gas_Tx" SG_ 967 CamZoomActiveState 1;
BA_ "U_S550_MY15_Gas_Tx" SG_ 967 CamZoomActiveState 1;
BA_ "U_C489_MY14_Gas_Tx" SG_ 967 CamZoomActiveState 1;
BA_ "U_U502_MY15_Gas_Tx" SG_ 967 CamZoomActiveState 1;
BA_ "U_UP375_MY15_Gas_Tx" SG_ 967 CamZoomActiveState 1;
BA_ "U_UP375_MY15_Diesel_Tx" SG_ 967 CamZoomActiveState 1;
BA_ "U_CD43_MY16_Gas_Tx" SG_ 967 CamZoomActiveState 1;
BA_ "U_CD4_MY14_Diesel_Tx" SG_ 967 CamZoomActiveState 1;
BA_ "U_CD4_MY14_Gas_Tx" SG_ 967 CamZoomActiveState 1;
BA_ "U_CD4_MY14_Hev_Tx" SG_ 967 CamZoomActiveState 1;
BA_ "U_CD4_MY14_Phev_Tx" SG_ 967 CamZoomActiveState 1;
BA_ "CrossOver_InfoCAN" SG_ 967 CamraZoomMan_D_Actl 1;
BA_ "CrossOver_LIN" SG_ 967 CamraZoomMan_D_Actl 1;
BA_ "GenSigSendType" SG_ 967 CamraZoomMan_D_Actl 3;
BA_ "U_CD4_MY13_Diesel_Tx" SG_ 967 CamraZoomMan_D_Actl 1;
BA_ "U_CD4_MY13_Gas_Tx" SG_ 967 CamraZoomMan_D_Actl 1;
BA_ "U_CD4_MY13_Hev_Tx" SG_ 967 CamraZoomMan_D_Actl 1;
BA_ "U_CD4_MY13_Phev_Tx" SG_ 967 CamraZoomMan_D_Actl 1;
BA_ "U_CD42_MY14_Diesel_Tx" SG_ 967 CamraZoomMan_D_Actl 1;
BA_ "U_CD42_MY14_Gas_Tx" SG_ 967 CamraZoomMan_D_Actl 1;
BA_ "U_P552_MY15_Gas_Tx" SG_ 967 CamraZoomMan_D_Actl 1;
BA_ "U_S550_MY15_Gas_Tx" SG_ 967 CamraZoomMan_D_Actl 1;
BA_ "U_C489_MY14_Gas_Tx" SG_ 967 CamraZoomMan_D_Actl 1;
BA_ "U_U502_MY15_Gas_Tx" SG_ 967 CamraZoomMan_D_Actl 1;
BA_ "U_UP375_MY15_Gas_Tx" SG_ 967 CamraZoomMan_D_Actl 1;
BA_ "U_UP375_MY15_Diesel_Tx" SG_ 967 CamraZoomMan_D_Actl 1;
BA_ "U_CD43_MY16_Gas_Tx" SG_ 967 CamraZoomMan_D_Actl 1;
BA_ "U_CD4_MY14_Diesel_Tx" SG_ 967 CamraZoomMan_D_Actl 1;
BA_ "U_CD4_MY14_Gas_Tx" SG_ 967 CamraZoomMan_D_Actl 1;
BA_ "U_CD4_MY14_Hev_Tx" SG_ 967 CamraZoomMan_D_Actl 1;
BA_ "U_CD4_MY14_Phev_Tx" SG_ 967 CamraZoomMan_D_Actl 1;
BA_ "CrossOver_InfoCAN" SG_ 967 CamraOvrlStat_D_Actl 1;
BA_ "CrossOver_LIN" SG_ 967 CamraOvrlStat_D_Actl 1;
BA_ "GenSigSendType" SG_ 967 CamraOvrlStat_D_Actl 3;
BA_ "U_CD4_MY13_Diesel_Tx" SG_ 967 CamraOvrlStat_D_Actl 1;
BA_ "U_CD4_MY13_Gas_Tx" SG_ 967 CamraOvrlStat_D_Actl 1;
BA_ "U_CD4_MY13_Hev_Tx" SG_ 967 CamraOvrlStat_D_Actl 1;
BA_ "U_CD4_MY13_Phev_Tx" SG_ 967 CamraOvrlStat_D_Actl 1;
BA_ "U_CD42_MY14_Diesel_Tx" SG_ 967 CamraOvrlStat_D_Actl 1;
BA_ "U_CD42_MY14_Gas_Tx" SG_ 967 CamraOvrlStat_D_Actl 1;
BA_ "U_P552_MY15_Gas_Tx" SG_ 967 CamraOvrlStat_D_Actl 1;
BA_ "U_S550_MY15_Gas_Tx" SG_ 967 CamraOvrlStat_D_Actl 1;
BA_ "U_C489_MY14_Gas_Tx" SG_ 967 CamraOvrlStat_D_Actl 1;
BA_ "U_U502_MY15_Gas_Tx" SG_ 967 CamraOvrlStat_D_Actl 1;
BA_ "U_UP375_MY15_Gas_Tx" SG_ 967 CamraOvrlStat_D_Actl 1;
BA_ "U_UP375_MY15_Diesel_Tx" SG_ 967 CamraOvrlStat_D_Actl 1;
BA_ "U_CD43_MY16_Gas_Tx" SG_ 967 CamraOvrlStat_D_Actl 1;
BA_ "U_CD4_MY14_Diesel_Tx" SG_ 967 CamraOvrlStat_D_Actl 1;
BA_ "U_CD4_MY14_Gas_Tx" SG_ 967 CamraOvrlStat_D_Actl 1;
BA_ "U_CD4_MY14_Hev_Tx" SG_ 967 CamraOvrlStat_D_Actl 1;
BA_ "U_CD4_MY14_Phev_Tx" SG_ 967 CamraOvrlStat_D_Actl 1;
BA_ "CrossOver_InfoCAN" SG_ 967 CamraOvrlDyn_D_Actl 1;
BA_ "CrossOver_LIN" SG_ 967 CamraOvrlDyn_D_Actl 1;
BA_ "GenSigSendType" SG_ 967 CamraOvrlDyn_D_Actl 3;
BA_ "U_CD4_MY13_Diesel_Tx" SG_ 967 CamraOvrlDyn_D_Actl 1;
BA_ "U_CD4_MY13_Gas_Tx" SG_ 967 CamraOvrlDyn_D_Actl 1;
BA_ "U_CD4_MY13_Hev_Tx" SG_ 967 CamraOvrlDyn_D_Actl 1;
BA_ "U_CD4_MY13_Phev_Tx" SG_ 967 CamraOvrlDyn_D_Actl 1;
BA_ "U_CD42_MY14_Diesel_Tx" SG_ 967 CamraOvrlDyn_D_Actl 1;
BA_ "U_CD42_MY14_Gas_Tx" SG_ 967 CamraOvrlDyn_D_Actl 1;
BA_ "U_P552_MY15_Gas_Tx" SG_ 967 CamraOvrlDyn_D_Actl 1;
BA_ "U_S550_MY15_Gas_Tx" SG_ 967 CamraOvrlDyn_D_Actl 1;
BA_ "U_C489_MY14_Gas_Tx" SG_ 967 CamraOvrlDyn_D_Actl 1;
BA_ "U_U502_MY15_Gas_Tx" SG_ 967 CamraOvrlDyn_D_Actl 1;
BA_ "U_UP375_MY15_Gas_Tx" SG_ 967 CamraOvrlDyn_D_Actl 1;
BA_ "U_UP375_MY15_Diesel_Tx" SG_ 967 CamraOvrlDyn_D_Actl 1;
BA_ "U_CD43_MY16_Gas_Tx" SG_ 967 CamraOvrlDyn_D_Actl 1;
BA_ "U_CD4_MY14_Diesel_Tx" SG_ 967 CamraOvrlDyn_D_Actl 1;
BA_ "U_CD4_MY14_Gas_Tx" SG_ 967 CamraOvrlDyn_D_Actl 1;
BA_ "U_CD4_MY14_Hev_Tx" SG_ 967 CamraOvrlDyn_D_Actl 1;
BA_ "U_CD4_MY14_Phev_Tx" SG_ 967 CamraOvrlDyn_D_Actl 1;
BA_ "CrossOver_InfoCAN" SG_ 967 CamPDCGuidStat 1;
BA_ "CrossOver_LIN" SG_ 967 CamPDCGuidStat 1;
BA_ "GenSigSendType" SG_ 967 CamPDCGuidStat 3;
BA_ "U_CD4_MY13_Diesel_Tx" SG_ 967 CamPDCGuidStat 1;
BA_ "U_CD4_MY13_Gas_Tx" SG_ 967 CamPDCGuidStat 1;
BA_ "U_CD4_MY13_Hev_Tx" SG_ 967 CamPDCGuidStat 1;
BA_ "U_CD4_MY13_Phev_Tx" SG_ 967 CamPDCGuidStat 1;
BA_ "U_CD42_MY14_Diesel_Tx" SG_ 967 CamPDCGuidStat 1;
BA_ "U_CD42_MY14_Gas_Tx" SG_ 967 CamPDCGuidStat 1;
BA_ "U_P552_MY15_Gas_Tx" SG_ 967 CamPDCGuidStat 1;
BA_ "U_S550_MY15_Gas_Tx" SG_ 967 CamPDCGuidStat 1;
BA_ "U_C489_MY14_Gas_Tx" SG_ 967 CamPDCGuidStat 1;
BA_ "U_U502_MY15_Gas_Tx" SG_ 967 CamPDCGuidStat 1;
BA_ "U_UP375_MY15_Gas_Tx" SG_ 967 CamPDCGuidStat 1;
BA_ "U_UP375_MY15_Diesel_Tx" SG_ 967 CamPDCGuidStat 1;
BA_ "U_CD43_MY16_Gas_Tx" SG_ 967 CamPDCGuidStat 1;
BA_ "U_CD4_MY14_Diesel_Tx" SG_ 967 CamPDCGuidStat 1;
BA_ "U_CD4_MY14_Gas_Tx" SG_ 967 CamPDCGuidStat 1;
BA_ "U_CD4_MY14_Hev_Tx" SG_ 967 CamPDCGuidStat 1;
BA_ "U_CD4_MY14_Phev_Tx" SG_ 967 CamPDCGuidStat 1;
BA_ "CrossOver_InfoCAN" SG_ 949 Tire_Press_RR_ORR_Data 1;
BA_ "GenSigStartValue" SG_ 949 Tire_Press_RR_ORR_Data 65533;
BA_ "U_CD4_MY13_Diesel_Tx" SG_ 949 Tire_Press_RR_ORR_Data 1;
BA_ "U_CD4_MY13_Gas_Tx" SG_ 949 Tire_Press_RR_ORR_Data 1;
BA_ "U_CD4_MY13_Hev_Tx" SG_ 949 Tire_Press_RR_ORR_Data 1;
BA_ "U_CD4_MY13_Phev_Tx" SG_ 949 Tire_Press_RR_ORR_Data 1;
BA_ "U_CD42_MY14_Diesel_Tx" SG_ 949 Tire_Press_RR_ORR_Data 1;
BA_ "U_CD42_MY14_Gas_Tx" SG_ 949 Tire_Press_RR_ORR_Data 1;
BA_ "U_P552_MY15_Gas_Tx" SG_ 949 Tire_Press_RR_ORR_Data 1;
BA_ "U_S550_MY15_Gas_Tx" SG_ 949 Tire_Press_RR_ORR_Data 1;
BA_ "U_C489_MY14_Gas_Tx" SG_ 949 Tire_Press_RR_ORR_Data 1;
BA_ "U_U502_MY15_Gas_Tx" SG_ 949 Tire_Press_RR_ORR_Data 1;
BA_ "U_UP375_MY15_Gas_Tx" SG_ 949 Tire_Press_RR_ORR_Data 1;
BA_ "U_UP375_MY15_Diesel_Tx" SG_ 949 Tire_Press_RR_ORR_Data 1;
BA_ "U_CD43_MY16_Gas_Tx" SG_ 949 Tire_Press_RR_ORR_Data 1;
BA_ "U_CD4_MY14_Diesel_Tx" SG_ 949 Tire_Press_RR_ORR_Data 1;
BA_ "U_CD4_MY14_Gas_Tx" SG_ 949 Tire_Press_RR_ORR_Data 1;
BA_ "U_CD4_MY14_Hev_Tx" SG_ 949 Tire_Press_RR_ORR_Data 1;
BA_ "U_CD4_MY14_Phev_Tx" SG_ 949 Tire_Press_RR_ORR_Data 1;
BA_ "CrossOver_InfoCAN" SG_ 949 Tire_Press_LR_OLR_Data 1;
BA_ "GenSigStartValue" SG_ 949 Tire_Press_LR_OLR_Data 65533;
BA_ "U_CD4_MY13_Diesel_Tx" SG_ 949 Tire_Press_LR_OLR_Data 1;
BA_ "U_CD4_MY13_Gas_Tx" SG_ 949 Tire_Press_LR_OLR_Data 1;
BA_ "U_CD4_MY13_Hev_Tx" SG_ 949 Tire_Press_LR_OLR_Data 1;
BA_ "U_CD4_MY13_Phev_Tx" SG_ 949 Tire_Press_LR_OLR_Data 1;
BA_ "U_CD42_MY14_Diesel_Tx" SG_ 949 Tire_Press_LR_OLR_Data 1;
BA_ "U_CD42_MY14_Gas_Tx" SG_ 949 Tire_Press_LR_OLR_Data 1;
BA_ "U_P552_MY15_Gas_Tx" SG_ 949 Tire_Press_LR_OLR_Data 1;
BA_ "U_S550_MY15_Gas_Tx" SG_ 949 Tire_Press_LR_OLR_Data 1;
BA_ "U_C489_MY14_Gas_Tx" SG_ 949 Tire_Press_LR_OLR_Data 1;
BA_ "U_U502_MY15_Gas_Tx" SG_ 949 Tire_Press_LR_OLR_Data 1;
BA_ "U_UP375_MY15_Gas_Tx" SG_ 949 Tire_Press_LR_OLR_Data 1;
BA_ "U_UP375_MY15_Diesel_Tx" SG_ 949 Tire_Press_LR_OLR_Data 1;
BA_ "U_CD43_MY16_Gas_Tx" SG_ 949 Tire_Press_LR_OLR_Data 1;
BA_ "U_CD4_MY14_Diesel_Tx" SG_ 949 Tire_Press_LR_OLR_Data 1;
BA_ "U_CD4_MY14_Gas_Tx" SG_ 949 Tire_Press_LR_OLR_Data 1;
BA_ "U_CD4_MY14_Hev_Tx" SG_ 949 Tire_Press_LR_OLR_Data 1;
BA_ "U_CD4_MY14_Phev_Tx" SG_ 949 Tire_Press_LR_OLR_Data 1;
BA_ "CrossOver_InfoCAN" SG_ 949 Tire_Press_LF_Data 1;
BA_ "GenSigStartValue" SG_ 949 Tire_Press_LF_Data 65533;
BA_ "U_CD4_MY13_Diesel_Tx" SG_ 949 Tire_Press_LF_Data 1;
BA_ "U_CD4_MY13_Gas_Tx" SG_ 949 Tire_Press_LF_Data 1;
BA_ "U_CD4_MY13_Hev_Tx" SG_ 949 Tire_Press_LF_Data 1;
BA_ "U_CD4_MY13_Phev_Tx" SG_ 949 Tire_Press_LF_Data 1;
BA_ "U_CD42_MY14_Diesel_Tx" SG_ 949 Tire_Press_LF_Data 1;
BA_ "U_CD42_MY14_Gas_Tx" SG_ 949 Tire_Press_LF_Data 1;
BA_ "U_P552_MY15_Gas_Tx" SG_ 949 Tire_Press_LF_Data 1;
BA_ "U_S550_MY15_Gas_Tx" SG_ 949 Tire_Press_LF_Data 1;
BA_ "U_C489_MY14_Gas_Tx" SG_ 949 Tire_Press_LF_Data 1;
BA_ "U_U502_MY15_Gas_Tx" SG_ 949 Tire_Press_LF_Data 1;
BA_ "U_UP375_MY15_Gas_Tx" SG_ 949 Tire_Press_LF_Data 1;
BA_ "U_UP375_MY15_Diesel_Tx" SG_ 949 Tire_Press_LF_Data 1;
BA_ "U_CD43_MY16_Gas_Tx" SG_ 949 Tire_Press_LF_Data 1;
BA_ "U_CD4_MY14_Diesel_Tx" SG_ 949 Tire_Press_LF_Data 1;
BA_ "U_CD4_MY14_Gas_Tx" SG_ 949 Tire_Press_LF_Data 1;
BA_ "U_CD4_MY14_Hev_Tx" SG_ 949 Tire_Press_LF_Data 1;
BA_ "U_CD4_MY14_Phev_Tx" SG_ 949 Tire_Press_LF_Data 1;
BA_ "CrossOver_InfoCAN" SG_ 949 Tire_Press_RF_Data 1;
BA_ "GenSigStartValue" SG_ 949 Tire_Press_RF_Data 65533;
BA_ "U_CD4_MY13_Diesel_Tx" SG_ 949 Tire_Press_RF_Data 1;
BA_ "U_CD4_MY13_Gas_Tx" SG_ 949 Tire_Press_RF_Data 1;
BA_ "U_CD4_MY13_Hev_Tx" SG_ 949 Tire_Press_RF_Data 1;
BA_ "U_CD4_MY13_Phev_Tx" SG_ 949 Tire_Press_RF_Data 1;
BA_ "U_CD42_MY14_Diesel_Tx" SG_ 949 Tire_Press_RF_Data 1;
BA_ "U_CD42_MY14_Gas_Tx" SG_ 949 Tire_Press_RF_Data 1;
BA_ "U_P552_MY15_Gas_Tx" SG_ 949 Tire_Press_RF_Data 1;
BA_ "U_S550_MY15_Gas_Tx" SG_ 949 Tire_Press_RF_Data 1;
BA_ "U_C489_MY14_Gas_Tx" SG_ 949 Tire_Press_RF_Data 1;
BA_ "U_U502_MY15_Gas_Tx" SG_ 949 Tire_Press_RF_Data 1;
BA_ "U_UP375_MY15_Gas_Tx" SG_ 949 Tire_Press_RF_Data 1;
BA_ "U_UP375_MY15_Diesel_Tx" SG_ 949 Tire_Press_RF_Data 1;
BA_ "U_CD43_MY16_Gas_Tx" SG_ 949 Tire_Press_RF_Data 1;
BA_ "U_CD4_MY14_Diesel_Tx" SG_ 949 Tire_Press_RF_Data 1;
BA_ "U_CD4_MY14_Gas_Tx" SG_ 949 Tire_Press_RF_Data 1;
BA_ "U_CD4_MY14_Hev_Tx" SG_ 949 Tire_Press_RF_Data 1;
BA_ "U_CD4_MY14_Phev_Tx" SG_ 949 Tire_Press_RF_Data 1;
BA_ "Gateway_ID" SG_ 948 Tire_Press_Placrd_Rear 27641;
BA_ "U_UP375_MY15_Diesel_Tx" SG_ 948 Tire_Press_Placrd_Rear 1;
BA_ "U_UP375_MY15_Gas_Tx" SG_ 948 Tire_Press_Placrd_Rear 1;
BA_ "GenSigStartValue" SG_ 948 Tire_Press_Placrd_Rear 255;
BA_ "GenSigSendType" SG_ 948 Tire_Press_Placrd_Rear 3;
BA_ "Gateway_ID" SG_ 948 Tire_Press_Placrd_Frnt 27640;
BA_ "U_UP375_MY15_Diesel_Tx" SG_ 948 Tire_Press_Placrd_Frnt 1;
BA_ "U_UP375_MY15_Gas_Tx" SG_ 948 Tire_Press_Placrd_Frnt 1;
BA_ "GenSigStartValue" SG_ 948 Tire_Press_Placrd_Frnt 255;
BA_ "GenSigSendType" SG_ 948 Tire_Press_Placrd_Frnt 3;
BA_ "CrossOver_InfoCAN" SG_ 948 Tire_Press_ILR_Stat 1;
BA_ "GenSigSendType" SG_ 948 Tire_Press_ILR_Stat 3;
BA_ "U_CD4_MY13_Diesel_Tx" SG_ 948 Tire_Press_ILR_Stat 1;
BA_ "U_CD4_MY13_Gas_Tx" SG_ 948 Tire_Press_ILR_Stat 1;
BA_ "U_CD4_MY13_Hev_Tx" SG_ 948 Tire_Press_ILR_Stat 1;
BA_ "U_CD4_MY13_Phev_Tx" SG_ 948 Tire_Press_ILR_Stat 1;
BA_ "U_CD42_MY14_Diesel_Tx" SG_ 948 Tire_Press_ILR_Stat 1;
BA_ "U_CD42_MY14_Gas_Tx" SG_ 948 Tire_Press_ILR_Stat 1;
BA_ "U_P552_MY15_Gas_Tx" SG_ 948 Tire_Press_ILR_Stat 1;
BA_ "U_S550_MY15_Gas_Tx" SG_ 948 Tire_Press_ILR_Stat 1;
BA_ "U_C489_MY14_Gas_Tx" SG_ 948 Tire_Press_ILR_Stat 1;
BA_ "U_U502_MY15_Gas_Tx" SG_ 948 Tire_Press_ILR_Stat 1;
BA_ "U_UP375_MY15_Gas_Tx" SG_ 948 Tire_Press_ILR_Stat 1;
BA_ "U_UP375_MY15_Diesel_Tx" SG_ 948 Tire_Press_ILR_Stat 1;
BA_ "U_CD43_MY16_Gas_Tx" SG_ 948 Tire_Press_ILR_Stat 1;
BA_ "U_CD4_MY14_Diesel_Tx" SG_ 948 Tire_Press_ILR_Stat 1;
BA_ "U_CD4_MY14_Gas_Tx" SG_ 948 Tire_Press_ILR_Stat 1;
BA_ "U_CD4_MY14_Hev_Tx" SG_ 948 Tire_Press_ILR_Stat 1;
BA_ "U_CD4_MY14_Phev_Tx" SG_ 948 Tire_Press_ILR_Stat 1;
BA_ "CrossOver_InfoCAN" SG_ 948 Tire_Press_IRR_Stat 1;
BA_ "GenSigSendType" SG_ 948 Tire_Press_IRR_Stat 3;
BA_ "U_CD4_MY13_Diesel_Tx" SG_ 948 Tire_Press_IRR_Stat 1;
BA_ "U_CD4_MY13_Gas_Tx" SG_ 948 Tire_Press_IRR_Stat 1;
BA_ "U_CD4_MY13_Hev_Tx" SG_ 948 Tire_Press_IRR_Stat 1;
BA_ "U_CD4_MY13_Phev_Tx" SG_ 948 Tire_Press_IRR_Stat 1;
BA_ "U_CD42_MY14_Diesel_Tx" SG_ 948 Tire_Press_IRR_Stat 1;
BA_ "U_CD42_MY14_Gas_Tx" SG_ 948 Tire_Press_IRR_Stat 1;
BA_ "U_P552_MY15_Gas_Tx" SG_ 948 Tire_Press_IRR_Stat 1;
BA_ "U_S550_MY15_Gas_Tx" SG_ 948 Tire_Press_IRR_Stat 1;
BA_ "U_C489_MY14_Gas_Tx" SG_ 948 Tire_Press_IRR_Stat 1;
BA_ "U_U502_MY15_Gas_Tx" SG_ 948 Tire_Press_IRR_Stat 1;
BA_ "U_UP375_MY15_Gas_Tx" SG_ 948 Tire_Press_IRR_Stat 1;
BA_ "U_UP375_MY15_Diesel_Tx" SG_ 948 Tire_Press_IRR_Stat 1;
BA_ "U_CD43_MY16_Gas_Tx" SG_ 948 Tire_Press_IRR_Stat 1;
BA_ "U_CD4_MY14_Diesel_Tx" SG_ 948 Tire_Press_IRR_Stat 1;
BA_ "U_CD4_MY14_Gas_Tx" SG_ 948 Tire_Press_IRR_Stat 1;
BA_ "U_CD4_MY14_Hev_Tx" SG_ 948 Tire_Press_IRR_Stat 1;
BA_ "U_CD4_MY14_Phev_Tx" SG_ 948 Tire_Press_IRR_Stat 1;
BA_ "CrossOver_InfoCAN" SG_ 948 Tire_Press_LR_OLR_Stat 1;
BA_ "GenSigSendType" SG_ 948 Tire_Press_LR_OLR_Stat 3;
BA_ "U_CD4_MY13_Diesel_Tx" SG_ 948 Tire_Press_LR_OLR_Stat 1;
BA_ "U_CD4_MY13_Gas_Tx" SG_ 948 Tire_Press_LR_OLR_Stat 1;
BA_ "U_CD4_MY13_Hev_Tx" SG_ 948 Tire_Press_LR_OLR_Stat 1;
BA_ "U_CD4_MY13_Phev_Tx" SG_ 948 Tire_Press_LR_OLR_Stat 1;
BA_ "U_CD42_MY14_Diesel_Tx" SG_ 948 Tire_Press_LR_OLR_Stat 1;
BA_ "U_CD42_MY14_Gas_Tx" SG_ 948 Tire_Press_LR_OLR_Stat 1;
BA_ "U_P552_MY15_Gas_Tx" SG_ 948 Tire_Press_LR_OLR_Stat 1;
BA_ "U_S550_MY15_Gas_Tx" SG_ 948 Tire_Press_LR_OLR_Stat 1;
BA_ "U_C489_MY14_Gas_Tx" SG_ 948 Tire_Press_LR_OLR_Stat 1;
BA_ "U_U502_MY15_Gas_Tx" SG_ 948 Tire_Press_LR_OLR_Stat 1;
BA_ "U_UP375_MY15_Gas_Tx" SG_ 948 Tire_Press_LR_OLR_Stat 1;
BA_ "U_UP375_MY15_Diesel_Tx" SG_ 948 Tire_Press_LR_OLR_Stat 1;
BA_ "U_CD43_MY16_Gas_Tx" SG_ 948 Tire_Press_LR_OLR_Stat 1;
BA_ "U_CD4_MY14_Diesel_Tx" SG_ 948 Tire_Press_LR_OLR_Stat 1;
BA_ "U_CD4_MY14_Gas_Tx" SG_ 948 Tire_Press_LR_OLR_Stat 1;
BA_ "U_CD4_MY14_Hev_Tx" SG_ 948 Tire_Press_LR_OLR_Stat 1;
BA_ "U_CD4_MY14_Phev_Tx" SG_ 948 Tire_Press_LR_OLR_Stat 1;
BA_ "CrossOver_InfoCAN" SG_ 948 Tire_Press_RR_ORR_Stat 1;
BA_ "GenSigSendType" SG_ 948 Tire_Press_RR_ORR_Stat 3;
BA_ "U_CD4_MY13_Diesel_Tx" SG_ 948 Tire_Press_RR_ORR_Stat 1;
BA_ "U_CD4_MY13_Gas_Tx" SG_ 948 Tire_Press_RR_ORR_Stat 1;
BA_ "U_CD4_MY13_Hev_Tx" SG_ 948 Tire_Press_RR_ORR_Stat 1;
BA_ "U_CD4_MY13_Phev_Tx" SG_ 948 Tire_Press_RR_ORR_Stat 1;
BA_ "U_CD42_MY14_Diesel_Tx" SG_ 948 Tire_Press_RR_ORR_Stat 1;
BA_ "U_CD42_MY14_Gas_Tx" SG_ 948 Tire_Press_RR_ORR_Stat 1;
BA_ "U_P552_MY15_Gas_Tx" SG_ 948 Tire_Press_RR_ORR_Stat 1;
BA_ "U_S550_MY15_Gas_Tx" SG_ 948 Tire_Press_RR_ORR_Stat 1;
BA_ "U_C489_MY14_Gas_Tx" SG_ 948 Tire_Press_RR_ORR_Stat 1;
BA_ "U_U502_MY15_Gas_Tx" SG_ 948 Tire_Press_RR_ORR_Stat 1;
BA_ "U_UP375_MY15_Gas_Tx" SG_ 948 Tire_Press_RR_ORR_Stat 1;
BA_ "U_UP375_MY15_Diesel_Tx" SG_ 948 Tire_Press_RR_ORR_Stat 1;
BA_ "U_CD43_MY16_Gas_Tx" SG_ 948 Tire_Press_RR_ORR_Stat 1;
BA_ "U_CD4_MY14_Diesel_Tx" SG_ 948 Tire_Press_RR_ORR_Stat 1;
BA_ "U_CD4_MY14_Gas_Tx" SG_ 948 Tire_Press_RR_ORR_Stat 1;
BA_ "U_CD4_MY14_Hev_Tx" SG_ 948 Tire_Press_RR_ORR_Stat 1;
BA_ "U_CD4_MY14_Phev_Tx" SG_ 948 Tire_Press_RR_ORR_Stat 1;
BA_ "CrossOver_InfoCAN" SG_ 948 Tire_Press_RF_Stat 1;
BA_ "GenSigSendType" SG_ 948 Tire_Press_RF_Stat 3;
BA_ "U_CD4_MY13_Diesel_Tx" SG_ 948 Tire_Press_RF_Stat 1;
BA_ "U_CD4_MY13_Gas_Tx" SG_ 948 Tire_Press_RF_Stat 1;
BA_ "U_CD4_MY13_Hev_Tx" SG_ 948 Tire_Press_RF_Stat 1;
BA_ "U_CD4_MY13_Phev_Tx" SG_ 948 Tire_Press_RF_Stat 1;
BA_ "U_CD42_MY14_Diesel_Tx" SG_ 948 Tire_Press_RF_Stat 1;
BA_ "U_CD42_MY14_Gas_Tx" SG_ 948 Tire_Press_RF_Stat 1;
BA_ "U_P552_MY15_Gas_Tx" SG_ 948 Tire_Press_RF_Stat 1;
BA_ "U_S550_MY15_Gas_Tx" SG_ 948 Tire_Press_RF_Stat 1;
BA_ "U_C489_MY14_Gas_Tx" SG_ 948 Tire_Press_RF_Stat 1;
BA_ "U_U502_MY15_Gas_Tx" SG_ 948 Tire_Press_RF_Stat 1;
BA_ "U_UP375_MY15_Gas_Tx" SG_ 948 Tire_Press_RF_Stat 1;
BA_ "U_UP375_MY15_Diesel_Tx" SG_ 948 Tire_Press_RF_Stat 1;
BA_ "U_CD43_MY16_Gas_Tx" SG_ 948 Tire_Press_RF_Stat 1;
BA_ "U_CD4_MY14_Diesel_Tx" SG_ 948 Tire_Press_RF_Stat 1;
BA_ "U_CD4_MY14_Gas_Tx" SG_ 948 Tire_Press_RF_Stat 1;
BA_ "U_CD4_MY14_Hev_Tx" SG_ 948 Tire_Press_RF_Stat 1;
BA_ "U_CD4_MY14_Phev_Tx" SG_ 948 Tire_Press_RF_Stat 1;
BA_ "CrossOver_InfoCAN" SG_ 948 Tire_Press_LF_Stat 1;
BA_ "GenSigSendType" SG_ 948 Tire_Press_LF_Stat 3;
BA_ "U_CD4_MY13_Diesel_Tx" SG_ 948 Tire_Press_LF_Stat 1;
BA_ "U_CD4_MY13_Gas_Tx" SG_ 948 Tire_Press_LF_Stat 1;
BA_ "U_CD4_MY13_Hev_Tx" SG_ 948 Tire_Press_LF_Stat 1;
BA_ "U_CD4_MY13_Phev_Tx" SG_ 948 Tire_Press_LF_Stat 1;
BA_ "U_CD42_MY14_Diesel_Tx" SG_ 948 Tire_Press_LF_Stat 1;
BA_ "U_CD42_MY14_Gas_Tx" SG_ 948 Tire_Press_LF_Stat 1;
BA_ "U_P552_MY15_Gas_Tx" SG_ 948 Tire_Press_LF_Stat 1;
BA_ "U_S550_MY15_Gas_Tx" SG_ 948 Tire_Press_LF_Stat 1;
BA_ "U_C489_MY14_Gas_Tx" SG_ 948 Tire_Press_LF_Stat 1;
BA_ "U_U502_MY15_Gas_Tx" SG_ 948 Tire_Press_LF_Stat 1;
BA_ "U_UP375_MY15_Gas_Tx" SG_ 948 Tire_Press_LF_Stat 1;
BA_ "U_UP375_MY15_Diesel_Tx" SG_ 948 Tire_Press_LF_Stat 1;
BA_ "U_CD43_MY16_Gas_Tx" SG_ 948 Tire_Press_LF_Stat 1;
BA_ "U_CD4_MY14_Diesel_Tx" SG_ 948 Tire_Press_LF_Stat 1;
BA_ "U_CD4_MY14_Gas_Tx" SG_ 948 Tire_Press_LF_Stat 1;
BA_ "U_CD4_MY14_Hev_Tx" SG_ 948 Tire_Press_LF_Stat 1;
BA_ "U_CD4_MY14_Phev_Tx" SG_ 948 Tire_Press_LF_Stat 1;
BA_ "CrossOver_InfoCAN" SG_ 948 Tire_Press_System_Stat 1;
BA_ "GenSigSendType" SG_ 948 Tire_Press_System_Stat 3;
BA_ "U_CD4_MY13_Diesel_Tx" SG_ 948 Tire_Press_System_Stat 1;
BA_ "U_CD4_MY13_Gas_Tx" SG_ 948 Tire_Press_System_Stat 1;
BA_ "U_CD4_MY13_Hev_Tx" SG_ 948 Tire_Press_System_Stat 1;
BA_ "U_CD4_MY13_Phev_Tx" SG_ 948 Tire_Press_System_Stat 1;
BA_ "U_CD42_MY14_Diesel_Tx" SG_ 948 Tire_Press_System_Stat 1;
BA_ "U_CD42_MY14_Gas_Tx" SG_ 948 Tire_Press_System_Stat 1;
BA_ "U_P552_MY15_Gas_Tx" SG_ 948 Tire_Press_System_Stat 1;
BA_ "U_S550_MY15_Gas_Tx" SG_ 948 Tire_Press_System_Stat 1;
BA_ "U_C489_MY14_Gas_Tx" SG_ 948 Tire_Press_System_Stat 1;
BA_ "U_U502_MY15_Gas_Tx" SG_ 948 Tire_Press_System_Stat 1;
BA_ "U_UP375_MY15_Gas_Tx" SG_ 948 Tire_Press_System_Stat 1;
BA_ "U_UP375_MY15_Diesel_Tx" SG_ 948 Tire_Press_System_Stat 1;
BA_ "U_CD43_MY16_Gas_Tx" SG_ 948 Tire_Press_System_Stat 1;
BA_ "U_CD4_MY14_Diesel_Tx" SG_ 948 Tire_Press_System_Stat 1;
BA_ "U_CD4_MY14_Gas_Tx" SG_ 948 Tire_Press_System_Stat 1;
BA_ "U_CD4_MY14_Hev_Tx" SG_ 948 Tire_Press_System_Stat 1;
BA_ "U_CD4_MY14_Phev_Tx" SG_ 948 Tire_Press_System_Stat 1;
BA_ "CrossOver_InfoCAN" SG_ 948 Tire_Press_Telltale 1;
BA_ "GenSigSendType" SG_ 948 Tire_Press_Telltale 3;
BA_ "U_CD4_MY13_Diesel_Tx" SG_ 948 Tire_Press_Telltale 1;
BA_ "U_CD4_MY13_Gas_Tx" SG_ 948 Tire_Press_Telltale 1;
BA_ "U_CD4_MY13_Hev_Tx" SG_ 948 Tire_Press_Telltale 1;
BA_ "U_CD4_MY13_Phev_Tx" SG_ 948 Tire_Press_Telltale 1;
BA_ "U_CD42_MY14_Diesel_Tx" SG_ 948 Tire_Press_Telltale 1;
BA_ "U_CD42_MY14_Gas_Tx" SG_ 948 Tire_Press_Telltale 1;
BA_ "U_P552_MY15_Gas_Tx" SG_ 948 Tire_Press_Telltale 1;
BA_ "U_S550_MY15_Gas_Tx" SG_ 948 Tire_Press_Telltale 1;
BA_ "U_C489_MY14_Gas_Tx" SG_ 948 Tire_Press_Telltale 1;
BA_ "U_U502_MY15_Gas_Tx" SG_ 948 Tire_Press_Telltale 1;
BA_ "U_UP375_MY15_Gas_Tx" SG_ 948 Tire_Press_Telltale 1;
BA_ "U_UP375_MY15_Diesel_Tx" SG_ 948 Tire_Press_Telltale 1;
BA_ "U_CD43_MY16_Gas_Tx" SG_ 948 Tire_Press_Telltale 1;
BA_ "U_CD4_MY14_Diesel_Tx" SG_ 948 Tire_Press_Telltale 1;
BA_ "U_CD4_MY14_Gas_Tx" SG_ 948 Tire_Press_Telltale 1;
BA_ "U_CD4_MY14_Hev_Tx" SG_ 948 Tire_Press_Telltale 1;
BA_ "U_CD4_MY14_Phev_Tx" SG_ 948 Tire_Press_Telltale 1;
BA_ "CrossOver_InfoCAN" SG_ 948 TirePReset_D_Stat 1;
BA_ "GenSigSendType" SG_ 948 TirePReset_D_Stat 3;
BA_ "U_CD4_MY13_Diesel_Tx" SG_ 948 TirePReset_D_Stat 1;
BA_ "U_CD4_MY13_Gas_Tx" SG_ 948 TirePReset_D_Stat 1;
BA_ "U_CD4_MY13_Hev_Tx" SG_ 948 TirePReset_D_Stat 1;
BA_ "U_CD4_MY13_Phev_Tx" SG_ 948 TirePReset_D_Stat 1;
BA_ "U_CD42_MY14_Diesel_Tx" SG_ 948 TirePReset_D_Stat 1;
BA_ "U_CD42_MY14_Gas_Tx" SG_ 948 TirePReset_D_Stat 1;
BA_ "U_P552_MY15_Gas_Tx" SG_ 948 TirePReset_D_Stat 1;
BA_ "U_S550_MY15_Gas_Tx" SG_ 948 TirePReset_D_Stat 1;
BA_ "U_C489_MY14_Gas_Tx" SG_ 948 TirePReset_D_Stat 1;
BA_ "U_U502_MY15_Gas_Tx" SG_ 948 TirePReset_D_Stat 1;
BA_ "U_UP375_MY15_Gas_Tx" SG_ 948 TirePReset_D_Stat 1;
BA_ "U_UP375_MY15_Diesel_Tx" SG_ 948 TirePReset_D_Stat 1;
BA_ "U_CD43_MY16_Gas_Tx" SG_ 948 TirePReset_D_Stat 1;
BA_ "U_CD4_MY14_Diesel_Tx" SG_ 948 TirePReset_D_Stat 1;
BA_ "U_CD4_MY14_Gas_Tx" SG_ 948 TirePReset_D_Stat 1;
BA_ "U_CD4_MY14_Hev_Tx" SG_ 948 TirePReset_D_Stat 1;
BA_ "U_CD4_MY14_Phev_Tx" SG_ 948 TirePReset_D_Stat 1;
BA_ "U_S550_MY15_Gas_Rx" SG_ 1077 PtDrvMde_D_Rq 1;
BA_ "GenSigSendType" SG_ 1077 PtDrvMde_D_Rq 3;
BA_ "U_P552_MY15_Gas_Rx" SG_ 1077 TrlrBrkActCnnct_B_Actl_UB 1;
BA_ "GenSigSendType" SG_ 1077 TrlrBrkActCnnct_B_Actl 3;
BA_ "U_P552_MY15_Gas_Rx" SG_ 1077 TrlrBrkActCnnct_B_Actl 1;
BA_ "U_P552_MY15_Gas_Rx" SG_ 1077 PrkLckCtlEnbl_D_RqIpc_UB 1;
BA_ "U_S550_MY15_Gas_Rx" SG_ 1077 PrkLckCtlEnbl_D_RqIpc_UB 1;
BA_ "U_C489_MY14_Gas_Rx" SG_ 1077 PrkLckCtlEnbl_D_RqIpc_UB 1;
BA_ "U_CD43_MY16_Gas_Rx" SG_ 1077 PrkLckCtlEnbl_D_RqIpc_UB 1;
BA_ "U_CD4_MY14_Diesel_Rx" SG_ 1077 PrkLckCtlEnbl_D_RqIpc_UB 1;
BA_ "U_CD4_MY14_Gas_Rx" SG_ 1077 PrkLckCtlEnbl_D_RqIpc_UB 1;
BA_ "U_CD4_MY14_Hev_Rx" SG_ 1077 PrkLckCtlEnbl_D_RqIpc_UB 1;
BA_ "U_CD4_MY14_Phev_Rx" SG_ 1077 PrkLckCtlEnbl_D_RqIpc_UB 1;
BA_ "GenSigSendType" SG_ 1077 PrkLckCtlEnbl_D_RqIpc 3;
BA_ "U_P552_MY15_Gas_Rx" SG_ 1077 PrkLckCtlEnbl_D_RqIpc 1;
BA_ "U_S550_MY15_Gas_Rx" SG_ 1077 PrkLckCtlEnbl_D_RqIpc 1;
BA_ "U_C489_MY14_Gas_Rx" SG_ 1077 PrkLckCtlEnbl_D_RqIpc 1;
BA_ "U_CD43_MY16_Gas_Rx" SG_ 1077 PrkLckCtlEnbl_D_RqIpc 1;
BA_ "U_CD4_MY14_Diesel_Rx" SG_ 1077 PrkLckCtlEnbl_D_RqIpc 1;
BA_ "U_CD4_MY14_Gas_Rx" SG_ 1077 PrkLckCtlEnbl_D_RqIpc 1;
BA_ "U_CD4_MY14_Hev_Rx" SG_ 1077 PrkLckCtlEnbl_D_RqIpc 1;
BA_ "U_CD4_MY14_Phev_Rx" SG_ 1077 PrkLckCtlEnbl_D_RqIpc 1;
BA_ "GenSigSendType" SG_ 1077 AutoRgen_D_Rq 3;
BA_ "CrossOver_InfoCAN" SG_ 1077 StopStrtDrvMde_D_RqMnu 1;
BA_ "GenSigSendType" SG_ 1077 StopStrtDrvMde_D_RqMnu 3;
BA_ "U_CD4_MY13_Gas_Rx" SG_ 1077 StopStrtDrvMde_D_RqMnu 1;
BA_ "U_CD42_MY14_Gas_Rx" SG_ 1077 StopStrtDrvMde_D_RqMnu 1;
BA_ "U_P552_MY15_Gas_Rx" SG_ 1077 StopStrtDrvMde_D_RqMnu 1;
BA_ "U_U502_MY15_Gas_Rx" SG_ 1077 StopStrtDrvMde_D_RqMnu 1;
BA_ "U_CD43_MY16_Gas_Rx" SG_ 1077 StopStrtDrvMde_D_RqMnu 1;
BA_ "U_CD4_MY14_Gas_Rx" SG_ 1077 StopStrtDrvMde_D_RqMnu 1;
BA_ "WakeupSignal" SG_ 1077 PtWakeupActv1_B_Rq 1;
BA_ "GenSigSendType" SG_ 1077 PtWakeupActv1_B_Rq 3;
BA_ "U_CD4_MY13_Diesel_Rx" SG_ 1077 PtWakeupActv1_B_Rq 1;
BA_ "U_CD4_MY13_Gas_Rx" SG_ 1077 PtWakeupActv1_B_Rq 1;
BA_ "U_CD4_MY13_Hev_Rx" SG_ 1077 PtWakeupActv1_B_Rq 1;
BA_ "U_CD4_MY13_Phev_Rx" SG_ 1077 PtWakeupActv1_B_Rq 1;
BA_ "U_CD42_MY14_Diesel_Rx" SG_ 1077 PtWakeupActv1_B_Rq 1;
BA_ "U_CD42_MY14_Gas_Rx" SG_ 1077 PtWakeupActv1_B_Rq 1;
BA_ "U_P552_MY15_Gas_Rx" SG_ 1077 PtWakeupActv1_B_Rq 1;
BA_ "U_S550_MY15_Gas_Rx" SG_ 1077 PtWakeupActv1_B_Rq 1;
BA_ "U_C489_MY14_Gas_Rx" SG_ 1077 PtWakeupActv1_B_Rq 1;
BA_ "U_U502_MY15_Gas_Rx" SG_ 1077 PtWakeupActv1_B_Rq 1;
BA_ "U_UP375_MY15_Gas_Rx" SG_ 1077 PtWakeupActv1_B_Rq 1;
BA_ "U_UP375_MY15_Diesel_Rx" SG_ 1077 PtWakeupActv1_B_Rq 1;
BA_ "U_CD43_MY16_Gas_Rx" SG_ 1077 PtWakeupActv1_B_Rq 1;
BA_ "U_CD4_MY14_Diesel_Rx" SG_ 1077 PtWakeupActv1_B_Rq 1;
BA_ "U_CD4_MY14_Gas_Rx" SG_ 1077 PtWakeupActv1_B_Rq 1;
BA_ "U_CD4_MY14_Hev_Rx" SG_ 1077 PtWakeupActv1_B_Rq 1;
BA_ "U_CD4_MY14_Phev_Rx" SG_ 1077 PtWakeupActv1_B_Rq 1;
BA_ "U_CD4_MY13_Diesel_Rx" SG_ 1077 PtWakeupActv1_B_Rq_UB 1;
BA_ "U_CD4_MY13_Gas_Rx" SG_ 1077 PtWakeupActv1_B_Rq_UB 1;
BA_ "U_CD4_MY13_Hev_Rx" SG_ 1077 PtWakeupActv1_B_Rq_UB 1;
BA_ "U_CD4_MY13_Phev_Rx" SG_ 1077 PtWakeupActv1_B_Rq_UB 1;
BA_ "U_CD42_MY14_Diesel_Rx" SG_ 1077 PtWakeupActv1_B_Rq_UB 1;
BA_ "U_CD42_MY14_Gas_Rx" SG_ 1077 PtWakeupActv1_B_Rq_UB 1;
BA_ "U_P552_MY15_Gas_Rx" SG_ 1077 PtWakeupActv1_B_Rq_UB 1;
BA_ "U_S550_MY15_Gas_Rx" SG_ 1077 PtWakeupActv1_B_Rq_UB 1;
BA_ "U_C489_MY14_Gas_Rx" SG_ 1077 PtWakeupActv1_B_Rq_UB 1;
BA_ "U_U502_MY15_Gas_Rx" SG_ 1077 PtWakeupActv1_B_Rq_UB 1;
BA_ "U_UP375_MY15_Gas_Rx" SG_ 1077 PtWakeupActv1_B_Rq_UB 1;
BA_ "U_UP375_MY15_Diesel_Rx" SG_ 1077 PtWakeupActv1_B_Rq_UB 1;
BA_ "U_CD43_MY16_Gas_Rx" SG_ 1077 PtWakeupActv1_B_Rq_UB 1;
BA_ "U_CD4_MY14_Diesel_Rx" SG_ 1077 PtWakeupActv1_B_Rq_UB 1;
BA_ "U_CD4_MY14_Gas_Rx" SG_ 1077 PtWakeupActv1_B_Rq_UB 1;
BA_ "U_CD4_MY14_Hev_Rx" SG_ 1077 PtWakeupActv1_B_Rq_UB 1;
BA_ "U_CD4_MY14_Phev_Rx" SG_ 1077 PtWakeupActv1_B_Rq_UB 1;
BA_ "CrossOver_InfoCAN" SG_ 1077 PrkAidRear_D_RqDrv 1;
BA_ "GenSigSendType" SG_ 1077 PrkAidRear_D_RqDrv 3;
BA_ "U_CD4_MY13_Diesel_Rx" SG_ 1077 PrkAidRear_D_RqDrv 1;
BA_ "U_CD4_MY13_Gas_Rx" SG_ 1077 PrkAidRear_D_RqDrv 1;
BA_ "U_CD4_MY13_Hev_Rx" SG_ 1077 PrkAidRear_D_RqDrv 1;
BA_ "U_CD4_MY13_Phev_Rx" SG_ 1077 PrkAidRear_D_RqDrv 1;
BA_ "U_CD42_MY14_Diesel_Rx" SG_ 1077 PrkAidRear_D_RqDrv 1;
BA_ "U_CD42_MY14_Gas_Rx" SG_ 1077 PrkAidRear_D_RqDrv 1;
BA_ "U_P552_MY15_Gas_Rx" SG_ 1077 PrkAidRear_D_RqDrv 1;
BA_ "U_S550_MY15_Gas_Rx" SG_ 1077 PrkAidRear_D_RqDrv 1;
BA_ "U_C489_MY14_Gas_Rx" SG_ 1077 PrkAidRear_D_RqDrv 1;
BA_ "U_U502_MY15_Gas_Rx" SG_ 1077 PrkAidRear_D_RqDrv 1;
BA_ "U_UP375_MY15_Gas_Rx" SG_ 1077 PrkAidRear_D_RqDrv 1;
BA_ "U_UP375_MY15_Diesel_Rx" SG_ 1077 PrkAidRear_D_RqDrv 1;
BA_ "U_CD43_MY16_Gas_Rx" SG_ 1077 PrkAidRear_D_RqDrv 1;
BA_ "U_CD4_MY14_Diesel_Rx" SG_ 1077 PrkAidRear_D_RqDrv 1;
BA_ "U_CD4_MY14_Gas_Rx" SG_ 1077 PrkAidRear_D_RqDrv 1;
BA_ "U_CD4_MY14_Hev_Rx" SG_ 1077 PrkAidRear_D_RqDrv 1;
BA_ "U_CD4_MY14_Phev_Rx" SG_ 1077 PrkAidRear_D_RqDrv 1;
BA_ "CrossOver_InfoCAN" SG_ 1077 PrkAidFront_D_RqDrv 1;
BA_ "GenSigSendType" SG_ 1077 PrkAidFront_D_RqDrv 3;
BA_ "U_CD4_MY13_Diesel_Rx" SG_ 1077 PrkAidFront_D_RqDrv 1;
BA_ "U_CD4_MY13_Gas_Rx" SG_ 1077 PrkAidFront_D_RqDrv 1;
BA_ "U_CD4_MY13_Hev_Rx" SG_ 1077 PrkAidFront_D_RqDrv 1;
BA_ "U_CD4_MY13_Phev_Rx" SG_ 1077 PrkAidFront_D_RqDrv 1;
BA_ "U_CD42_MY14_Diesel_Rx" SG_ 1077 PrkAidFront_D_RqDrv 1;
BA_ "U_CD42_MY14_Gas_Rx" SG_ 1077 PrkAidFront_D_RqDrv 1;
BA_ "U_P552_MY15_Gas_Rx" SG_ 1077 PrkAidFront_D_RqDrv 1;
BA_ "U_C489_MY14_Gas_Rx" SG_ 1077 PrkAidFront_D_RqDrv 1;
BA_ "U_U502_MY15_Gas_Rx" SG_ 1077 PrkAidFront_D_RqDrv 1;
BA_ "U_UP375_MY15_Gas_Rx" SG_ 1077 PrkAidFront_D_RqDrv 1;
BA_ "U_UP375_MY15_Diesel_Rx" SG_ 1077 PrkAidFront_D_RqDrv 1;
BA_ "U_CD43_MY16_Gas_Rx" SG_ 1077 PrkAidFront_D_RqDrv 1;
BA_ "U_CD4_MY14_Diesel_Rx" SG_ 1077 PrkAidFront_D_RqDrv 1;
BA_ "U_CD4_MY14_Gas_Rx" SG_ 1077 PrkAidFront_D_RqDrv 1;
BA_ "U_CD4_MY14_Hev_Rx" SG_ 1077 PrkAidFront_D_RqDrv 1;
BA_ "U_CD4_MY14_Phev_Rx" SG_ 1077 PrkAidFront_D_RqDrv 1;
BA_ "U_CD4_MY13_Diesel_Rx" SG_ 1077 PrkAidRear_D_RqDrv_UB 1;
BA_ "U_CD4_MY13_Gas_Rx" SG_ 1077 PrkAidRear_D_RqDrv_UB 1;
BA_ "U_CD4_MY13_Hev_Rx" SG_ 1077 PrkAidRear_D_RqDrv_UB 1;
BA_ "U_CD4_MY13_Phev_Rx" SG_ 1077 PrkAidRear_D_RqDrv_UB 1;
BA_ "U_CD42_MY14_Diesel_Rx" SG_ 1077 PrkAidRear_D_RqDrv_UB 1;
BA_ "U_CD42_MY14_Gas_Rx" SG_ 1077 PrkAidRear_D_RqDrv_UB 1;
BA_ "U_P552_MY15_Gas_Rx" SG_ 1077 PrkAidRear_D_RqDrv_UB 1;
BA_ "U_S550_MY15_Gas_Rx" SG_ 1077 PrkAidRear_D_RqDrv_UB 1;
BA_ "U_C489_MY14_Gas_Rx" SG_ 1077 PrkAidRear_D_RqDrv_UB 1;
BA_ "U_U502_MY15_Gas_Rx" SG_ 1077 PrkAidRear_D_RqDrv_UB 1;
BA_ "U_UP375_MY15_Gas_Rx" SG_ 1077 PrkAidRear_D_RqDrv_UB 1;
BA_ "U_UP375_MY15_Diesel_Rx" SG_ 1077 PrkAidRear_D_RqDrv_UB 1;
BA_ "U_CD43_MY16_Gas_Rx" SG_ 1077 PrkAidRear_D_RqDrv_UB 1;
BA_ "U_CD4_MY14_Diesel_Rx" SG_ 1077 PrkAidRear_D_RqDrv_UB 1;
BA_ "U_CD4_MY14_Gas_Rx" SG_ 1077 PrkAidRear_D_RqDrv_UB 1;
BA_ "U_CD4_MY14_Hev_Rx" SG_ 1077 PrkAidRear_D_RqDrv_UB 1;
BA_ "U_CD4_MY14_Phev_Rx" SG_ 1077 PrkAidRear_D_RqDrv_UB 1;
BA_ "U_CD4_MY13_Diesel_Rx" SG_ 1077 PrkAidFront_D_RqDrv_UB 1;
BA_ "U_CD4_MY13_Gas_Rx" SG_ 1077 PrkAidFront_D_RqDrv_UB 1;
BA_ "U_CD4_MY13_Hev_Rx" SG_ 1077 PrkAidFront_D_RqDrv_UB 1;
BA_ "U_CD4_MY13_Phev_Rx" SG_ 1077 PrkAidFront_D_RqDrv_UB 1;
BA_ "U_CD42_MY14_Diesel_Rx" SG_ 1077 PrkAidFront_D_RqDrv_UB 1;
BA_ "U_CD42_MY14_Gas_Rx" SG_ 1077 PrkAidFront_D_RqDrv_UB 1;
BA_ "U_P552_MY15_Gas_Rx" SG_ 1077 PrkAidFront_D_RqDrv_UB 1;
BA_ "U_C489_MY14_Gas_Rx" SG_ 1077 PrkAidFront_D_RqDrv_UB 1;
BA_ "U_U502_MY15_Gas_Rx" SG_ 1077 PrkAidFront_D_RqDrv_UB 1;
BA_ "U_UP375_MY15_Gas_Rx" SG_ 1077 PrkAidFront_D_RqDrv_UB 1;
BA_ "U_UP375_MY15_Diesel_Rx" SG_ 1077 PrkAidFront_D_RqDrv_UB 1;
BA_ "U_CD43_MY16_Gas_Rx" SG_ 1077 PrkAidFront_D_RqDrv_UB 1;
BA_ "U_CD4_MY14_Diesel_Rx" SG_ 1077 PrkAidFront_D_RqDrv_UB 1;
BA_ "U_CD4_MY14_Gas_Rx" SG_ 1077 PrkAidFront_D_RqDrv_UB 1;
BA_ "U_CD4_MY14_Hev_Rx" SG_ 1077 PrkAidFront_D_RqDrv_UB 1;
BA_ "U_CD4_MY14_Phev_Rx" SG_ 1077 PrkAidFront_D_RqDrv_UB 1;
BA_ "U_CD4_MY13_Diesel_Rx" SG_ 1077 Multimedia_System_UB 1;
BA_ "U_CD4_MY13_Gas_Rx" SG_ 1077 Multimedia_System_UB 1;
BA_ "U_CD4_MY13_Hev_Rx" SG_ 1077 Multimedia_System_UB 1;
BA_ "U_CD4_MY13_Phev_Rx" SG_ 1077 Multimedia_System_UB 1;
BA_ "U_CD42_MY14_Diesel_Rx" SG_ 1077 Multimedia_System_UB 1;
BA_ "U_CD42_MY14_Gas_Rx" SG_ 1077 Multimedia_System_UB 1;
BA_ "U_P552_MY15_Gas_Rx" SG_ 1077 Multimedia_System_UB 1;
BA_ "U_S550_MY15_Gas_Rx" SG_ 1077 Multimedia_System_UB 1;
BA_ "U_C489_MY14_Gas_Rx" SG_ 1077 Multimedia_System_UB 1;
BA_ "U_U502_MY15_Gas_Rx" SG_ 1077 Multimedia_System_UB 1;
BA_ "U_UP375_MY15_Gas_Rx" SG_ 1077 Multimedia_System_UB 1;
BA_ "U_UP375_MY15_Diesel_Rx" SG_ 1077 Multimedia_System_UB 1;
BA_ "U_CD43_MY16_Gas_Rx" SG_ 1077 Multimedia_System_UB 1;
BA_ "U_CD4_MY14_Diesel_Rx" SG_ 1077 Multimedia_System_UB 1;
BA_ "U_CD4_MY14_Gas_Rx" SG_ 1077 Multimedia_System_UB 1;
BA_ "U_CD4_MY14_Hev_Rx" SG_ 1077 Multimedia_System_UB 1;
BA_ "U_CD4_MY14_Phev_Rx" SG_ 1077 Multimedia_System_UB 1;
BA_ "WakeupSignal" SG_ 1077 Multimedia_System 1;
BA_ "CrossOver_InfoCAN" SG_ 1077 Multimedia_System 1;
BA_ "GenSigSendType" SG_ 1077 Multimedia_System 3;
BA_ "U_CD4_MY13_Diesel_Rx" SG_ 1077 Multimedia_System 1;
BA_ "U_CD4_MY13_Gas_Rx" SG_ 1077 Multimedia_System 1;
BA_ "U_CD4_MY13_Hev_Rx" SG_ 1077 Multimedia_System 1;
BA_ "U_CD4_MY13_Phev_Rx" SG_ 1077 Multimedia_System 1;
BA_ "U_CD42_MY14_Diesel_Rx" SG_ 1077 Multimedia_System 1;
BA_ "U_CD42_MY14_Gas_Rx" SG_ 1077 Multimedia_System 1;
BA_ "U_P552_MY15_Gas_Rx" SG_ 1077 Multimedia_System 1;
BA_ "U_S550_MY15_Gas_Rx" SG_ 1077 Multimedia_System 1;
BA_ "U_C489_MY14_Gas_Rx" SG_ 1077 Multimedia_System 1;
BA_ "U_U502_MY15_Gas_Rx" SG_ 1077 Multimedia_System 1;
BA_ "U_UP375_MY15_Gas_Rx" SG_ 1077 Multimedia_System 1;
BA_ "U_UP375_MY15_Diesel_Rx" SG_ 1077 Multimedia_System 1;
BA_ "U_CD43_MY16_Gas_Rx" SG_ 1077 Multimedia_System 1;
BA_ "U_CD4_MY14_Diesel_Rx" SG_ 1077 Multimedia_System 1;
BA_ "U_CD4_MY14_Gas_Rx" SG_ 1077 Multimedia_System 1;
BA_ "U_CD4_MY14_Hev_Rx" SG_ 1077 Multimedia_System 1;
BA_ "U_CD4_MY14_Phev_Rx" SG_ 1077 Multimedia_System 1;
BA_ "U_CD4_MY13_Diesel_Rx" SG_ 1077 Remote_Start_Req_UB 1;
BA_ "U_CD4_MY13_Gas_Rx" SG_ 1077 Remote_Start_Req_UB 1;
BA_ "U_CD4_MY13_Hev_Rx" SG_ 1077 Remote_Start_Req_UB 1;
BA_ "U_CD4_MY13_Phev_Rx" SG_ 1077 Remote_Start_Req_UB 1;
BA_ "U_CD42_MY14_Diesel_Rx" SG_ 1077 Remote_Start_Req_UB 1;
BA_ "U_CD42_MY14_Gas_Rx" SG_ 1077 Remote_Start_Req_UB 1;
BA_ "U_P552_MY15_Gas_Rx" SG_ 1077 Remote_Start_Req_UB 1;
BA_ "U_S550_MY15_Gas_Rx" SG_ 1077 Remote_Start_Req_UB 1;
BA_ "U_C489_MY14_Gas_Rx" SG_ 1077 Remote_Start_Req_UB 1;
BA_ "U_U502_MY15_Gas_Rx" SG_ 1077 Remote_Start_Req_UB 1;
BA_ "U_UP375_MY15_Gas_Rx" SG_ 1077 Remote_Start_Req_UB 1;
BA_ "U_UP375_MY15_Diesel_Rx" SG_ 1077 Remote_Start_Req_UB 1;
BA_ "U_CD43_MY16_Gas_Rx" SG_ 1077 Remote_Start_Req_UB 1;
BA_ "U_CD4_MY14_Diesel_Rx" SG_ 1077 Remote_Start_Req_UB 1;
BA_ "U_CD4_MY14_Gas_Rx" SG_ 1077 Remote_Start_Req_UB 1;
BA_ "U_CD4_MY14_Hev_Rx" SG_ 1077 Remote_Start_Req_UB 1;
BA_ "U_CD4_MY14_Phev_Rx" SG_ 1077 Remote_Start_Req_UB 1;
BA_ "WakeupSignal" SG_ 1077 Remote_Start_Req 1;
BA_ "GenSigSendType" SG_ 1077 Remote_Start_Req 3;
BA_ "U_CD4_MY13_Diesel_Rx" SG_ 1077 Remote_Start_Req 1;
BA_ "U_CD4_MY13_Gas_Rx" SG_ 1077 Remote_Start_Req 1;
BA_ "U_CD4_MY13_Hev_Rx" SG_ 1077 Remote_Start_Req 1;
BA_ "U_CD4_MY13_Phev_Rx" SG_ 1077 Remote_Start_Req 1;
BA_ "U_CD42_MY14_Diesel_Rx" SG_ 1077 Remote_Start_Req 1;
BA_ "U_CD42_MY14_Gas_Rx" SG_ 1077 Remote_Start_Req 1;
BA_ "U_P552_MY15_Gas_Rx" SG_ 1077 Remote_Start_Req 1;
BA_ "U_S550_MY15_Gas_Rx" SG_ 1077 Remote_Start_Req 1;
BA_ "U_C489_MY14_Gas_Rx" SG_ 1077 Remote_Start_Req 1;
BA_ "U_U502_MY15_Gas_Rx" SG_ 1077 Remote_Start_Req 1;
BA_ "U_UP375_MY15_Gas_Rx" SG_ 1077 Remote_Start_Req 1;
BA_ "U_UP375_MY15_Diesel_Rx" SG_ 1077 Remote_Start_Req 1;
BA_ "U_CD43_MY16_Gas_Rx" SG_ 1077 Remote_Start_Req 1;
BA_ "U_CD4_MY14_Diesel_Rx" SG_ 1077 Remote_Start_Req 1;
BA_ "U_CD4_MY14_Gas_Rx" SG_ 1077 Remote_Start_Req 1;
BA_ "U_CD4_MY14_Hev_Rx" SG_ 1077 Remote_Start_Req 1;
BA_ "U_CD4_MY14_Phev_Rx" SG_ 1077 Remote_Start_Req 1;
BA_ "U_CD4_MY13_Diesel_Rx" SG_ 1077 TurnLampTrlrRr_B_Stat_UB 1;
BA_ "U_CD4_MY13_Gas_Rx" SG_ 1077 TurnLampTrlrRr_B_Stat_UB 1;
BA_ "U_CD4_MY13_Hev_Rx" SG_ 1077 TurnLampTrlrRr_B_Stat_UB 1;
BA_ "U_CD4_MY13_Phev_Rx" SG_ 1077 TurnLampTrlrRr_B_Stat_UB 1;
BA_ "U_CD42_MY14_Diesel_Rx" SG_ 1077 TurnLampTrlrRr_B_Stat_UB 1;
BA_ "U_CD42_MY14_Gas_Rx" SG_ 1077 TurnLampTrlrRr_B_Stat_UB 1;
BA_ "U_P552_MY15_Gas_Rx" SG_ 1077 TurnLampTrlrRr_B_Stat_UB 1;
BA_ "U_S550_MY15_Gas_Rx" SG_ 1077 TurnLampTrlrRr_B_Stat_UB 1;
BA_ "U_C489_MY14_Gas_Rx" SG_ 1077 TurnLampTrlrRr_B_Stat_UB 1;
BA_ "U_U502_MY15_Gas_Rx" SG_ 1077 TurnLampTrlrRr_B_Stat_UB 1;
BA_ "U_UP375_MY15_Gas_Rx" SG_ 1077 TurnLampTrlrRr_B_Stat_UB 1;
BA_ "U_UP375_MY15_Diesel_Rx" SG_ 1077 TurnLampTrlrRr_B_Stat_UB 1;
BA_ "U_CD43_MY16_Gas_Rx" SG_ 1077 TurnLampTrlrRr_B_Stat_UB 1;
BA_ "U_CD4_MY14_Diesel_Rx" SG_ 1077 TurnLampTrlrRr_B_Stat_UB 1;
BA_ "U_CD4_MY14_Gas_Rx" SG_ 1077 TurnLampTrlrRr_B_Stat_UB 1;
BA_ "U_CD4_MY14_Hev_Rx" SG_ 1077 TurnLampTrlrRr_B_Stat_UB 1;
BA_ "U_CD4_MY14_Phev_Rx" SG_ 1077 TurnLampTrlrRr_B_Stat_UB 1;
BA_ "U_CD4_MY13_Diesel_Rx" SG_ 1077 DistanceBarSetting_UB 1;
BA_ "U_CD4_MY13_Gas_Rx" SG_ 1077 DistanceBarSetting_UB 1;
BA_ "U_CD4_MY13_Hev_Rx" SG_ 1077 DistanceBarSetting_UB 1;
BA_ "U_CD4_MY13_Phev_Rx" SG_ 1077 DistanceBarSetting_UB 1;
BA_ "U_CD42_MY14_Diesel_Rx" SG_ 1077 DistanceBarSetting_UB 1;
BA_ "U_CD42_MY14_Gas_Rx" SG_ 1077 DistanceBarSetting_UB 1;
BA_ "U_P552_MY15_Gas_Rx" SG_ 1077 DistanceBarSetting_UB 1;
BA_ "U_S550_MY15_Gas_Rx" SG_ 1077 DistanceBarSetting_UB 1;
BA_ "U_C489_MY14_Gas_Rx" SG_ 1077 DistanceBarSetting_UB 1;
BA_ "U_U502_MY15_Gas_Rx" SG_ 1077 DistanceBarSetting_UB 1;
BA_ "U_UP375_MY15_Gas_Rx" SG_ 1077 DistanceBarSetting_UB 1;
BA_ "U_UP375_MY15_Diesel_Rx" SG_ 1077 DistanceBarSetting_UB 1;
BA_ "U_CD43_MY16_Gas_Rx" SG_ 1077 DistanceBarSetting_UB 1;
BA_ "U_CD4_MY14_Diesel_Rx" SG_ 1077 DistanceBarSetting_UB 1;
BA_ "U_CD4_MY14_Gas_Rx" SG_ 1077 DistanceBarSetting_UB 1;
BA_ "U_CD4_MY14_Hev_Rx" SG_ 1077 DistanceBarSetting_UB 1;
BA_ "U_CD4_MY14_Phev_Rx" SG_ 1077 DistanceBarSetting_UB 1;
BA_ "U_CD4_MY13_Diesel_Rx" SG_ 1077 CamraZoomMan_D_Rq_UB 1;
BA_ "U_CD4_MY13_Gas_Rx" SG_ 1077 CamraZoomMan_D_Rq_UB 1;
BA_ "U_CD4_MY13_Hev_Rx" SG_ 1077 CamraZoomMan_D_Rq_UB 1;
BA_ "U_CD4_MY13_Phev_Rx" SG_ 1077 CamraZoomMan_D_Rq_UB 1;
BA_ "U_CD42_MY14_Diesel_Rx" SG_ 1077 CamraZoomMan_D_Rq_UB 1;
BA_ "U_CD42_MY14_Gas_Rx" SG_ 1077 CamraZoomMan_D_Rq_UB 1;
BA_ "U_P552_MY15_Gas_Rx" SG_ 1077 CamraZoomMan_D_Rq_UB 1;
BA_ "U_S550_MY15_Gas_Rx" SG_ 1077 CamraZoomMan_D_Rq_UB 1;
BA_ "U_C489_MY14_Gas_Rx" SG_ 1077 CamraZoomMan_D_Rq_UB 1;
BA_ "U_U502_MY15_Gas_Rx" SG_ 1077 CamraZoomMan_D_Rq_UB 1;
BA_ "U_UP375_MY15_Gas_Rx" SG_ 1077 CamraZoomMan_D_Rq_UB 1;
BA_ "U_UP375_MY15_Diesel_Rx" SG_ 1077 CamraZoomMan_D_Rq_UB 1;
BA_ "U_CD43_MY16_Gas_Rx" SG_ 1077 CamraZoomMan_D_Rq_UB 1;
BA_ "U_CD4_MY14_Diesel_Rx" SG_ 1077 CamraZoomMan_D_Rq_UB 1;
BA_ "U_CD4_MY14_Gas_Rx" SG_ 1077 CamraZoomMan_D_Rq_UB 1;
BA_ "U_CD4_MY14_Hev_Rx" SG_ 1077 CamraZoomMan_D_Rq_UB 1;
BA_ "U_CD4_MY14_Phev_Rx" SG_ 1077 CamraZoomMan_D_Rq_UB 1;
BA_ "U_CD4_MY13_Diesel_Rx" SG_ 1077 CamraOvrlStat_D_Rq_UB 1;
BA_ "U_CD4_MY13_Gas_Rx" SG_ 1077 CamraOvrlStat_D_Rq_UB 1;
BA_ "U_CD4_MY13_Hev_Rx" SG_ 1077 CamraOvrlStat_D_Rq_UB 1;
BA_ "U_CD4_MY13_Phev_Rx" SG_ 1077 CamraOvrlStat_D_Rq_UB 1;
BA_ "U_CD42_MY14_Diesel_Rx" SG_ 1077 CamraOvrlStat_D_Rq_UB 1;
BA_ "U_CD42_MY14_Gas_Rx" SG_ 1077 CamraOvrlStat_D_Rq_UB 1;
BA_ "U_P552_MY15_Gas_Rx" SG_ 1077 CamraOvrlStat_D_Rq_UB 1;
BA_ "U_S550_MY15_Gas_Rx" SG_ 1077 CamraOvrlStat_D_Rq_UB 1;
BA_ "U_C489_MY14_Gas_Rx" SG_ 1077 CamraOvrlStat_D_Rq_UB 1;
BA_ "U_U502_MY15_Gas_Rx" SG_ 1077 CamraOvrlStat_D_Rq_UB 1;
BA_ "U_UP375_MY15_Gas_Rx" SG_ 1077 CamraOvrlStat_D_Rq_UB 1;
BA_ "U_UP375_MY15_Diesel_Rx" SG_ 1077 CamraOvrlStat_D_Rq_UB 1;
BA_ "U_CD43_MY16_Gas_Rx" SG_ 1077 CamraOvrlStat_D_Rq_UB 1;
BA_ "U_CD4_MY14_Diesel_Rx" SG_ 1077 CamraOvrlStat_D_Rq_UB 1;
BA_ "U_CD4_MY14_Gas_Rx" SG_ 1077 CamraOvrlStat_D_Rq_UB 1;
BA_ "U_CD4_MY14_Hev_Rx" SG_ 1077 CamraOvrlStat_D_Rq_UB 1;
BA_ "U_CD4_MY14_Phev_Rx" SG_ 1077 CamraOvrlStat_D_Rq_UB 1;
BA_ "U_CD4_MY13_Diesel_Rx" SG_ 1077 CamraOvrlDyn_D_Rq_UB 1;
BA_ "U_CD4_MY13_Gas_Rx" SG_ 1077 CamraOvrlDyn_D_Rq_UB 1;
BA_ "U_CD4_MY13_Hev_Rx" SG_ 1077 CamraOvrlDyn_D_Rq_UB 1;
BA_ "U_CD4_MY13_Phev_Rx" SG_ 1077 CamraOvrlDyn_D_Rq_UB 1;
BA_ "U_CD42_MY14_Diesel_Rx" SG_ 1077 CamraOvrlDyn_D_Rq_UB 1;
BA_ "U_CD42_MY14_Gas_Rx" SG_ 1077 CamraOvrlDyn_D_Rq_UB 1;
BA_ "U_P552_MY15_Gas_Rx" SG_ 1077 CamraOvrlDyn_D_Rq_UB 1;
BA_ "U_S550_MY15_Gas_Rx" SG_ 1077 CamraOvrlDyn_D_Rq_UB 1;
BA_ "U_C489_MY14_Gas_Rx" SG_ 1077 CamraOvrlDyn_D_Rq_UB 1;
BA_ "U_U502_MY15_Gas_Rx" SG_ 1077 CamraOvrlDyn_D_Rq_UB 1;
BA_ "U_UP375_MY15_Gas_Rx" SG_ 1077 CamraOvrlDyn_D_Rq_UB 1;
BA_ "U_UP375_MY15_Diesel_Rx" SG_ 1077 CamraOvrlDyn_D_Rq_UB 1;
BA_ "U_CD43_MY16_Gas_Rx" SG_ 1077 CamraOvrlDyn_D_Rq_UB 1;
BA_ "U_CD4_MY14_Diesel_Rx" SG_ 1077 CamraOvrlDyn_D_Rq_UB 1;
BA_ "U_CD4_MY14_Gas_Rx" SG_ 1077 CamraOvrlDyn_D_Rq_UB 1;
BA_ "U_CD4_MY14_Hev_Rx" SG_ 1077 CamraOvrlDyn_D_Rq_UB 1;
BA_ "U_CD4_MY14_Phev_Rx" SG_ 1077 CamraOvrlDyn_D_Rq_UB 1;
BA_ "U_CD4_MY13_Diesel_Rx" SG_ 1077 CamAutoTowbarZoom_UB 1;
BA_ "U_CD4_MY13_Gas_Rx" SG_ 1077 CamAutoTowbarZoom_UB 1;
BA_ "U_CD4_MY13_Hev_Rx" SG_ 1077 CamAutoTowbarZoom_UB 1;
BA_ "U_CD4_MY13_Phev_Rx" SG_ 1077 CamAutoTowbarZoom_UB 1;
BA_ "U_CD42_MY14_Diesel_Rx" SG_ 1077 CamAutoTowbarZoom_UB 1;
BA_ "U_CD42_MY14_Gas_Rx" SG_ 1077 CamAutoTowbarZoom_UB 1;
BA_ "U_P552_MY15_Gas_Rx" SG_ 1077 CamAutoTowbarZoom_UB 1;
BA_ "U_S550_MY15_Gas_Rx" SG_ 1077 CamAutoTowbarZoom_UB 1;
BA_ "U_C489_MY14_Gas_Rx" SG_ 1077 CamAutoTowbarZoom_UB 1;
BA_ "U_U502_MY15_Gas_Rx" SG_ 1077 CamAutoTowbarZoom_UB 1;
BA_ "U_UP375_MY15_Gas_Rx" SG_ 1077 CamAutoTowbarZoom_UB 1;
BA_ "U_UP375_MY15_Diesel_Rx" SG_ 1077 CamAutoTowbarZoom_UB 1;
BA_ "U_CD43_MY16_Gas_Rx" SG_ 1077 CamAutoTowbarZoom_UB 1;
BA_ "U_CD4_MY14_Diesel_Rx" SG_ 1077 CamAutoTowbarZoom_UB 1;
BA_ "U_CD4_MY14_Gas_Rx" SG_ 1077 CamAutoTowbarZoom_UB 1;
BA_ "U_CD4_MY14_Hev_Rx" SG_ 1077 CamAutoTowbarZoom_UB 1;
BA_ "U_CD4_MY14_Phev_Rx" SG_ 1077 CamAutoTowbarZoom_UB 1;
BA_ "CrossOver_InfoCAN" SG_ 1077 DistanceBarSetting 1;
BA_ "CrossOver_LIN" SG_ 1077 DistanceBarSetting 1;
BA_ "GenSigSendType" SG_ 1077 DistanceBarSetting 3;
BA_ "U_CD4_MY13_Diesel_Rx" SG_ 1077 DistanceBarSetting 1;
BA_ "U_CD4_MY13_Gas_Rx" SG_ 1077 DistanceBarSetting 1;
BA_ "U_CD4_MY13_Hev_Rx" SG_ 1077 DistanceBarSetting 1;
BA_ "U_CD4_MY13_Phev_Rx" SG_ 1077 DistanceBarSetting 1;
BA_ "U_CD42_MY14_Diesel_Rx" SG_ 1077 DistanceBarSetting 1;
BA_ "U_CD42_MY14_Gas_Rx" SG_ 1077 DistanceBarSetting 1;
BA_ "U_P552_MY15_Gas_Rx" SG_ 1077 DistanceBarSetting 1;
BA_ "U_S550_MY15_Gas_Rx" SG_ 1077 DistanceBarSetting 1;
BA_ "U_C489_MY14_Gas_Rx" SG_ 1077 DistanceBarSetting 1;
BA_ "U_U502_MY15_Gas_Rx" SG_ 1077 DistanceBarSetting 1;
BA_ "U_UP375_MY15_Gas_Rx" SG_ 1077 DistanceBarSetting 1;
BA_ "U_UP375_MY15_Diesel_Rx" SG_ 1077 DistanceBarSetting 1;
BA_ "U_CD43_MY16_Gas_Rx" SG_ 1077 DistanceBarSetting 1;
BA_ "U_CD4_MY14_Diesel_Rx" SG_ 1077 DistanceBarSetting 1;
BA_ "U_CD4_MY14_Gas_Rx" SG_ 1077 DistanceBarSetting 1;
BA_ "U_CD4_MY14_Hev_Rx" SG_ 1077 DistanceBarSetting 1;
BA_ "U_CD4_MY14_Phev_Rx" SG_ 1077 DistanceBarSetting 1;
BA_ "CrossOver_InfoCAN" SG_ 1077 CamraZoomMan_D_Rq 1;
BA_ "CrossOver_LIN" SG_ 1077 CamraZoomMan_D_Rq 1;
BA_ "GenSigSendType" SG_ 1077 CamraZoomMan_D_Rq 3;
BA_ "U_CD4_MY13_Diesel_Rx" SG_ 1077 CamraZoomMan_D_Rq 1;
BA_ "U_CD4_MY13_Gas_Rx" SG_ 1077 CamraZoomMan_D_Rq 1;
BA_ "U_CD4_MY13_Hev_Rx" SG_ 1077 CamraZoomMan_D_Rq 1;
BA_ "U_CD4_MY13_Phev_Rx" SG_ 1077 CamraZoomMan_D_Rq 1;
BA_ "U_CD42_MY14_Diesel_Rx" SG_ 1077 CamraZoomMan_D_Rq 1;
BA_ "U_CD42_MY14_Gas_Rx" SG_ 1077 CamraZoomMan_D_Rq 1;
BA_ "U_P552_MY15_Gas_Rx" SG_ 1077 CamraZoomMan_D_Rq 1;
BA_ "U_S550_MY15_Gas_Rx" SG_ 1077 CamraZoomMan_D_Rq 1;
BA_ "U_C489_MY14_Gas_Rx" SG_ 1077 CamraZoomMan_D_Rq 1;
BA_ "U_U502_MY15_Gas_Rx" SG_ 1077 CamraZoomMan_D_Rq 1;
BA_ "U_UP375_MY15_Gas_Rx" SG_ 1077 CamraZoomMan_D_Rq 1;
BA_ "U_UP375_MY15_Diesel_Rx" SG_ 1077 CamraZoomMan_D_Rq 1;
BA_ "U_CD43_MY16_Gas_Rx" SG_ 1077 CamraZoomMan_D_Rq 1;
BA_ "U_CD4_MY14_Diesel_Rx" SG_ 1077 CamraZoomMan_D_Rq 1;
BA_ "U_CD4_MY14_Gas_Rx" SG_ 1077 CamraZoomMan_D_Rq 1;
BA_ "U_CD4_MY14_Hev_Rx" SG_ 1077 CamraZoomMan_D_Rq 1;
BA_ "U_CD4_MY14_Phev_Rx" SG_ 1077 CamraZoomMan_D_Rq 1;
BA_ "CrossOver_InfoCAN" SG_ 1077 CamraOvrlStat_D_Rq 1;
BA_ "CrossOver_LIN" SG_ 1077 CamraOvrlStat_D_Rq 1;
BA_ "GenSigSendType" SG_ 1077 CamraOvrlStat_D_Rq 3;
BA_ "U_CD4_MY13_Diesel_Rx" SG_ 1077 CamraOvrlStat_D_Rq 1;
BA_ "U_CD4_MY13_Gas_Rx" SG_ 1077 CamraOvrlStat_D_Rq 1;
BA_ "U_CD4_MY13_Hev_Rx" SG_ 1077 CamraOvrlStat_D_Rq 1;
BA_ "U_CD4_MY13_Phev_Rx" SG_ 1077 CamraOvrlStat_D_Rq 1;
BA_ "U_CD42_MY14_Diesel_Rx" SG_ 1077 CamraOvrlStat_D_Rq 1;
BA_ "U_CD42_MY14_Gas_Rx" SG_ 1077 CamraOvrlStat_D_Rq 1;
BA_ "U_P552_MY15_Gas_Rx" SG_ 1077 CamraOvrlStat_D_Rq 1;
BA_ "U_S550_MY15_Gas_Rx" SG_ 1077 CamraOvrlStat_D_Rq 1;
BA_ "U_C489_MY14_Gas_Rx" SG_ 1077 CamraOvrlStat_D_Rq 1;
BA_ "U_U502_MY15_Gas_Rx" SG_ 1077 CamraOvrlStat_D_Rq 1;
BA_ "U_UP375_MY15_Gas_Rx" SG_ 1077 CamraOvrlStat_D_Rq 1;
BA_ "U_UP375_MY15_Diesel_Rx" SG_ 1077 CamraOvrlStat_D_Rq 1;
BA_ "U_CD43_MY16_Gas_Rx" SG_ 1077 CamraOvrlStat_D_Rq 1;
BA_ "U_CD4_MY14_Diesel_Rx" SG_ 1077 CamraOvrlStat_D_Rq 1;
BA_ "U_CD4_MY14_Gas_Rx" SG_ 1077 CamraOvrlStat_D_Rq 1;
BA_ "U_CD4_MY14_Hev_Rx" SG_ 1077 CamraOvrlStat_D_Rq 1;
BA_ "U_CD4_MY14_Phev_Rx" SG_ 1077 CamraOvrlStat_D_Rq 1;
BA_ "CrossOver_InfoCAN" SG_ 1077 CamraOvrlDyn_D_Rq 1;
BA_ "CrossOver_LIN" SG_ 1077 CamraOvrlDyn_D_Rq 1;
BA_ "GenSigSendType" SG_ 1077 CamraOvrlDyn_D_Rq 3;
BA_ "U_CD4_MY13_Diesel_Rx" SG_ 1077 CamraOvrlDyn_D_Rq 1;
BA_ "U_CD4_MY13_Gas_Rx" SG_ 1077 CamraOvrlDyn_D_Rq 1;
BA_ "U_CD4_MY13_Hev_Rx" SG_ 1077 CamraOvrlDyn_D_Rq 1;
BA_ "U_CD4_MY13_Phev_Rx" SG_ 1077 CamraOvrlDyn_D_Rq 1;
BA_ "U_CD42_MY14_Diesel_Rx" SG_ 1077 CamraOvrlDyn_D_Rq 1;
BA_ "U_CD42_MY14_Gas_Rx" SG_ 1077 CamraOvrlDyn_D_Rq 1;
BA_ "U_P552_MY15_Gas_Rx" SG_ 1077 CamraOvrlDyn_D_Rq 1;
BA_ "U_S550_MY15_Gas_Rx" SG_ 1077 CamraOvrlDyn_D_Rq 1;
BA_ "U_C489_MY14_Gas_Rx" SG_ 1077 CamraOvrlDyn_D_Rq 1;
BA_ "U_U502_MY15_Gas_Rx" SG_ 1077 CamraOvrlDyn_D_Rq 1;
BA_ "U_UP375_MY15_Gas_Rx" SG_ 1077 CamraOvrlDyn_D_Rq 1;
BA_ "U_UP375_MY15_Diesel_Rx" SG_ 1077 CamraOvrlDyn_D_Rq 1;
BA_ "U_CD43_MY16_Gas_Rx" SG_ 1077 CamraOvrlDyn_D_Rq 1;
BA_ "U_CD4_MY14_Diesel_Rx" SG_ 1077 CamraOvrlDyn_D_Rq 1;
BA_ "U_CD4_MY14_Gas_Rx" SG_ 1077 CamraOvrlDyn_D_Rq 1;
BA_ "U_CD4_MY14_Hev_Rx" SG_ 1077 CamraOvrlDyn_D_Rq 1;
BA_ "U_CD4_MY14_Phev_Rx" SG_ 1077 CamraOvrlDyn_D_Rq 1;
BA_ "CrossOver_InfoCAN" SG_ 1077 CamAutoTowbarZoom 1;
BA_ "CrossOver_LIN" SG_ 1077 CamAutoTowbarZoom 1;
BA_ "GenSigSendType" SG_ 1077 CamAutoTowbarZoom 3;
BA_ "U_CD4_MY13_Diesel_Rx" SG_ 1077 CamAutoTowbarZoom 1;
BA_ "U_CD4_MY13_Gas_Rx" SG_ 1077 CamAutoTowbarZoom 1;
BA_ "U_CD4_MY13_Hev_Rx" SG_ 1077 CamAutoTowbarZoom 1;
BA_ "U_CD4_MY13_Phev_Rx" SG_ 1077 CamAutoTowbarZoom 1;
BA_ "U_CD42_MY14_Diesel_Rx" SG_ 1077 CamAutoTowbarZoom 1;
BA_ "U_CD42_MY14_Gas_Rx" SG_ 1077 CamAutoTowbarZoom 1;
BA_ "U_P552_MY15_Gas_Rx" SG_ 1077 CamAutoTowbarZoom 1;
BA_ "U_S550_MY15_Gas_Rx" SG_ 1077 CamAutoTowbarZoom 1;
BA_ "U_C489_MY14_Gas_Rx" SG_ 1077 CamAutoTowbarZoom 1;
BA_ "U_U502_MY15_Gas_Rx" SG_ 1077 CamAutoTowbarZoom 1;
BA_ "U_UP375_MY15_Gas_Rx" SG_ 1077 CamAutoTowbarZoom 1;
BA_ "U_UP375_MY15_Diesel_Rx" SG_ 1077 CamAutoTowbarZoom 1;
BA_ "U_CD43_MY16_Gas_Rx" SG_ 1077 CamAutoTowbarZoom 1;
BA_ "U_CD4_MY14_Diesel_Rx" SG_ 1077 CamAutoTowbarZoom 1;
BA_ "U_CD4_MY14_Gas_Rx" SG_ 1077 CamAutoTowbarZoom 1;
BA_ "U_CD4_MY14_Hev_Rx" SG_ 1077 CamAutoTowbarZoom 1;
BA_ "U_CD4_MY14_Phev_Rx" SG_ 1077 CamAutoTowbarZoom 1;
BA_ "CrossOver_InfoCAN" SG_ 1077 CcdMsgTxt_D_RqDsply 1;
BA_ "GenSigSendType" SG_ 1077 CcdMsgTxt_D_RqDsply 3;
BA_ "U_CD4_MY13_Diesel_Rx" SG_ 1077 PwLftgtIntSw_B_Stat_UB 1;
BA_ "U_CD4_MY13_Gas_Rx" SG_ 1077 PwLftgtIntSw_B_Stat_UB 1;
BA_ "U_CD4_MY13_Hev_Rx" SG_ 1077 PwLftgtIntSw_B_Stat_UB 1;
BA_ "U_CD4_MY13_Phev_Rx" SG_ 1077 PwLftgtIntSw_B_Stat_UB 1;
BA_ "U_CD42_MY14_Diesel_Rx" SG_ 1077 PwLftgtIntSw_B_Stat_UB 1;
BA_ "U_CD42_MY14_Gas_Rx" SG_ 1077 PwLftgtIntSw_B_Stat_UB 1;
BA_ "U_P552_MY15_Gas_Rx" SG_ 1077 PwLftgtIntSw_B_Stat_UB 1;
BA_ "U_S550_MY15_Gas_Rx" SG_ 1077 PwLftgtIntSw_B_Stat_UB 1;
BA_ "U_C489_MY14_Gas_Rx" SG_ 1077 PwLftgtIntSw_B_Stat_UB 1;
BA_ "U_U502_MY15_Gas_Rx" SG_ 1077 PwLftgtIntSw_B_Stat_UB 1;
BA_ "U_UP375_MY15_Gas_Rx" SG_ 1077 PwLftgtIntSw_B_Stat_UB 1;
BA_ "U_UP375_MY15_Diesel_Rx" SG_ 1077 PwLftgtIntSw_B_Stat_UB 1;
BA_ "U_CD43_MY16_Gas_Rx" SG_ 1077 PwLftgtIntSw_B_Stat_UB 1;
BA_ "U_CD4_MY14_Diesel_Rx" SG_ 1077 PwLftgtIntSw_B_Stat_UB 1;
BA_ "U_CD4_MY14_Gas_Rx" SG_ 1077 PwLftgtIntSw_B_Stat_UB 1;
BA_ "U_CD4_MY14_Hev_Rx" SG_ 1077 PwLftgtIntSw_B_Stat_UB 1;
BA_ "U_CD4_MY14_Phev_Rx" SG_ 1077 PwLftgtIntSw_B_Stat_UB 1;
BA_ "WakeupSignal" SG_ 1077 PwLftgtIntSw_B_Stat 1;
BA_ "GenSigSendType" SG_ 1077 PwLftgtIntSw_B_Stat 3;
BA_ "U_CD4_MY13_Diesel_Rx" SG_ 1077 PwLftgtIntSw_B_Stat 1;
BA_ "U_CD4_MY13_Gas_Rx" SG_ 1077 PwLftgtIntSw_B_Stat 1;
BA_ "U_CD4_MY13_Hev_Rx" SG_ 1077 PwLftgtIntSw_B_Stat 1;
BA_ "U_CD4_MY13_Phev_Rx" SG_ 1077 PwLftgtIntSw_B_Stat 1;
BA_ "U_CD42_MY14_Diesel_Rx" SG_ 1077 PwLftgtIntSw_B_Stat 1;
BA_ "U_CD42_MY14_Gas_Rx" SG_ 1077 PwLftgtIntSw_B_Stat 1;
BA_ "U_P552_MY15_Gas_Rx" SG_ 1077 PwLftgtIntSw_B_Stat 1;
BA_ "U_S550_MY15_Gas_Rx" SG_ 1077 PwLftgtIntSw_B_Stat 1;
BA_ "U_C489_MY14_Gas_Rx" SG_ 1077 PwLftgtIntSw_B_Stat 1;
BA_ "U_U502_MY15_Gas_Rx" SG_ 1077 PwLftgtIntSw_B_Stat 1;
BA_ "U_UP375_MY15_Gas_Rx" SG_ 1077 PwLftgtIntSw_B_Stat 1;
BA_ "U_UP375_MY15_Diesel_Rx" SG_ 1077 PwLftgtIntSw_B_Stat 1;
BA_ "U_CD43_MY16_Gas_Rx" SG_ 1077 PwLftgtIntSw_B_Stat 1;
BA_ "U_CD4_MY14_Diesel_Rx" SG_ 1077 PwLftgtIntSw_B_Stat 1;
BA_ "U_CD4_MY14_Gas_Rx" SG_ 1077 PwLftgtIntSw_B_Stat 1;
BA_ "U_CD4_MY14_Hev_Rx" SG_ 1077 PwLftgtIntSw_B_Stat 1;
BA_ "U_CD4_MY14_Phev_Rx" SG_ 1077 PwLftgtIntSw_B_Stat 1;
BA_ "U_CD4_MY13_Diesel_Rx" SG_ 1077 TurnLampTrlrRl_B_Stat_UB 1;
BA_ "U_CD4_MY13_Gas_Rx" SG_ 1077 TurnLampTrlrRl_B_Stat_UB 1;
BA_ "U_CD4_MY13_Hev_Rx" SG_ 1077 TurnLampTrlrRl_B_Stat_UB 1;
BA_ "U_CD4_MY13_Phev_Rx" SG_ 1077 TurnLampTrlrRl_B_Stat_UB 1;
BA_ "U_CD42_MY14_Diesel_Rx" SG_ 1077 TurnLampTrlrRl_B_Stat_UB 1;
BA_ "U_CD42_MY14_Gas_Rx" SG_ 1077 TurnLampTrlrRl_B_Stat_UB 1;
BA_ "U_P552_MY15_Gas_Rx" SG_ 1077 TurnLampTrlrRl_B_Stat_UB 1;
BA_ "U_S550_MY15_Gas_Rx" SG_ 1077 TurnLampTrlrRl_B_Stat_UB 1;
BA_ "U_C489_MY14_Gas_Rx" SG_ 1077 TurnLampTrlrRl_B_Stat_UB 1;
BA_ "U_U502_MY15_Gas_Rx" SG_ 1077 TurnLampTrlrRl_B_Stat_UB 1;
BA_ "U_UP375_MY15_Gas_Rx" SG_ 1077 TurnLampTrlrRl_B_Stat_UB 1;
BA_ "U_UP375_MY15_Diesel_Rx" SG_ 1077 TurnLampTrlrRl_B_Stat_UB 1;
BA_ "U_CD43_MY16_Gas_Rx" SG_ 1077 TurnLampTrlrRl_B_Stat_UB 1;
BA_ "U_CD4_MY14_Diesel_Rx" SG_ 1077 TurnLampTrlrRl_B_Stat_UB 1;
BA_ "U_CD4_MY14_Gas_Rx" SG_ 1077 TurnLampTrlrRl_B_Stat_UB 1;
BA_ "U_CD4_MY14_Hev_Rx" SG_ 1077 TurnLampTrlrRl_B_Stat_UB 1;
BA_ "U_CD4_MY14_Phev_Rx" SG_ 1077 TurnLampTrlrRl_B_Stat_UB 1;
BA_ "CrossOver_InfoCAN" SG_ 1077 TurnLampTrlrRr_B_Stat 1;
BA_ "GenSigSendType" SG_ 1077 TurnLampTrlrRr_B_Stat 3;
BA_ "U_CD4_MY13_Diesel_Rx" SG_ 1077 TurnLampTrlrRr_B_Stat 1;
BA_ "U_CD4_MY13_Gas_Rx" SG_ 1077 TurnLampTrlrRr_B_Stat 1;
BA_ "U_CD4_MY13_Hev_Rx" SG_ 1077 TurnLampTrlrRr_B_Stat 1;
BA_ "U_CD4_MY13_Phev_Rx" SG_ 1077 TurnLampTrlrRr_B_Stat 1;
BA_ "U_CD42_MY14_Diesel_Rx" SG_ 1077 TurnLampTrlrRr_B_Stat 1;
BA_ "U_CD42_MY14_Gas_Rx" SG_ 1077 TurnLampTrlrRr_B_Stat 1;
BA_ "U_P552_MY15_Gas_Rx" SG_ 1077 TurnLampTrlrRr_B_Stat 1;
BA_ "U_S550_MY15_Gas_Rx" SG_ 1077 TurnLampTrlrRr_B_Stat 1;
BA_ "U_C489_MY14_Gas_Rx" SG_ 1077 TurnLampTrlrRr_B_Stat 1;
BA_ "U_U502_MY15_Gas_Rx" SG_ 1077 TurnLampTrlrRr_B_Stat 1;
BA_ "U_UP375_MY15_Gas_Rx" SG_ 1077 TurnLampTrlrRr_B_Stat 1;
BA_ "U_UP375_MY15_Diesel_Rx" SG_ 1077 TurnLampTrlrRr_B_Stat 1;
BA_ "U_CD43_MY16_Gas_Rx" SG_ 1077 TurnLampTrlrRr_B_Stat 1;
BA_ "U_CD4_MY14_Diesel_Rx" SG_ 1077 TurnLampTrlrRr_B_Stat 1;
BA_ "U_CD4_MY14_Gas_Rx" SG_ 1077 TurnLampTrlrRr_B_Stat 1;
BA_ "U_CD4_MY14_Hev_Rx" SG_ 1077 TurnLampTrlrRr_B_Stat 1;
BA_ "U_CD4_MY14_Phev_Rx" SG_ 1077 TurnLampTrlrRr_B_Stat 1;
BA_ "CrossOver_InfoCAN" SG_ 1077 TurnLampTrlrRl_B_Stat 1;
BA_ "GenSigSendType" SG_ 1077 TurnLampTrlrRl_B_Stat 3;
BA_ "U_CD4_MY13_Diesel_Rx" SG_ 1077 TurnLampTrlrRl_B_Stat 1;
BA_ "U_CD4_MY13_Gas_Rx" SG_ 1077 TurnLampTrlrRl_B_Stat 1;
BA_ "U_CD4_MY13_Hev_Rx" SG_ 1077 TurnLampTrlrRl_B_Stat 1;
BA_ "U_CD4_MY13_Phev_Rx" SG_ 1077 TurnLampTrlrRl_B_Stat 1;
BA_ "U_CD42_MY14_Diesel_Rx" SG_ 1077 TurnLampTrlrRl_B_Stat 1;
BA_ "U_CD42_MY14_Gas_Rx" SG_ 1077 TurnLampTrlrRl_B_Stat 1;
BA_ "U_P552_MY15_Gas_Rx" SG_ 1077 TurnLampTrlrRl_B_Stat 1;
BA_ "U_S550_MY15_Gas_Rx" SG_ 1077 TurnLampTrlrRl_B_Stat 1;
BA_ "U_C489_MY14_Gas_Rx" SG_ 1077 TurnLampTrlrRl_B_Stat 1;
BA_ "U_U502_MY15_Gas_Rx" SG_ 1077 TurnLampTrlrRl_B_Stat 1;
BA_ "U_UP375_MY15_Gas_Rx" SG_ 1077 TurnLampTrlrRl_B_Stat 1;
BA_ "U_UP375_MY15_Diesel_Rx" SG_ 1077 TurnLampTrlrRl_B_Stat 1;
BA_ "U_CD43_MY16_Gas_Rx" SG_ 1077 TurnLampTrlrRl_B_Stat 1;
BA_ "U_CD4_MY14_Diesel_Rx" SG_ 1077 TurnLampTrlrRl_B_Stat 1;
BA_ "U_CD4_MY14_Gas_Rx" SG_ 1077 TurnLampTrlrRl_B_Stat 1;
BA_ "U_CD4_MY14_Hev_Rx" SG_ 1077 TurnLampTrlrRl_B_Stat 1;
BA_ "U_CD4_MY14_Phev_Rx" SG_ 1077 TurnLampTrlrRl_B_Stat 1;
BA_ "CrossOver_InfoCAN" SG_ 1077 FuelLvl_Pc_Dsply 1;
BA_ "U_CD4_MY13_Diesel_Rx" SG_ 862 ApaSwtch_No_Cnt 1;
BA_ "U_CD4_MY13_Gas_Rx" SG_ 862 ApaSwtch_No_Cnt 1;
BA_ "U_CD4_MY13_Hev_Rx" SG_ 862 ApaSwtch_No_Cnt 1;
BA_ "U_CD4_MY13_Phev_Rx" SG_ 862 ApaSwtch_No_Cnt 1;
BA_ "U_CD42_MY14_Diesel_Rx" SG_ 862 ApaSwtch_No_Cnt 1;
BA_ "U_CD42_MY14_Gas_Rx" SG_ 862 ApaSwtch_No_Cnt 1;
BA_ "U_P552_MY15_Gas_Rx" SG_ 862 ApaSwtch_No_Cnt 1;
BA_ "U_C489_MY14_Gas_Rx" SG_ 862 ApaSwtch_No_Cnt 1;
BA_ "U_U502_MY15_Gas_Rx" SG_ 862 ApaSwtch_No_Cnt 1;
BA_ "U_UP375_MY15_Gas_Rx" SG_ 862 ApaSwtch_No_Cnt 1;
BA_ "U_UP375_MY15_Diesel_Rx" SG_ 862 ApaSwtch_No_Cnt 1;
BA_ "U_CD43_MY16_Gas_Rx" SG_ 862 ApaSwtch_No_Cnt 1;
BA_ "U_CD4_MY14_Diesel_Rx" SG_ 862 ApaSwtch_No_Cnt 1;
BA_ "U_CD4_MY14_Gas_Rx" SG_ 862 ApaSwtch_No_Cnt 1;
BA_ "U_CD4_MY14_Hev_Rx" SG_ 862 ApaSwtch_No_Cnt 1;
BA_ "U_CD4_MY14_Phev_Rx" SG_ 862 ApaSwtch_No_Cnt 1;
BA_ "U_CD4_MY13_Diesel_Rx" SG_ 862 ApaSwtch_D_RqDrv 1;
BA_ "U_CD4_MY13_Gas_Rx" SG_ 862 ApaSwtch_D_RqDrv 1;
BA_ "U_CD4_MY13_Hev_Rx" SG_ 862 ApaSwtch_D_RqDrv 1;
BA_ "U_CD4_MY13_Phev_Rx" SG_ 862 ApaSwtch_D_RqDrv 1;
BA_ "U_CD42_MY14_Diesel_Rx" SG_ 862 ApaSwtch_D_RqDrv 1;
BA_ "U_CD42_MY14_Gas_Rx" SG_ 862 ApaSwtch_D_RqDrv 1;
BA_ "U_P552_MY15_Gas_Rx" SG_ 862 ApaSwtch_D_RqDrv 1;
BA_ "U_C489_MY14_Gas_Rx" SG_ 862 ApaSwtch_D_RqDrv 1;
BA_ "U_U502_MY15_Gas_Rx" SG_ 862 ApaSwtch_D_RqDrv 1;
BA_ "U_UP375_MY15_Gas_Rx" SG_ 862 ApaSwtch_D_RqDrv 1;
BA_ "U_UP375_MY15_Diesel_Rx" SG_ 862 ApaSwtch_D_RqDrv 1;
BA_ "U_CD43_MY16_Gas_Rx" SG_ 862 ApaSwtch_D_RqDrv 1;
BA_ "U_CD4_MY14_Diesel_Rx" SG_ 862 ApaSwtch_D_RqDrv 1;
BA_ "U_CD4_MY14_Gas_Rx" SG_ 862 ApaSwtch_D_RqDrv 1;
BA_ "U_CD4_MY14_Hev_Rx" SG_ 862 ApaSwtch_D_RqDrv 1;
BA_ "U_CD4_MY14_Phev_Rx" SG_ 862 ApaSwtch_D_RqDrv 1;
BA_ "U_CD4_MY13_Diesel_Rx" SG_ 862 HvacBlwrFront_D_Stat 1;
BA_ "U_CD4_MY13_Gas_Rx" SG_ 862 HvacBlwrFront_D_Stat 1;
BA_ "U_CD4_MY13_Hev_Rx" SG_ 862 HvacBlwrFront_D_Stat 1;
BA_ "U_CD4_MY13_Phev_Rx" SG_ 862 HvacBlwrFront_D_Stat 1;
BA_ "U_CD42_MY14_Diesel_Rx" SG_ 862 HvacBlwrFront_D_Stat 1;
BA_ "U_CD42_MY14_Gas_Rx" SG_ 862 HvacBlwrFront_D_Stat 1;
BA_ "U_P552_MY15_Gas_Rx" SG_ 862 HvacBlwrFront_D_Stat 1;
BA_ "U_S550_MY15_Gas_Rx" SG_ 862 HvacBlwrFront_D_Stat 1;
BA_ "U_C489_MY14_Gas_Rx" SG_ 862 HvacBlwrFront_D_Stat 1;
BA_ "U_U502_MY15_Gas_Rx" SG_ 862 HvacBlwrFront_D_Stat 1;
BA_ "U_UP375_MY15_Gas_Rx" SG_ 862 HvacBlwrFront_D_Stat 1;
BA_ "U_UP375_MY15_Diesel_Rx" SG_ 862 HvacBlwrFront_D_Stat 1;
BA_ "U_CD43_MY16_Gas_Rx" SG_ 862 HvacBlwrFront_D_Stat 1;
BA_ "U_CD4_MY14_Diesel_Rx" SG_ 862 HvacBlwrFront_D_Stat 1;
BA_ "U_CD4_MY14_Gas_Rx" SG_ 862 HvacBlwrFront_D_Stat 1;
BA_ "U_CD4_MY14_Hev_Rx" SG_ 862 HvacBlwrFront_D_Stat 1;
BA_ "U_CD4_MY14_Phev_Rx" SG_ 862 HvacBlwrFront_D_Stat 1;
BA_ "U_CD4_MY13_Diesel_Rx" SG_ 862 HvacBlwrRear_D_Stat 1;
BA_ "U_CD4_MY13_Gas_Rx" SG_ 862 HvacBlwrRear_D_Stat 1;
BA_ "U_CD4_MY13_Hev_Rx" SG_ 862 HvacBlwrRear_D_Stat 1;
BA_ "U_CD4_MY13_Phev_Rx" SG_ 862 HvacBlwrRear_D_Stat 1;
BA_ "U_CD42_MY14_Diesel_Rx" SG_ 862 HvacBlwrRear_D_Stat 1;
BA_ "U_CD42_MY14_Gas_Rx" SG_ 862 HvacBlwrRear_D_Stat 1;
BA_ "U_P552_MY15_Gas_Rx" SG_ 862 HvacBlwrRear_D_Stat 1;
BA_ "U_S550_MY15_Gas_Rx" SG_ 862 HvacBlwrRear_D_Stat 1;
BA_ "U_C489_MY14_Gas_Rx" SG_ 862 HvacBlwrRear_D_Stat 1;
BA_ "U_U502_MY15_Gas_Rx" SG_ 862 HvacBlwrRear_D_Stat 1;
BA_ "U_UP375_MY15_Gas_Rx" SG_ 862 HvacBlwrRear_D_Stat 1;
BA_ "U_UP375_MY15_Diesel_Rx" SG_ 862 HvacBlwrRear_D_Stat 1;
BA_ "U_CD43_MY16_Gas_Rx" SG_ 862 HvacBlwrRear_D_Stat 1;
BA_ "U_CD4_MY14_Diesel_Rx" SG_ 862 HvacBlwrRear_D_Stat 1;
BA_ "U_CD4_MY14_Gas_Rx" SG_ 862 HvacBlwrRear_D_Stat 1;
BA_ "U_CD4_MY14_Hev_Rx" SG_ 862 HvacBlwrRear_D_Stat 1;
BA_ "U_CD4_MY14_Phev_Rx" SG_ 862 HvacBlwrRear_D_Stat 1;
BA_ "U_CD4_MY13_Gas_Rx" SG_ 862 HvacRemoteStrt_N_Rq 1;
BA_ "U_CD42_MY14_Gas_Rx" SG_ 862 HvacRemoteStrt_N_Rq 1;
BA_ "U_P552_MY15_Gas_Rx" SG_ 862 HvacRemoteStrt_N_Rq 1;
BA_ "U_S550_MY15_Gas_Rx" SG_ 862 HvacRemoteStrt_N_Rq 1;
BA_ "U_C489_MY14_Gas_Rx" SG_ 862 HvacRemoteStrt_N_Rq 1;
BA_ "U_U502_MY15_Gas_Rx" SG_ 862 HvacRemoteStrt_N_Rq 1;
BA_ "U_CD43_MY16_Gas_Rx" SG_ 862 HvacRemoteStrt_N_Rq 1;
BA_ "U_CD4_MY14_Gas_Rx" SG_ 862 HvacRemoteStrt_N_Rq 1;
BA_ "GenSigStartValue" SG_ 862 ClimtThrmlLoad_No_Actl 255;
BA_ "GenSigStartValue" SG_ 862 AutoStpHvacDelta_I_Est 192;
BA_ "U_CD4_MY13_Diesel_Rx" SG_ 862 AutoStpHvacDelta_I_Est 1;
BA_ "U_CD4_MY13_Gas_Rx" SG_ 862 AutoStpHvacDelta_I_Est 1;
BA_ "U_CD4_MY13_Hev_Rx" SG_ 862 AutoStpHvacDelta_I_Est 1;
BA_ "U_CD4_MY13_Phev_Rx" SG_ 862 AutoStpHvacDelta_I_Est 1;
BA_ "U_CD42_MY14_Diesel_Rx" SG_ 862 AutoStpHvacDelta_I_Est 1;
BA_ "U_CD42_MY14_Gas_Rx" SG_ 862 AutoStpHvacDelta_I_Est 1;
BA_ "U_P552_MY15_Gas_Rx" SG_ 862 AutoStpHvacDelta_I_Est 1;
BA_ "U_S550_MY15_Gas_Rx" SG_ 862 AutoStpHvacDelta_I_Est 1;
BA_ "U_C489_MY14_Gas_Rx" SG_ 862 AutoStpHvacDelta_I_Est 1;
BA_ "U_U502_MY15_Gas_Rx" SG_ 862 AutoStpHvacDelta_I_Est 1;
BA_ "U_UP375_MY15_Gas_Rx" SG_ 862 AutoStpHvacDelta_I_Est 1;
BA_ "U_UP375_MY15_Diesel_Rx" SG_ 862 AutoStpHvacDelta_I_Est 1;
BA_ "U_CD43_MY16_Gas_Rx" SG_ 862 AutoStpHvacDelta_I_Est 1;
BA_ "U_CD4_MY14_Diesel_Rx" SG_ 862 AutoStpHvacDelta_I_Est 1;
BA_ "U_CD4_MY14_Gas_Rx" SG_ 862 AutoStpHvacDelta_I_Est 1;
BA_ "U_CD4_MY14_Hev_Rx" SG_ 862 AutoStpHvacDelta_I_Est 1;
BA_ "U_CD4_MY14_Phev_Rx" SG_ 862 AutoStpHvacDelta_I_Est 1;
BA_ "ContentDependant" SG_ 342 EngOil_Te_Actl 1;
BA_ "U_P558_MY17_Diesel_Tx" SG_ 342 EngOil_Te_Actl 1;
BA_ "U_S550_MY15_Gas_Rx" SG_ 342 EngOil_Te_Actl 1;
BA_ "CrossOver_InfoCAN" SG_ 342 EngOil_Te_Actl 1;
BA_ "CrossOver_InfoCAN" SG_ 342 EngOvrhtMitgActv_D_Ind 1;
BA_ "ContentDependant" SG_ 342 EngOvrhtMitgActv_D_Ind 1;
BA_ "U_CD4_MY13_Gas_Tx" SG_ 342 EngOvrhtMitgActv_D_Ind 1;
BA_ "U_CD42_MY14_Gas_Tx" SG_ 342 EngOvrhtMitgActv_D_Ind 1;
BA_ "U_P552_MY15_Gas_Tx" SG_ 342 EngOvrhtMitgActv_D_Ind 1;
BA_ "U_S550_MY15_Gas_Tx" SG_ 342 EngOvrhtMitgActv_D_Ind 1;
BA_ "U_C489_MY14_Gas_Tx" SG_ 342 EngOvrhtMitgActv_D_Ind 1;
BA_ "U_U502_MY15_Gas_Tx" SG_ 342 EngOvrhtMitgActv_D_Ind 1;
BA_ "U_UP375_MY15_Gas_Tx" SG_ 342 EngOvrhtMitgActv_D_Ind 1;
BA_ "U_CD43_MY16_Gas_Tx" SG_ 342 EngOvrhtMitgActv_D_Ind 1;
BA_ "U_CD4_MY14_Gas_Tx" SG_ 342 EngOvrhtMitgActv_D_Ind 1;
BA_ "CrossOver_InfoCAN" SG_ 342 EngClntTe_D_Qf 1;
BA_ "U_CD4_MY13_Phev_Rx" SG_ 342 EngClntTe_D_Qf 1;
BA_ "U_CD42_MY14_Diesel_Rx" SG_ 342 EngClntTe_D_Qf 1;
BA_ "U_CD42_MY14_Gas_Rx" SG_ 342 EngClntTe_D_Qf 1;
BA_ "U_P552_MY15_Gas_Rx" SG_ 342 EngClntTe_D_Qf 1;
BA_ "U_S550_MY15_Gas_Rx" SG_ 342 EngClntTe_D_Qf 1;
BA_ "U_C489_MY14_Gas_Rx" SG_ 342 EngClntTe_D_Qf 1;
BA_ "U_U502_MY15_Gas_Rx" SG_ 342 EngClntTe_D_Qf 1;
BA_ "U_UP375_MY15_Gas_Rx" SG_ 342 EngClntTe_D_Qf 1;
BA_ "U_UP375_MY15_Diesel_Rx" SG_ 342 EngClntTe_D_Qf 1;
BA_ "U_CD43_MY16_Gas_Rx" SG_ 342 EngClntTe_D_Qf 1;
BA_ "U_CD4_MY14_Diesel_Rx" SG_ 342 EngClntTe_D_Qf 1;
BA_ "U_CD4_MY14_Gas_Rx" SG_ 342 EngClntTe_D_Qf 1;
BA_ "U_CD4_MY14_Hev_Rx" SG_ 342 EngClntTe_D_Qf 1;
BA_ "U_CD4_MY14_Phev_Rx" SG_ 342 EngClntTe_D_Qf 1;
BA_ "U_CD4_MY13_Gas_Tx" SG_ 342 EngClntTe_D_Qf 1;
BA_ "U_CD42_MY14_Gas_Tx" SG_ 342 EngClntTe_D_Qf 1;
BA_ "U_P552_MY15_Gas_Tx" SG_ 342 EngClntTe_D_Qf 1;
BA_ "U_S550_MY15_Gas_Tx" SG_ 342 EngClntTe_D_Qf 1;
BA_ "U_C489_MY14_Gas_Tx" SG_ 342 EngClntTe_D_Qf 1;
BA_ "U_U502_MY15_Gas_Tx" SG_ 342 EngClntTe_D_Qf 1;
BA_ "U_UP375_MY15_Gas_Tx" SG_ 342 EngClntTe_D_Qf 1;
BA_ "U_CD43_MY16_Gas_Tx" SG_ 342 EngClntTe_D_Qf 1;
BA_ "U_CD4_MY14_Gas_Tx" SG_ 342 EngClntTe_D_Qf 1;
BA_ "GenSigTimeoutTime_TCM" SG_ 342 EngClntTe_D_Qf 300;
BA_ "CrossOver_InfoCAN" SG_ 342 EngClnt_Te_Actl 1;
BA_ "U_CD4_MY13_Phev_Rx" SG_ 342 EngClnt_Te_Actl 1;
BA_ "U_CD42_MY14_Diesel_Rx" SG_ 342 EngClnt_Te_Actl 1;
BA_ "U_CD42_MY14_Gas_Rx" SG_ 342 EngClnt_Te_Actl 1;
BA_ "U_P552_MY15_Gas_Rx" SG_ 342 EngClnt_Te_Actl 1;
BA_ "U_S550_MY15_Gas_Rx" SG_ 342 EngClnt_Te_Actl 1;
BA_ "U_C489_MY14_Gas_Rx" SG_ 342 EngClnt_Te_Actl 1;
BA_ "U_U502_MY15_Gas_Rx" SG_ 342 EngClnt_Te_Actl 1;
BA_ "U_UP375_MY15_Gas_Rx" SG_ 342 EngClnt_Te_Actl 1;
BA_ "U_UP375_MY15_Diesel_Rx" SG_ 342 EngClnt_Te_Actl 1;
BA_ "U_CD43_MY16_Gas_Rx" SG_ 342 EngClnt_Te_Actl 1;
BA_ "U_CD4_MY14_Diesel_Rx" SG_ 342 EngClnt_Te_Actl 1;
BA_ "U_CD4_MY14_Gas_Rx" SG_ 342 EngClnt_Te_Actl 1;
BA_ "U_CD4_MY14_Hev_Rx" SG_ 342 EngClnt_Te_Actl 1;
BA_ "U_CD4_MY14_Phev_Rx" SG_ 342 EngClnt_Te_Actl 1;
BA_ "U_CD4_MY13_Gas_Tx" SG_ 342 EngClnt_Te_Actl 1;
BA_ "U_CD42_MY14_Gas_Tx" SG_ 342 EngClnt_Te_Actl 1;
BA_ "U_P552_MY15_Gas_Tx" SG_ 342 EngClnt_Te_Actl 1;
BA_ "U_S550_MY15_Gas_Tx" SG_ 342 EngClnt_Te_Actl 1;
BA_ "U_C489_MY14_Gas_Tx" SG_ 342 EngClnt_Te_Actl 1;
BA_ "U_U502_MY15_Gas_Tx" SG_ 342 EngClnt_Te_Actl 1;
BA_ "U_UP375_MY15_Gas_Tx" SG_ 342 EngClnt_Te_Actl 1;
BA_ "U_CD43_MY16_Gas_Tx" SG_ 342 EngClnt_Te_Actl 1;
BA_ "U_CD4_MY14_Gas_Tx" SG_ 342 EngClnt_Te_Actl 1;
BA_ "GenSigTimeoutTime_TCM" SG_ 342 EngClnt_Te_Actl 300;
BA_ "CrossOver_InfoCAN" SG_ 992 MsgCntrPersIndex_D_Rq 1;
BA_ "GenSigStartValue" SG_ 992 MsgCntrPersIndex_D_Rq 4;
BA_ "U_CD4_MY13_Diesel_Rx" SG_ 992 MsgCntrPersIndex_D_Rq 1;
BA_ "U_CD4_MY13_Gas_Rx" SG_ 992 MsgCntrPersIndex_D_Rq 1;
BA_ "U_CD4_MY13_Hev_Rx" SG_ 992 MsgCntrPersIndex_D_Rq 1;
BA_ "U_CD4_MY13_Phev_Rx" SG_ 992 MsgCntrPersIndex_D_Rq 1;
BA_ "U_CD42_MY14_Diesel_Rx" SG_ 992 MsgCntrPersIndex_D_Rq 1;
BA_ "U_CD42_MY14_Gas_Rx" SG_ 992 MsgCntrPersIndex_D_Rq 1;
BA_ "U_P552_MY15_Gas_Rx" SG_ 992 MsgCntrPersIndex_D_Rq 1;
BA_ "U_S550_MY15_Gas_Rx" SG_ 992 MsgCntrPersIndex_D_Rq 1;
BA_ "U_C489_MY14_Gas_Rx" SG_ 992 MsgCntrPersIndex_D_Rq 1;
BA_ "U_U502_MY15_Gas_Rx" SG_ 992 MsgCntrPersIndex_D_Rq 1;
BA_ "U_UP375_MY15_Gas_Rx" SG_ 992 MsgCntrPersIndex_D_Rq 1;
BA_ "U_UP375_MY15_Diesel_Rx" SG_ 992 MsgCntrPersIndex_D_Rq 1;
BA_ "U_CD43_MY16_Gas_Rx" SG_ 992 MsgCntrPersIndex_D_Rq 1;
BA_ "U_CD4_MY14_Diesel_Rx" SG_ 992 MsgCntrPersIndex_D_Rq 1;
BA_ "U_CD4_MY14_Gas_Rx" SG_ 992 MsgCntrPersIndex_D_Rq 1;
BA_ "U_CD4_MY14_Hev_Rx" SG_ 992 MsgCntrPersIndex_D_Rq 1;
BA_ "U_CD4_MY14_Phev_Rx" SG_ 992 MsgCntrPersIndex_D_Rq 1;
BA_ "CrossOver_InfoCAN" SG_ 992 MsgCntrFeatConfigRq 1;
BA_ "U_CD4_MY13_Diesel_Rx" SG_ 992 MsgCntrFeatConfigRq 1;
BA_ "U_CD4_MY13_Gas_Rx" SG_ 992 MsgCntrFeatConfigRq 1;
BA_ "U_CD4_MY13_Hev_Rx" SG_ 992 MsgCntrFeatConfigRq 1;
BA_ "U_CD4_MY13_Phev_Rx" SG_ 992 MsgCntrFeatConfigRq 1;
BA_ "U_CD42_MY14_Diesel_Rx" SG_ 992 MsgCntrFeatConfigRq 1;
BA_ "U_CD42_MY14_Gas_Rx" SG_ 992 MsgCntrFeatConfigRq 1;
BA_ "U_P552_MY15_Gas_Rx" SG_ 992 MsgCntrFeatConfigRq 1;
BA_ "U_S550_MY15_Gas_Rx" SG_ 992 MsgCntrFeatConfigRq 1;
BA_ "U_C489_MY14_Gas_Rx" SG_ 992 MsgCntrFeatConfigRq 1;
BA_ "U_U502_MY15_Gas_Rx" SG_ 992 MsgCntrFeatConfigRq 1;
BA_ "U_UP375_MY15_Gas_Rx" SG_ 992 MsgCntrFeatConfigRq 1;
BA_ "U_UP375_MY15_Diesel_Rx" SG_ 992 MsgCntrFeatConfigRq 1;
BA_ "U_CD43_MY16_Gas_Rx" SG_ 992 MsgCntrFeatConfigRq 1;
BA_ "U_CD4_MY14_Diesel_Rx" SG_ 992 MsgCntrFeatConfigRq 1;
BA_ "U_CD4_MY14_Gas_Rx" SG_ 992 MsgCntrFeatConfigRq 1;
BA_ "U_CD4_MY14_Hev_Rx" SG_ 992 MsgCntrFeatConfigRq 1;
BA_ "U_CD4_MY14_Phev_Rx" SG_ 992 MsgCntrFeatConfigRq 1;
BA_ "CrossOver_InfoCAN" SG_ 992 MsgCntrFeatNoRq 1;
BA_ "U_CD4_MY13_Diesel_Rx" SG_ 992 MsgCntrFeatNoRq 1;
BA_ "U_CD4_MY13_Gas_Rx" SG_ 992 MsgCntrFeatNoRq 1;
BA_ "U_CD4_MY13_Hev_Rx" SG_ 992 MsgCntrFeatNoRq 1;
BA_ "U_CD4_MY13_Phev_Rx" SG_ 992 MsgCntrFeatNoRq 1;
BA_ "U_CD42_MY14_Diesel_Rx" SG_ 992 MsgCntrFeatNoRq 1;
BA_ "U_CD42_MY14_Gas_Rx" SG_ 992 MsgCntrFeatNoRq 1;
BA_ "U_P552_MY15_Gas_Rx" SG_ 992 MsgCntrFeatNoRq 1;
BA_ "U_S550_MY15_Gas_Rx" SG_ 992 MsgCntrFeatNoRq 1;
BA_ "U_C489_MY14_Gas_Rx" SG_ 992 MsgCntrFeatNoRq 1;
BA_ "U_U502_MY15_Gas_Rx" SG_ 992 MsgCntrFeatNoRq 1;
BA_ "U_UP375_MY15_Gas_Rx" SG_ 992 MsgCntrFeatNoRq 1;
BA_ "U_UP375_MY15_Diesel_Rx" SG_ 992 MsgCntrFeatNoRq 1;
BA_ "U_CD43_MY16_Gas_Rx" SG_ 992 MsgCntrFeatNoRq 1;
BA_ "U_CD4_MY14_Diesel_Rx" SG_ 992 MsgCntrFeatNoRq 1;
BA_ "U_CD4_MY14_Gas_Rx" SG_ 992 MsgCntrFeatNoRq 1;
BA_ "U_CD4_MY14_Hev_Rx" SG_ 992 MsgCntrFeatNoRq 1;
BA_ "U_CD4_MY14_Phev_Rx" SG_ 992 MsgCntrFeatNoRq 1;
BA_ "CrossOver_InfoCAN" SG_ 992 MsgCntrDsplyOp_D_Rq 1;
BA_ "U_CD4_MY13_Diesel_Rx" SG_ 992 MsgCntrDsplyOp_D_Rq 1;
BA_ "U_CD4_MY13_Gas_Rx" SG_ 992 MsgCntrDsplyOp_D_Rq 1;
BA_ "U_CD4_MY13_Hev_Rx" SG_ 992 MsgCntrDsplyOp_D_Rq 1;
BA_ "U_CD4_MY13_Phev_Rx" SG_ 992 MsgCntrDsplyOp_D_Rq 1;
BA_ "U_CD42_MY14_Diesel_Rx" SG_ 992 MsgCntrDsplyOp_D_Rq 1;
BA_ "U_CD42_MY14_Gas_Rx" SG_ 992 MsgCntrDsplyOp_D_Rq 1;
BA_ "U_P552_MY15_Gas_Rx" SG_ 992 MsgCntrDsplyOp_D_Rq 1;
BA_ "U_S550_MY15_Gas_Rx" SG_ 992 MsgCntrDsplyOp_D_Rq 1;
BA_ "U_C489_MY14_Gas_Rx" SG_ 992 MsgCntrDsplyOp_D_Rq 1;
BA_ "U_U502_MY15_Gas_Rx" SG_ 992 MsgCntrDsplyOp_D_Rq 1;
BA_ "U_UP375_MY15_Gas_Rx" SG_ 992 MsgCntrDsplyOp_D_Rq 1;
BA_ "U_UP375_MY15_Diesel_Rx" SG_ 992 MsgCntrDsplyOp_D_Rq 1;
BA_ "U_CD43_MY16_Gas_Rx" SG_ 992 MsgCntrDsplyOp_D_Rq 1;
BA_ "U_CD4_MY14_Diesel_Rx" SG_ 992 MsgCntrDsplyOp_D_Rq 1;
BA_ "U_CD4_MY14_Gas_Rx" SG_ 992 MsgCntrDsplyOp_D_Rq 1;
BA_ "U_CD4_MY14_Hev_Rx" SG_ 992 MsgCntrDsplyOp_D_Rq 1;
BA_ "U_CD4_MY14_Phev_Rx" SG_ 992 MsgCntrDsplyOp_D_Rq 1;
VAL_ 1200 BrkAutoHold_D_Stat 7 "Faulty" 6 "NotUsed" 5 "Releasing" 4 "HeldSecondary" 3 "HeldSecure" 2 "Held" 1 "Inactive" 0 "Off" ;
VAL_ 1200 BrkBstrVac_P_Actl 127 "Invalid" ;
VAL_ 1200 YawStabilityIndex 511 "Fault" 510 "NoDataExists" ;
VAL_ 1200 BrkTot_Tq_RqDrv 8191 "Fault" ;
VAL_ 376 GasPrtc_D_RqDsply 7 "NotUsed_5" 6 "NotUsed_4" 5 "NotUsed_3" 4 "NotUsed_2" 3 "NotUsed_1" 2 "GpfOverLimit" 1 "GpfAtLimit" 0 "NormalOperation" ;
VAL_ 376 PtcHtr_D_Cmd 3 "TurnOn" 2 "AutoMode" 1 "TurnOff" 0 "NoDecision_Initializing" ;
VAL_ 376 AslIconDsply_D_Rq 3 "Not_Used" 2 "On_Active" 1 "On_Passive" 0 "Off" ;
VAL_ 376 AslChime_B_Rq 1 "Yes" 0 "No" ;
VAL_ 376 DynoMde_B_Cmd 1 "Two_Wheel_Dyno" 0 "Normal_Operation" ;
VAL_ 376 AirAmbTe_D_Qf 3 "OK" 2 "Not_Within_Specifications" 1 "No_Data_Exists" 0 "Faulty" ;
VAL_ 376 AirAmb_P_Actl 63 "Fault" 62 "NoDataExists" ;
VAL_ 516 ApedPos_PcRate_ActlArb 255 "Fault" 254 "Unknown" ;
VAL_ 516 ApedPosPcActl_D_Qf 3 "OK" 2 "Not_Within_Specifications" 1 "No_Data_Exists" 0 "Faulty" ;
VAL_ 377 TrnManShif_D_IndDrv 7 "Undefined_3" 6 "Undefined_2" 5 "Shift_to_Neutral" 4 "Downshift_Recommendation" 3 "Upshift_Warning" 2 "Upshift_Performance" 1 "Upshift_Fuel_Economy" 0 "No_Indication" ;
VAL_ 377 TrnKickDown_B_RqDrv 1 "Yes" 0 "No" ;
VAL_ 377 FuelFilterLamp_B_Dsply 1 "On" 0 "Off" ;
VAL_ 377 FuelFillInlet_B_Dsply 1 "Yes" 0 "No" ;
VAL_ 377 EngSrvcRqd_B_Rq 1 "Engine_Service_Required" 0 "No_engine_service_required" ;
VAL_ 377 OdoCount 255 "Invalid" ;
VAL_ 377 AirCondRec_B_Rq 1 "Yes" 0 "No" ;
VAL_ 377 AirCondClutch_B_Stats 1 "Yes" 0 "No" ;
VAL_ 369 TrnIpcDsplyRng2_D_Actl 15 "No_Range_Selected" 14 "Range_14" 13 "Range_13" 12 "Range_12" 11 "Range_11" 10 "Range_10" 9 "Range_9" 8 "Range_8" 7 "Range_7" 6 "Range_6" 5 "Range_5" 4 "Range_4" 3 "Range_3" 2 "Range_2" 1 "Range_1" 0 "NotUsed" ;
VAL_ 369 TrnIpcDsplyRng_D_Stat 3 "NotUsed" 2 "Flash" 1 "On" 0 "Blank_No_Display" ;
VAL_ 369 TrnIpcDsplyGear_D_Actl 15 "No_Gear_Selected" 14 "_14th_Gear" 13 "_13th_Gear" 12 "_12th_Gear" 11 "_11th_Gear" 10 "_10th_Gear" 9 "_9th_Gear" 8 "_8th_Gear" 7 "_7th_Gear" 6 "_6th_Gear" 5 "_5th_Gear" 4 "_4th_Gear" 3 "_3rd_Gear" 2 "_2nd_Gear" 1 "_1st_Gear" 0 "Neutral" ;
VAL_ 369 TrnIpcDsplyMde_D_Stat 3 "Reserved_Blank_No_Display" 2 "Flash" 1 "On" 0 "Blank_No_Display" ;
VAL_ 369 TrnIpcDsplyMde_D_Actl 7 "Manual_3" 6 "Manual_2" 5 "Manual_1_Low" 4 "Sport" 3 "Drive" 2 "Neutral" 1 "Reverse" 0 "Park" ;
VAL_ 369 TrnIpcDsplyGear_D_Stat 3 "Reserved_Blank_No_Display" 2 "Flash" 1 "On" 0 "Blank_No_Display" ;
VAL_ 76 SecondRowBucklePsngr 3 "Unknown" 2 "Unbelted" 1 "Belted" 0 "Faulty" ;
VAL_ 76 SecondRowBuckleDriver 3 "Unknown" 2 "Unbelted" 1 "Belted" 0 "Faulty" ;
VAL_ 76 FirstRowBuckleDriver 3 "Unknown" 2 "Unbelted" 1 "Belted" 0 "Faulty" ;
VAL_ 76 RILReq 3 "Not_Used" 2 "Plant_Mode" 1 "On" 0 "Off" ;
VAL_ 76 FirstRowBucklePsngr 3 "Unknown" 2 "Unbelted" 1 "Belted" 0 "Faulty" ;
VAL_ 76 RstrnImpactEvntStatus 7 "Invalid" 6 "Not_Used_4" 5 "Threshold_2_Exceeded" 4 "Not_Used_3" 3 "Threshold_1_Exceeded" 2 "Not_Used_2" 1 "Not_Used_1" 0 "Normal" ;
VAL_ 76 PsngrFrntDetct_D_Actl 3 "Unknown" 2 "Empty" 0 "Faulty" 1 "Occupied" ;
VAL_ 76 EDRTriggerEvntSync 1 "Threshold_Exceeded" 0 "Normal" ;
VAL_ 76 PassRstrnInd_Req 3 "ABOnNotIllum_OffNotIllum" 2 "AirbagOnNot_Illum_OffIllum" 1 "AirbagOn_Illum_OffNotIllum" 0 "AirbagOn_Illum_Off_Illum" ;
VAL_ 146 VehVertAActl_D_Qf 3 "OK" 2 "Not_Within_Specifications" 1 "No_Data_Exists" 0 "Faulty" ;
VAL_ 146 VehVert2_A_Actl 8191 "Faulty" 8190 "NoDataExists" ;
VAL_ 146 VehLongAActl_D_Qf 3 "OK" 2 "Not_Within_Specifications" 1 "No_Data_Exists" 0 "Faulty" ;
VAL_ 146 VehLatAActl_D_Qf 3 "OK" 2 "Not_Within_Specifications" 1 "No_Data_Exists" 0 "Faulty" ;
VAL_ 146 VehLat2_A_Actl 8191 "Faulty" 8190 "NoDataExists" ;
VAL_ 146 VehLong2_A_Actl 8191 "Faulty" 8190 "NoDataExists" ;
VAL_ 967 CamraOvrlTow_D_Actl 3 "Not_Used" 2 "Inactive" 1 "Active" 0 "Invalid" ;
VAL_ 967 CamZoomActiveState 3 "Not_Used" 2 "Inactive" 1 "Active" 0 "Invalid" ;
VAL_ 967 CamraZoomMan_D_Actl 7 "Unknown" 6 "Invalid" 5 "Zoom_Level_V" 4 "Zoom_Level_IV" 3 "Zoom_Level_III" 2 "Zoom_Level_II" 1 "Zoom_Level_I" 0 "Off" ;
VAL_ 967 CamraOvrlStat_D_Actl 3 "Not_Used" 2 "Inactive" 1 "Active" 0 "Invalid" ;
VAL_ 967 CamraOvrlDyn_D_Actl 3 "Not_Used" 2 "Inactive" 1 "Active" 0 "Invalid" ;
VAL_ 967 CamPDCGuidStat 3 "Not_Used" 2 "Inactive" 1 "Active" 0 "Invalid" ;
VAL_ 949 Tire_Press_RR_ORR_Data 65535 "Not_Supported" 65534 "Invalid" 65533 "Unknown" ;
VAL_ 949 Tire_Press_LR_OLR_Data 65535 "Not_Supported" 65534 "Invalid" 65533 "Unknown" ;
VAL_ 949 Tire_Press_LF_Data 65535 "Not_Supported" 65534 "Invalid" 65533 "Unknown" ;
VAL_ 949 Tire_Press_RF_Data 65535 "Not_Supported" 65534 "Invalid" 65533 "Unknown" ;
VAL_ 948 Tire_Press_ILR_Stat 4 "Alert" 15 "Not_Supported" 3 "Fault" 2 "Low" 1 "Normal" 0 "Unknown" ;
VAL_ 948 Tire_Press_IRR_Stat 4 "Alert" 15 "Not_Supported" 3 "Fault" 2 "Low" 1 "Normal" 0 "Unknown" ;
VAL_ 948 Tire_Press_LR_OLR_Stat 4 "Alert" 15 "Not_Supported" 3 "Fault" 2 "Low" 1 "Normal" 0 "Unknown" ;
VAL_ 948 Tire_Press_RR_ORR_Stat 4 "Alert" 15 "Not_Supported" 3 "Fault" 2 "Low" 1 "Normal" 0 "Unknown" ;
VAL_ 948 Tire_Press_RF_Stat 4 "Alert" 15 "Not_Supported" 3 "Fault" 2 "Low" 1 "Normal" 0 "Unknown" ;
VAL_ 948 Tire_Press_LF_Stat 4 "Alert" 15 "Not_Supported" 3 "Fault" 2 "Low" 1 "Normal" 0 "Unknown" ;
VAL_ 948 Tire_Press_System_Stat 13 "Training_Complete" 12 "Train_InsideLeftRear_tire" 11 "Train_OutsideLeftRear_tire" 10 "Train_LeftRear_tire" 9 "Train_InsideRtRear_tire" 8 "Train_OutsideRtRear_tire" 7 "Train_RightRear_tire" 14 "Tires_not_trained" 6 "Train_RightFront_tire" 5 "Train_LeftFront_tire" 4 "Systm_Activ_Composite_Stat" 3 "Low_Composite_Stat" 2 "Sensr_Fault_Composite_Stat" 1 "Systm_Fault_Composite_Stat" 0 "Unknown_Composite_Stat" ;
VAL_ 948 Tire_Press_Telltale 3 "Not_Used" 2 "Flash" 1 "On" 0 "Off" ;
VAL_ 948 TirePReset_D_Stat 3 "Not_Used" 2 "Nack" 1 "Ack" 0 "Null" ;
VAL_ 1077 PtDrvMde_D_Rq_UB 1 "Fresh_data" 0 "Unchanged_data" ;
VAL_ 1077 PtDrvMde_D_Rq 15 "Faulty" 14 "NotUsed11" 13 "NotUsed10" 12 "NotUsed9" 11 "NotUsed8" 10 "NotUsed7" 9 "NotUsed6" 8 "NotUsed5" 7 "NotUsed4" 6 "Rock" 5 "Baja" 4 "Sand" 3 "TowHaulGradeAssist" 2 "SnowWet" 1 "Sport" 0 "Normal" ;
VAL_ 1077 TrlrBrkActCnnct_B_Actl_UB 1 "Fresh_data" 0 "Unchanged_data" ;
VAL_ 1077 TrlrBrkActCnnct_B_Actl 1 "Yes" 0 "No" ;
VAL_ 1077 PrkLckCtlEnbl_D_RqIpc_UB 1 "Fresh_data" 0 "Unchanged_data" ;
VAL_ 1077 PrkLckCtlEnbl_D_RqIpc 3 "Rq_Towing" 2 "Rq_Enable" 1 "Rq_Disable" 0 "Null" ;
VAL_ 1077 AutoRgen_D_Rq_UB 1 "Fresh_data" 0 "Unchanged_data" ;
VAL_ 1077 AutoRgen_D_Rq 3 "NotUsed" 2 "AutExhFilterCleanOFF" 1 "AutExhFilterCleanON" 0 "No_Mode_Selected" ;
VAL_ 1077 FuelLvl_Pc_Dsply_UB 1 "Fresh_data" 0 "Unchanged_data" ;
VAL_ 1077 StopStrtDrvMde_D_RqMnu_UB 1 "Fresh_data" 0 "Unchanged_data" ;
VAL_ 1077 StopStrtDrvMde_D_RqMnu 3 "NotUsed2" 2 "NotUsed1" 1 "StopStart_Deselected" 0 "StopStart_Selected" ;
VAL_ 1077 PtWakeupActv1_B_Rq 1 "Wake_up_Powertrain_via_HW" 0 "Don_t_Wake_Up_Powertrain" ;
VAL_ 1077 PtWakeupActv1_B_Rq_UB 1 "Fresh_data" 0 "Unchanged_data" ;
VAL_ 1077 PrkAidRear_D_RqDrv 2 "Status" 3 "NotUsed" 1 "Enabled" 0 "Disabled" ;
VAL_ 1077 PrkAidFront_D_RqDrv 2 "Status" 3 "NotUsed" 1 "Enabled" 0 "Disabled" ;
VAL_ 1077 PrkAidRear_D_RqDrv_UB 1 "Fresh_data" 0 "Unchanged_data" ;
VAL_ 1077 PrkAidFront_D_RqDrv_UB 1 "Fresh_data" 0 "Unchanged_data" ;
VAL_ 1077 Multimedia_System_UB 1 "Fresh_data" 0 "Unchanged_data" ;
VAL_ 1077 Multimedia_System 1 "On" 0 "Off" ;
VAL_ 1077 Remote_Start_Req_UB 1 "Fresh_data" 0 "Unchanged_data" ;
VAL_ 1077 Remote_Start_Req 3 "Not_Used" 2 "Remote_Cancel" 1 "Remote_Start" 0 "No_Request" ;
VAL_ 1077 TurnLampTrlrRr_B_Stat_UB 1 "Fresh_data" 0 "Unchanged_data" ;
VAL_ 1077 DistanceBarSetting_UB 1 "Fresh_data" 0 "Unchanged_data" ;
VAL_ 1077 CamraZoomMan_D_Rq_UB 1 "Fresh_data" 0 "Unchanged_data" ;
VAL_ 1077 CamraOvrlStat_D_Rq_UB 1 "Fresh_data" 0 "Unchanged_data" ;
VAL_ 1077 CamraOvrlDyn_D_Rq_UB 1 "Fresh_data" 0 "Unchanged_data" ;
VAL_ 1077 CamAutoTowbarZoom_UB 1 "Fresh_data" 0 "Unchanged_data" ;
VAL_ 1077 DistanceBarSetting 1 "On" 0 "Off" ;
VAL_ 1077 CamraZoomMan_D_Rq 7 "Unknown" 6 "Invalid" 5 "Zoom_Level_V" 4 "Zoom_Level_IV" 3 "Zoom_Level_III" 2 "Zoom_Level_II" 1 "Zoom_Level_I" 0 "Off" ;
VAL_ 1077 CamraOvrlStat_D_Rq 1 "On" 0 "Off" ;
VAL_ 1077 CamraOvrlDyn_D_Rq 1 "On" 0 "Off" ;
VAL_ 1077 CamAutoTowbarZoom 1 "On" 0 "Off" ;
VAL_ 1077 CcdMsgTxt_D_RqDsply 15 "Unused8" 14 "Unused7" 13 "Unused6" 12 "Unused5" 11 "Unused4" 10 "Unused3" 9 "Unused2" 8 "Unused1" 7 "Mode_Change_Unavailable" 6 "CCD_Temporarily_Off" 5 "CCD_Service_Required" 4 "Fault" 3 "Sport" 2 "Normal" 1 "Comfort" 0 "No_Mode_Selected" ;
VAL_ 1077 PwLftgtIntSw_B_Stat_UB 1 "Fresh_data" 0 "Unchanged_data" ;
VAL_ 1077 PwLftgtIntSw_B_Stat 1 "Pressed" 0 "Null" ;
VAL_ 1077 TurnLampTrlrRl_B_Stat_UB 1 "Fresh_data" 0 "Unchanged_data" ;
VAL_ 1077 TurnLampTrlrRr_B_Stat 1 "Out" 0 "Null" ;
VAL_ 1077 TurnLampTrlrRl_B_Stat 1 "Out" 0 "Null" ;
VAL_ 862 TwHlGrdAsst_B_RqTrn 1 "On" 0 "Off" ;
VAL_ 862 ApaSwtch_D_RqDrv 3 "Faulty" 2 "Stuck" 1 "Pressed" 0 "NotPressed" ;
VAL_ 862 HvacBlwrFront_D_Stat 31 "Not_Used" 20 "Full_On" 19 "95_Percent" 18 "90_Percent" 17 "85_Percent" 16 "80_Percent" 15 "75_Percent" 14 "70_Percent" 13 "65_Percent" 12 "60_Percent" 11 "55_Percent" 10 "50_Percent" 9 "45_Percent" 8 "40_Percent" 7 "35_Percent" 6 "30_Percent" 5 "25_Percent" 4 "20_Percent" 3 "15_Percent" 2 "10_Percent" 1 "5_Percent" 0 "Off" ;
VAL_ 862 HvacBlwrRear_D_Stat 31 "Not_Used" 20 "Full_On" 19 "95_Percent" 18 "90_Percent" 17 "85_Percent" 16 "80_Percent" 15 "75_Percent" 14 "70_Percent" 13 "65_Percent" 12 "60_Percent" 11 "55_Percent" 10 "50_Percent" 9 "45_Percent" 8 "40_Percent" 7 "35_Percent" 6 "30_Percent" 5 "25_Percent" 4 "20_Percent" 3 "15_Percent" 2 "10_Percent" 1 "5_Percent" 0 "Off" ;
VAL_ 862 ClimtThrmlLoad_No_Actl 255 "Fault" ;
VAL_ 862 AutoStpHvacDelta_I_Est 255 "Fault" ;
VAL_ 342 EngOil_Te_Actl 255 "Fault" 254 "Unknown" ;
VAL_ 342 EngOvrhtMitgActv_D_Ind 3 "Undefined" 2 "Mode2" 1 "Mode1" 0 "Normal_Mode" ;
VAL_ 342 EngClntTe_D_Qf 3 "OK" 2 "Not_Within_Specifications" 1 "No_Data_Exists" 0 "Faulty" ;
VAL_ 992 MsgCntrPersIndex_D_Rq 7 "Unused_3" 6 "Unused_2" 5 "Unused_1" 4 "Vehicle" 3 "PERS_4" 2 "PERS_3" 1 "PERS_2" 0 "PERS_1" ;
VAL_ 992 MsgCntrDsplyOp_D_Rq 7 "Unused_2" 6 "Unused_1" 5 "Copy" 4 "Restore" 3 "Upload" 2 "Set" 1 "Query" 0 "Null" ;
